VERSION ""

NS_ :

BS_:

BU_: SCCM RF_HUB PTS ORC OCM IC HCP HALF ETM ESM ESC EPS ECM EBCM DIAGNOST DASM CBC AirSusp TCM DTCM ELSDM

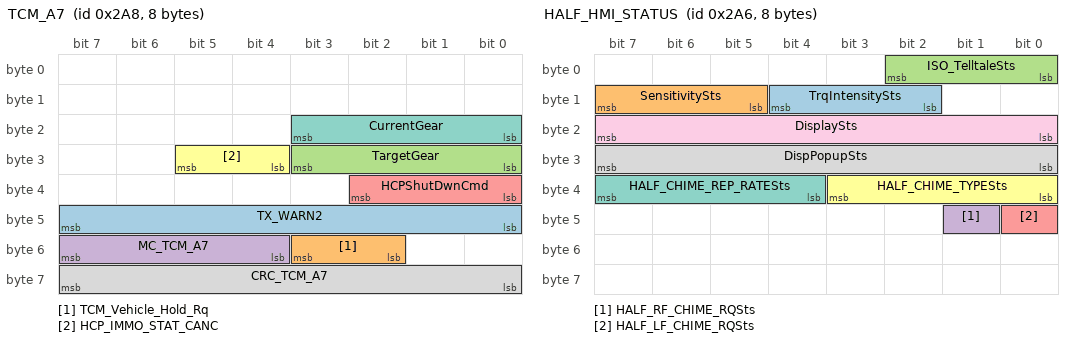
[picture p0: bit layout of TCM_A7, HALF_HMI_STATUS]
BO_ 680 TCM_A7: 8 TCM
 SG_ TX_WARN2 : 40|8@1+ (1,0) [0|0] ""  IC
 SG_ TCM_Vehicle_Hold_Rq : 50|2@1+ (1,0) [0|0] ""  ESC
 SG_ TargetGear : 24|4@1+ (1,0) [0|0] "" Vector__XXX
 SG_ MC_TCM_A7 : 52|4@1+ (1,0) [0|15] ""  ESC,ECM,DASM
 SG_ HCPShutDwnCmd : 32|3@1+ (1,0) [0|0] ""  CBC
 SG_ HCP_IMMO_STAT_CANC : 28|2@1+ (1,0) [0|0] ""  ECM,CBC
 SG_ CurrentGear : 16|4@1+ (1,0) [0|0] "" Vector__XXX
 SG_ CRC_TCM_A7 : 56|8@1+ (1,0) [0|0] ""  ESC,ECM,DASM

BO_ 678 HALF_HMI_STATUS: 8 HALF
 SG_ TrqIntensitySts : 10|3@1+ (1,0) [0|0] ""  IC
 SG_ SensitivitySts : 13|3@1+ (1,0) [0|0] ""  IC
 SG_ ISO_TelltaleSts : 0|3@1+ (1,0) [0|0] ""  ORC,IC
 SG_ HALF_RF_CHIME_RQSts : 41|1@1+ (1,0) [0|0] ""  CBC
 SG_ HALF_LF_CHIME_RQSts : 40|1@1+ (1,0) [0|0] ""  CBC
 SG_ HALF_CHIME_TYPESts : 32|4@1+ (1,0) [0|0] ""  CBC
 SG_ HALF_CHIME_REP_RATESts : 36|4@1+ (1,0) [0|15] ""  CBC
 SG_ DispPopupSts : 24|8@1+ (1,0) [0|0] ""  ORC,IC
 SG_ DisplaySts : 16|8@1+ (1,0) [0|0] ""  ORC,IC

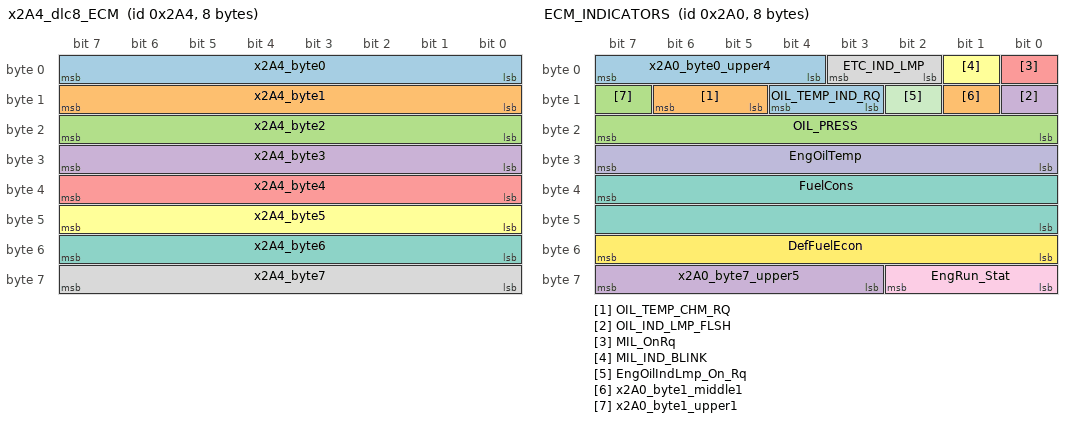
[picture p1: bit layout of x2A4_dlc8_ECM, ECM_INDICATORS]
BO_ 676 x2A4_dlc8_ECM: 8 ECM
 SG_ x2A4_byte0 : 0|8@1+ (1,0) [0|255] "" Vector__XXX
 SG_ x2A4_byte1 : 8|8@1+ (1,0) [0|255] "" Vector__XXX
 SG_ x2A4_byte2 : 16|8@1+ (1,0) [0|255] "" Vector__XXX
 SG_ x2A4_byte3 : 24|8@1+ (1,0) [0|255] "" Vector__XXX
 SG_ x2A4_byte4 : 32|8@1+ (1,0) [0|255] "" Vector__XXX
 SG_ x2A4_byte5 : 40|8@1+ (1,0) [0|255] "" Vector__XXX
 SG_ x2A4_byte6 : 48|8@1+ (1,0) [0|255] "" Vector__XXX
 SG_ x2A4_byte7 : 56|8@1+ (1,0) [0|255] "" Vector__XXX

BO_ 672 ECM_INDICATORS: 8 ECM
 SG_ OIL_TEMP_IND_RQ : 11|2@1+ (1,0) [0|0] ""  IC,ETM
 SG_ OIL_TEMP_CHM_RQ : 13|2@1+ (1,0) [0|0] ""  IC
 SG_ OIL_PRESS : 16|8@1+ (4,0) [0|1016] "kPaG"  IC,ETM
 SG_ OIL_IND_LMP_FLSH : 8|1@1+ (1,0) [0|0] ""  IC,ETM
 SG_ MIL_OnRq : 0|1@1+ (1,0) [0|0] ""  ORC,IC,ETM,CBC
 SG_ MIL_IND_BLINK : 1|1@1+ (1,0) [0|0] ""  ORC,IC,CBC
 SG_ FuelCons : 39|16@0+ (0.21668,0) [0|14200] "µl/100ms"  IC,ETM
 SG_ ETC_IND_LMP : 2|2@1+ (1,0) [0|0] ""  IC,ETM,CBC
 SG_ EngRun_Stat : 56|3@1+ (1,0) [0|0] ""  RF_HUB,PTS,IC,ESC,CBC
 SG_ EngOilTemp : 24|8@1+ (1,-40) [-40|160] "°C"  IC,ETM,EPS
 SG_ EngOilIndLmp_On_Rq : 10|1@1+ (1,0) [0|0] ""  IC,ETM,CBC
 SG_ DefFuelEcon : 48|8@1+ (0.2,0) [0|50] "kmpl"  IC
 SG_ x2A0_byte0_upper4 : 4|4@1+ (1,0) [0|0] "" Vector__XXX
 SG_ x2A0_byte1_middle1 : 9|1@1+ (1,0) [0|0] "" Vector__XXX
 SG_ x2A0_byte1_upper1 : 15|1@1+ (1,0) [0|0] "" Vector__XXX
 SG_ x2A0_byte7_upper5 : 59|5@1+ (1,0) [0|0] "" Vector__XXX

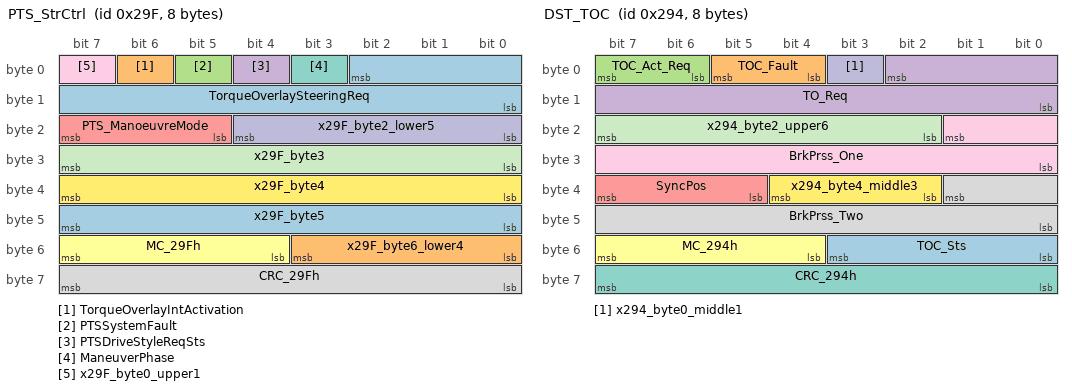
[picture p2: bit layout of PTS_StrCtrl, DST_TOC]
BO_ 671 PTS_StrCtrl: 8 PTS
 SG_ TorqueOverlaySteeringReq : 2|11@0+ (0.0078125,-8) [-8|7.9921875] "Nm"  EPS
 SG_ TorqueOverlayIntActivation : 6|1@1+ (1,0) [0|0] ""  EPS
 SG_ PTSSystemFault : 5|1@1+ (1,0) [0|0] ""  EPS
 SG_ PTSDriveStyleReqSts : 4|1@1+ (1,0) [0|0] ""  EPS
 SG_ PTS_ManoeuvreMode : 21|3@1+ (1,0) [0|0] ""  IC
 SG_ MC_29Fh : 52|4@1+ (1,0) [0|15] ""  EPS
 SG_ ManeuverPhase : 3|1@1+ (1,0) [0|0] ""  EPS
 SG_ CRC_29Fh : 56|8@1+ (1,0) [0|0] ""  EPS
 SG_ x29F_byte0_upper1 : 7|1@1+ (1,0) [0|1] "" Vector__XXX
 SG_ x29F_byte2_lower5 : 16|5@1+ (1,0) [0|31] "" Vector__XXX
 SG_ x29F_byte3 : 24|8@1+ (1,0) [0|255] "" Vector__XXX
 SG_ x29F_byte4 : 32|8@1+ (1,0) [0|255] "" Vector__XXX
 SG_ x29F_byte5 : 40|8@1+ (1,0) [0|255] "" Vector__XXX
 SG_ x29F_byte6_lower4 : 48|4@1+ (1,0) [0|15] "" Vector__XXX

BO_ 660 DST_TOC: 8 ESC
 SG_ TOC_Sts : 48|4@1+ (1,0) [0|0] ""  ORC,EPS
 SG_ TOC_Fault : 4|2@1+ (1,0) [0|0] ""  ORC,EPS
 SG_ TOC_Act_Req : 6|2@1+ (1,0) [0|0] ""  EPS
 SG_ TO_Req : 2|11@0+ (0.0078125,-8) [-8|7.984375] "Nm"  ORC,EPS
 SG_ SyncPos : 37|3@1+ (1,0) [0|0] "" Vector__XXX
 SG_ MC_294h : 52|4@1+ (1,0) [0|15] ""  EPS
 SG_ CRC_294h : 56|8@1+ (1,0) [0|0] ""  EPS
 SG_ BrkPrss_Two : 33|10@0+ (0.0048828125,0) [0|4.9951171875] "Volts" Vector__XXX
 SG_ BrkPrss_One : 17|10@0+ (0.0048828125,0) [0|4.9951171875] "Volts" Vector__XXX
 SG_ x294_byte0_middle1 : 3|1@1+ (1,0) [0|1] "" Vector__XXX
 SG_ x294_byte2_upper6 : 18|6@1+ (1,0) [0|63] "" Vector__XXX
 SG_ x294_byte4_middle3 : 34|3@1+ (1,0) [0|7] "" Vector__XXX

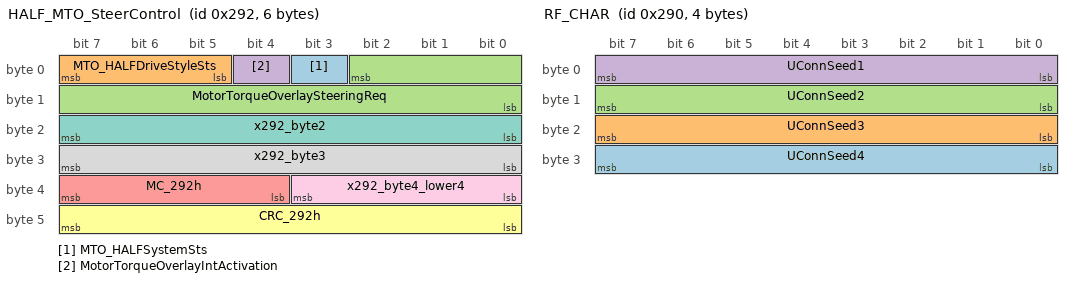
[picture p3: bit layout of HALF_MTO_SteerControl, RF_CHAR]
BO_ 658 HALF_MTO_SteerControl: 6 HALF
 SG_ MTO_HALFSystemSts : 3|1@1+ (1,0) [0|0] ""  EPS
 SG_ MTO_HALFDriveStyleSts : 5|3@1+ (1,0) [0|0] ""  EPS
 SG_ MotorTorqueOverlaySteeringReq : 2|11@0+ (0.001953125,-2) [-2|1.998047] "Nm"  EPS
 SG_ MotorTorqueOverlayIntActivation : 4|1@1+ (1,0) [0|0] ""  EPS
 SG_ MC_292h : 36|4@1+ (1,0) [0|15] ""  EPS
 SG_ CRC_292h : 40|8@1+ (1,0) [0|0] ""  EPS
 SG_ x292_byte2 : 16|8@1+ (1,0) [0|255] "" Vector__XXX
 SG_ x292_byte3 : 24|8@1+ (1,0) [0|255] "" Vector__XXX
 SG_ x292_byte4_lower4 : 32|4@1+ (1,0) [0|15] "" Vector__XXX

BO_ 656 RF_CHAR: 4 RF_HUB
 SG_ UConnSeed4 : 24|8@1+ (1,0) [0|0] ""  ETM
 SG_ UConnSeed3 : 16|8@1+ (1,0) [0|0] ""  ETM
 SG_ UConnSeed2 : 8|8@1+ (1,0) [0|0] ""  ETM
 SG_ UConnSeed1 : 0|8@1+ (1,0) [0|0] ""  ETM

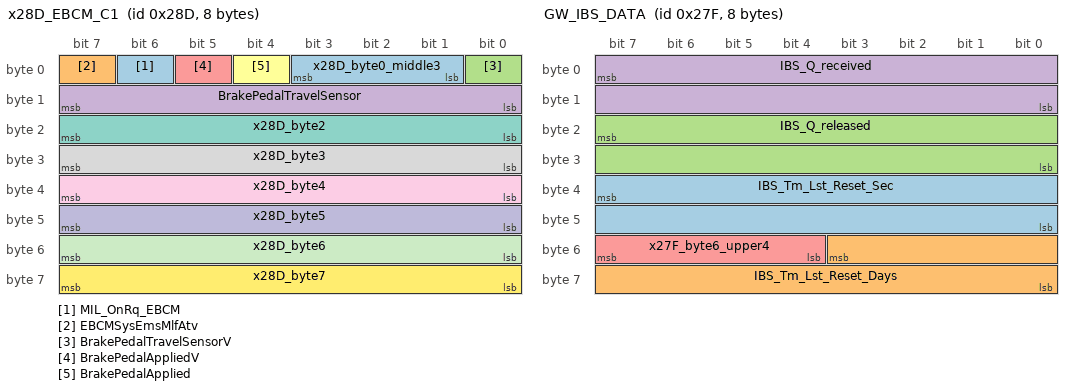
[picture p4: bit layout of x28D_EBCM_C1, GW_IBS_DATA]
BO_ 653 x28D_EBCM_C1: 8 EBCM
 SG_ MIL_OnRq_EBCM : 6|1@1+ (1,0) [0|0] ""  ECM
 SG_ EBCMSysEmsMlfAtv : 7|1@1+ (1,0) [0|0] "" Vector__XXX
 SG_ BrakePedalTravelSensorV : 0|1@1+ (1,0) [0|0] ""  ESC,ECM
 SG_ BrakePedalTravelSensor : 8|8@1+ (0.4,0) [0|100] "%"  ESC,ECM
 SG_ BrakePedalAppliedV : 5|1@1+ (1,0) [0|0] ""  ESC,ECM
 SG_ BrakePedalApplied : 4|1@1+ (1,0) [0|0] ""  ESC,ECM
 SG_ x28D_byte2 : 16|8@1+ (1,0) [0|0] "" Vector__XXX
 SG_ x28D_byte3 : 24|8@1+ (1,0) [0|0] "" Vector__XXX
 SG_ x28D_byte4 : 32|8@1+ (1,0) [0|0] "" Vector__XXX
 SG_ x28D_byte5 : 40|8@1+ (1,0) [0|0] "" Vector__XXX
 SG_ x28D_byte6 : 48|8@1+ (1,0) [0|0] "" Vector__XXX
 SG_ x28D_byte7 : 56|8@1+ (1,0) [0|0] "" Vector__XXX
 SG_ x28D_byte0_middle3 : 1|3@1+ (1,0) [0|0] "" Vector__XXX

BO_ 639 GW_IBS_DATA: 8 CBC
 SG_ IBS_Tm_Lst_Reset_Sec : 39|16@0+ (2,0) [0|86398] "sec" Vector__XXX
 SG_ IBS_Tm_Lst_Reset_Days : 51|12@0+ (1,0) [0|4094] "Days" Vector__XXX
 SG_ IBS_Q_released : 23|16@0+ (0.125,0) [0|8191.75] "Ah" Vector__XXX
 SG_ IBS_Q_received : 7|16@0+ (0.125,0) [0|8191.75] "Ah" Vector__XXX
 SG_ x27F_byte6_upper4 : 55|4@0+ (1,0) [0|15] "" Vector__XXX

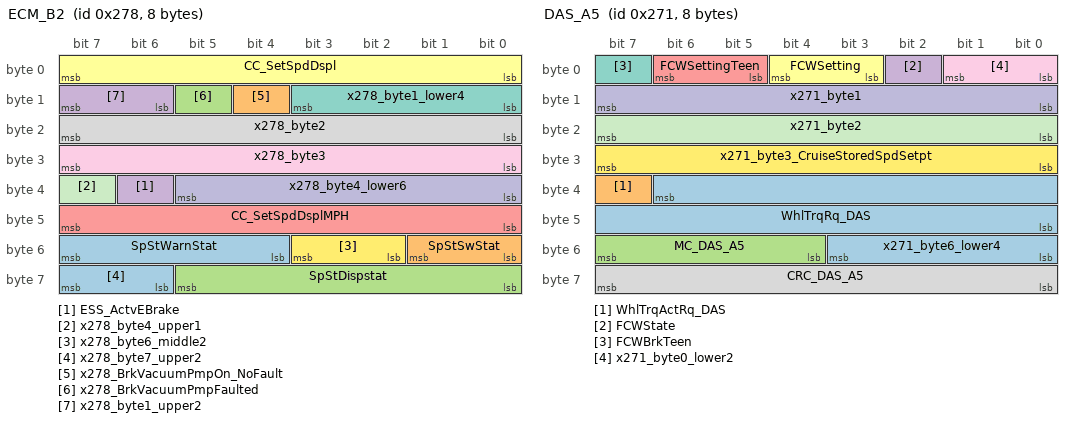
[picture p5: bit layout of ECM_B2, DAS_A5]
BO_ 632 ECM_B2: 8 ECM
 SG_ SpStWarnStat : 52|4@1+ (1,0) [0|0] ""  ORC
 SG_ SpStSwStat : 48|2@1+ (1,0) [0|0] ""  ORC,CBC
 SG_ SpStDispstat : 56|6@1+ (1,0) [0|0] ""  ORC
 SG_ ESS_ActvEBrake : 38|1@1+ (1,0) [0|0] ""  ORC,ESC
 SG_ CC_SetSpdDsplMPH : 40|8@1+ (1,0) [0|254] "mph"  IC
 SG_ CC_SetSpdDspl : 0|8@1+ (1,0) [0|250] "km/h"  IC
 SG_ x278_byte1_lower4 : 8|4@1+ (1,0) [0|15] "" Vector__XXX
 SG_ x278_byte2 : 16|8@1+ (1,0) [0|255] "" Vector__XXX
 SG_ x278_byte3 : 24|8@1+ (1,0) [0|255] "" Vector__XXX
 SG_ x278_byte4_lower6 : 32|6@1+ (1,0) [0|63] "" Vector__XXX
 SG_ x278_byte4_upper1 : 39|1@1+ (1,0) [0|1] "" Vector__XXX
 SG_ x278_byte6_middle2 : 50|2@1+ (1,0) [0|3] "" Vector__XXX
 SG_ x278_byte7_upper2 : 62|2@1+ (1,0) [0|3] "" Vector__XXX
 SG_ x278_BrkVacuumPmpOn_NoFault : 12|1@1+ (1,0) [0|1] "" Vector__XXX
 SG_ x278_BrkVacuumPmpFaulted : 13|1@1+ (1,0) [0|1] "" Vector__XXX
 SG_ x278_byte1_upper2 : 14|2@1+ (1,0) [0|3] "" Vector__XXX

BO_ 625 DAS_A5: 8 DASM
 SG_ WhlTrqRq_DAS : 38|15@0+ (1,-7767) [-7767|24999] "Nm"  ESC
 SG_ WhlTrqActRq_DAS : 39|1@1+ (1,0) [0|0] ""  ESC
 SG_ MC_DAS_A5 : 52|4@1+ (1,0) [0|15] ""  ESC
 SG_ FCWState : 2|1@1+ (1,0) [0|0] ""  ORC,IC,CBC
 SG_ FCWSettingTeen : 5|2@1+ (1,0) [0|0] ""  ORC,CBC
 SG_ FCWSetting : 3|2@1+ (1,0) [0|0] ""  ORC,CBC
 SG_ FCWBrkTeen : 7|1@1+ (1,0) [0|0] ""  ORC,CBC
 SG_ CRC_DAS_A5 : 56|8@1+ (1,0) [0|255] ""  ESC
 SG_ x271_byte0_lower2 : 0|2@1+ (1,0) [0|2] "" Vector__XXX
 SG_ x271_byte1 : 8|8@1+ (1,0) [0|255] "" Vector__XXX
 SG_ x271_byte2 : 16|8@1+ (1,0) [0|255] "" Vector__XXX
 SG_ x271_byte3_CruiseStoredSpdSetpt : 24|8@1+ (1,0) [0|255] "kph" Vector__XXX
 SG_ x271_byte6_lower4 : 48|4@1+ (1,0) [0|15] "" Vector__XXX

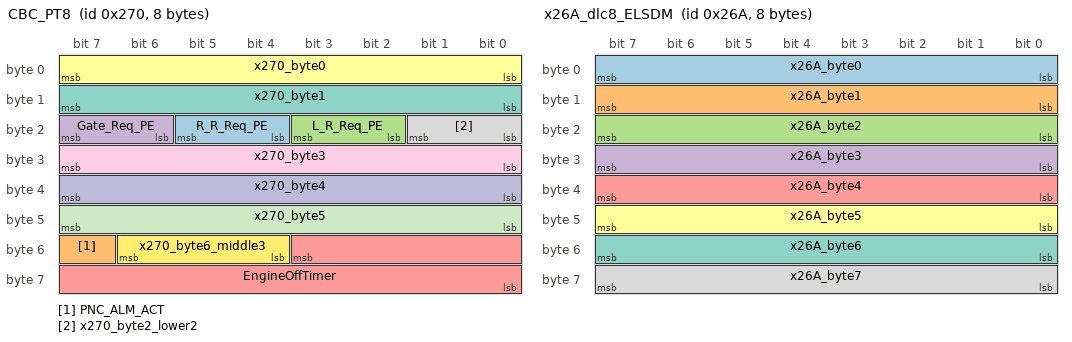
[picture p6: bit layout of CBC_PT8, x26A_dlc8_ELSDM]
BO_ 624 CBC_PT8: 8 CBC
 SG_ R_R_Req_PE : 20|2@1+ (1,0) [0|0] ""  RF_HUB
 SG_ PNC_ALM_ACT : 55|1@1+ (1,0) [0|0] "" Vector__XXX
 SG_ L_R_Req_PE : 18|2@1+ (1,0) [0|0] ""  RF_HUB
 SG_ Gate_Req_PE : 22|2@1+ (1,0) [0|0] ""  RF_HUB
 SG_ EngineOffTimer : 51|12@0+ (1,0) [0|4080] "min"  ETM,ECM
 SG_ x270_byte0 : 0|8@1+ (1,0) [0|255] "" Vector__XXX
 SG_ x270_byte1 : 8|8@1+ (1,0) [0|255] "" Vector__XXX
 SG_ x270_byte2_lower2 : 16|2@1+ (1,0) [0|3] "" Vector__XXX
 SG_ x270_byte3 : 24|8@1+ (1,0) [0|255] "" Vector__XXX
 SG_ x270_byte4 : 32|8@1+ (1,0) [0|255] "" Vector__XXX
 SG_ x270_byte5 : 40|8@1+ (1,0) [0|255] "" Vector__XXX
 SG_ x270_byte6_middle3 : 52|3@1+ (1,0) [0|7] "" Vector__XXX

BO_ 618 x26A_dlc8_ELSDM: 8 ELSDM
 SG_ x26A_byte0 : 0|8@1+ (1,0) [0|255] "" Vector__XXX
 SG_ x26A_byte1 : 8|8@1+ (1,0) [0|255] "" Vector__XXX
 SG_ x26A_byte2 : 16|8@1+ (1,0) [0|255] "" Vector__XXX
 SG_ x26A_byte3 : 24|8@1+ (1,0) [0|255] "" Vector__XXX
 SG_ x26A_byte4 : 32|8@1+ (1,0) [0|255] "" Vector__XXX
 SG_ x26A_byte5 : 40|8@1+ (1,0) [0|255] "" Vector__XXX
 SG_ x26A_byte6 : 48|8@1+ (1,0) [0|255] "" Vector__XXX
 SG_ x26A_byte7 : 56|8@1+ (1,0) [0|255] "" Vector__XXX

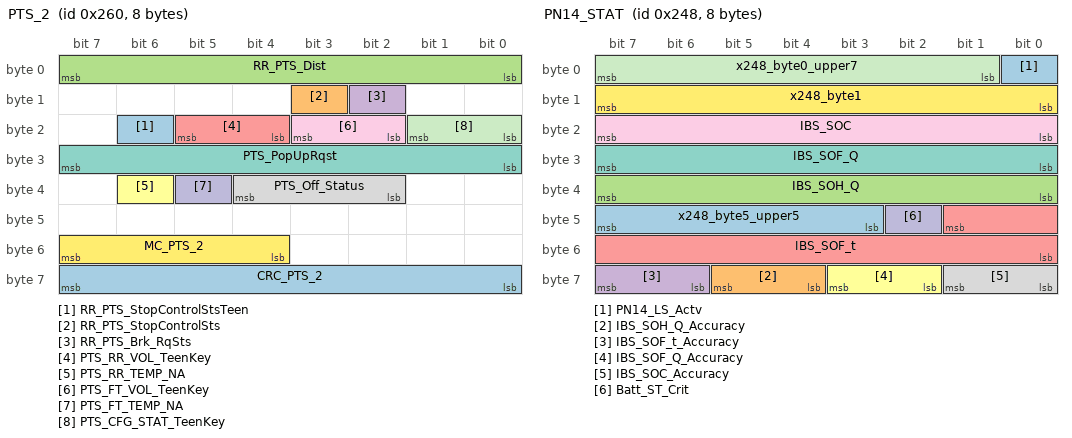
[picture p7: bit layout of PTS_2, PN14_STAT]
BO_ 608 PTS_2: 8 PTS
 SG_ RR_PTS_StopControlStsTeen : 22|1@1+ (1,0) [0|0] ""  IC,CBC
 SG_ RR_PTS_StopControlSts : 11|1@1+ (1,0) [0|0] ""  IC,CBC
 SG_ RR_PTS_Dist : 0|8@1+ (1,0) [0|254] "cm"  ESC
 SG_ RR_PTS_Brk_RqSts : 10|1@1+ (1,0) [0|0] ""  ESC
 SG_ PTS_RR_VOL_TeenKey : 20|2@1+ (1,0) [0|0] ""  CBC
 SG_ PTS_RR_TEMP_NA : 38|1@1+ (1,0) [0|0] ""  IC
 SG_ PTS_PopUpRqst : 24|8@1+ (1,0) [0|0] ""  IC
 SG_ PTS_Off_Status : 34|3@1+ (1,0) [0|0] ""  IC
 SG_ PTS_FT_VOL_TeenKey : 18|2@1+ (1,0) [0|0] ""  CBC
 SG_ PTS_FT_TEMP_NA : 37|1@1+ (1,0) [0|0] ""  IC
 SG_ PTS_CFG_STAT_TeenKey : 16|2@1+ (1,0) [0|0] ""  CBC
 SG_ MC_PTS_2 : 52|4@1+ (1,0) [0|15] ""  ESC
 SG_ CRC_PTS_2 : 56|8@1+ (1,0) [0|0] ""  ESC

BO_ 584 PN14_STAT: 8 CBC
 SG_ PN14_LS_Actv : 0|1@1+ (1,0) [0|0] ""  IC
 SG_ IBS_SOH_Q_Accuracy : 60|2@1+ (1,0) [0|0] "" Vector__XXX
 SG_ IBS_SOH_Q : 32|8@1+ (0.5,0) [0|127] "Ah" Vector__XXX
 SG_ IBS_SOF_t_Accuracy : 62|2@1+ (1,0) [0|0] "" Vector__XXX
 SG_ IBS_SOF_t : 41|10@0+ (1,0) [0|1022] "min" Vector__XXX
 SG_ IBS_SOF_Q_Accuracy : 58|2@1+ (1,0) [0|0] "" Vector__XXX
 SG_ IBS_SOF_Q : 24|8@1+ (0.5,0) [0|127] "Ah" Vector__XXX
 SG_ IBS_SOC_Accuracy : 56|2@1+ (1,0) [0|0] ""  HCP
 SG_ IBS_SOC : 16|8@1+ (1,0) [0|100] "%"  ORC,HCP,ETM
 SG_ Batt_ST_Crit : 42|1@1+ (1,0) [0|0] ""  IC
 SG_ x248_byte0_upper7 : 1|7@1+ (1,0) [0|127] "" Vector__XXX
 SG_ x248_byte1 : 8|8@1+ (1,0) [0|255] "" Vector__XXX
 SG_ x248_byte5_upper5 : 43|5@1+ (1,0) [0|31] "" Vector__XXX

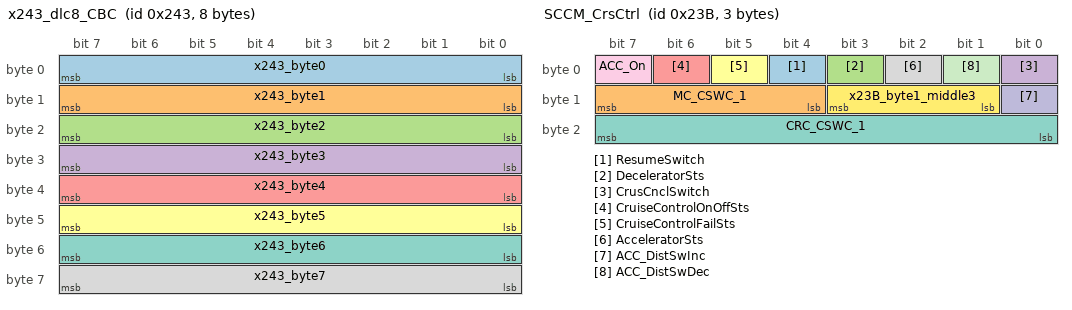
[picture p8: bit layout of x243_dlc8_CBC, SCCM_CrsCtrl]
BO_ 579 x243_dlc8_CBC: 8 CBC
 SG_ x243_byte0 : 0|8@1+ (1,0) [0|255] "" Vector__XXX
 SG_ x243_byte1 : 8|8@1+ (1,0) [0|255] "" Vector__XXX
 SG_ x243_byte2 : 16|8@1+ (1,0) [0|255] "" Vector__XXX
 SG_ x243_byte3 : 24|8@1+ (1,0) [0|255] "" Vector__XXX
 SG_ x243_byte4 : 32|8@1+ (1,0) [0|255] "" Vector__XXX
 SG_ x243_byte5 : 40|8@1+ (1,0) [0|255] "" Vector__XXX
 SG_ x243_byte6 : 48|8@1+ (1,0) [0|255] "" Vector__XXX
 SG_ x243_byte7 : 56|8@1+ (1,0) [0|255] "" Vector__XXX

BO_ 571 SCCM_CrsCtrl: 3 SCCM
 SG_ ResumeSwitch : 4|1@1+ (1,0) [0|0] ""  ESC,ECM,DASM
 SG_ MC_CSWC_1 : 12|4@1+ (1,0) [0|15] ""  ECM
 SG_ DeceleratorSts : 3|1@1+ (1,0) [0|0] ""  ESC,ECM,DASM
 SG_ CrusCnclSwitch : 0|1@1+ (1,0) [0|0] ""  ESC,ECM,DASM
 SG_ CruiseControlOnOffSts : 6|1@1+ (1,0) [0|0] ""  ESC,ECM,DASM
 SG_ CruiseControlFailSts : 5|1@1+ (1,0) [0|0] ""  ESC,ECM,DASM
 SG_ CRC_CSWC_1 : 16|8@1+ (1,0) [0|0] ""  ECM
 SG_ AcceleratorSts : 2|1@1+ (1,0) [0|0] ""  ESC,ECM,DASM
 SG_ ACC_On : 7|1@1+ (1,0) [0|0] ""  ESC,DASM
 SG_ ACC_DistSwInc : 8|1@1+ (1,0) [0|0] ""  DASM
 SG_ ACC_DistSwDec : 1|1@1+ (1,0) [0|0] ""  DASM
 SG_ x23B_byte1_middle3 : 9|3@1+ (1,0) [0|7] "" Vector__XXX

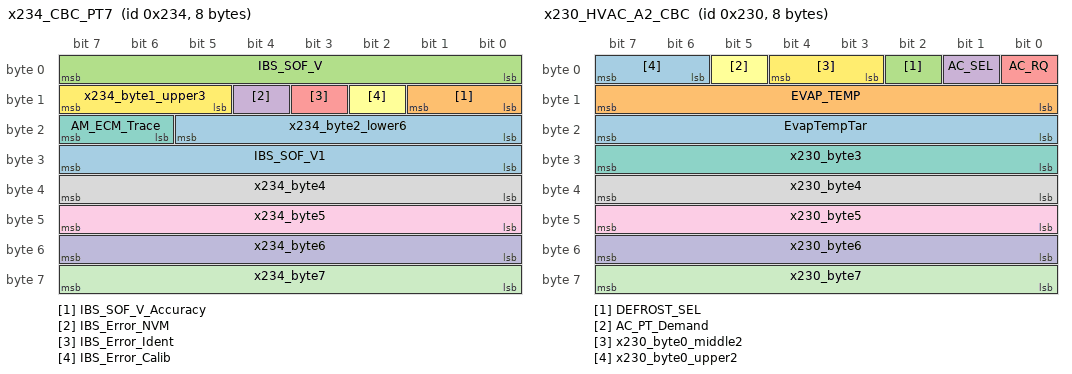
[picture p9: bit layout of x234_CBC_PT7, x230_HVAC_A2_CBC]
BO_ 564 x234_CBC_PT7: 8 CBC
 SG_ IBS_SOF_V1 : 24|8@1+ (0.0625,0) [0|15.875] "V" Vector__XXX
 SG_ IBS_SOF_V_Accuracy : 8|2@1+ (1,0) [0|0] "" Vector__XXX
 SG_ IBS_SOF_V : 0|8@1+ (0.0625,0) [0|15.875] "V" Vector__XXX
 SG_ IBS_Error_NVM : 12|1@1+ (1,0) [0|0] "" Vector__XXX
 SG_ IBS_Error_Ident : 11|1@1+ (1,0) [0|0] "" Vector__XXX
 SG_ IBS_Error_Calib : 10|1@1+ (1,0) [0|0] "" Vector__XXX
 SG_ AM_ECM_Trace : 22|2@1+ (1,0) [0|0] ""  ECM
 SG_ x234_byte4 : 32|8@1+ (1,0) [0|255] "" Vector__XXX
 SG_ x234_byte5 : 40|8@1+ (1,0) [0|255] "" Vector__XXX
 SG_ x234_byte6 : 48|8@1+ (1,0) [0|255] "" Vector__XXX
 SG_ x234_byte7 : 56|8@1+ (1,0) [0|255] "" Vector__XXX
 SG_ x234_byte1_upper3 : 13|3@1+ (1,0) [0|7] "" Vector__XXX
 SG_ x234_byte2_lower6 : 16|6@1+ (1,0) [0|63] "" Vector__XXX

BO_ 560 x230_HVAC_A2_CBC: 8 CBC
 SG_ EvapTempTar : 16|8@1+ (0.5,-20) [-20|107] "°C"  HCP
 SG_ EVAP_TEMP : 8|8@1+ (0.5,-20) [-20|107] "°C"  HCP
 SG_ DEFROST_SEL : 2|1@1+ (1,0) [0|0] "" Vector__XXX
 SG_ AC_SEL : 1|1@1+ (1,0) [0|0] "" Vector__XXX
 SG_ AC_RQ : 0|1@1+ (1,0) [0|0] ""  HCP
 SG_ AC_PT_Demand : 5|1@1+ (1,0) [0|0] ""  ECM
 SG_ x230_byte3 : 24|8@1+ (1,0) [0|255] "" Vector__XXX
 SG_ x230_byte4 : 32|8@1+ (1,0) [0|255] "" Vector__XXX
 SG_ x230_byte5 : 40|8@1+ (1,0) [0|255] "" Vector__XXX
 SG_ x230_byte6 : 48|8@1+ (1,0) [0|255] "" Vector__XXX
 SG_ x230_byte7 : 56|8@1+ (1,0) [0|255] "" Vector__XXX
 SG_ x230_byte0_middle2 : 3|2@1+ (1,0) [0|0] "" Vector__XXX
 SG_ x230_byte0_upper2 : 6|2@1+ (1,0) [0|0] "" Vector__XXX

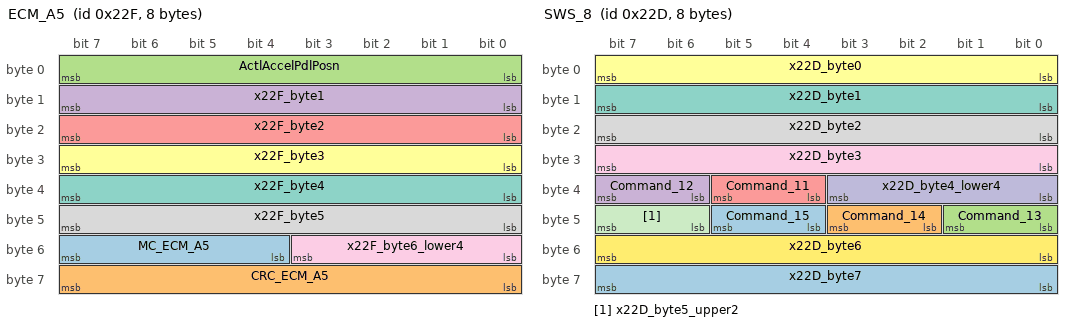
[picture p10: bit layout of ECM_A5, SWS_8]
BO_ 559 ECM_A5: 8 ECM
 SG_ MC_ECM_A5 : 52|4@1+ (1,0) [0|15] ""  ESC,DASM
 SG_ CRC_ECM_A5 : 56|8@1+ (1,0) [0|0] ""  ESC,DASM
 SG_ ActlAccelPdlPosn : 0|8@1+ (0.4,0) [0|100] "%"  ORC,HALF,ESC,DASM
 SG_ x22F_byte1 : 8|8@1+ (1,0) [0|0] "" Vector__XXX
 SG_ x22F_byte2 : 16|8@1+ (1,0) [0|0] "" Vector__XXX
 SG_ x22F_byte3 : 24|8@1+ (1,0) [0|0] "" Vector__XXX
 SG_ x22F_byte4 : 32|8@1+ (1,0) [0|0] "" Vector__XXX
 SG_ x22F_byte5 : 40|8@1+ (1,0) [0|0] "" Vector__XXX
 SG_ x22F_byte6_lower4 : 48|4@1+ (1,0) [0|0] "" Vector__XXX

BO_ 557 SWS_8: 8 CBC
 SG_ Command_15 : 44|2@1+ (1,0) [0|0] ""  IC
 SG_ Command_14 : 42|2@1+ (1,0) [0|0] ""  IC
 SG_ Command_13 : 40|2@1+ (1,0) [0|0] ""  IC
 SG_ Command_12 : 38|2@1+ (1,0) [0|0] ""  IC
 SG_ Command_11 : 36|2@1+ (1,0) [0|0] ""  IC
 SG_ x22D_byte0 : 0|8@1+ (1,0) [0|255] "" Vector__XXX
 SG_ x22D_byte1 : 8|8@1+ (1,0) [0|255] "" Vector__XXX
 SG_ x22D_byte2 : 16|8@1+ (1,0) [0|255] "" Vector__XXX
 SG_ x22D_byte3 : 24|8@1+ (1,0) [0|255] "" Vector__XXX
 SG_ x22D_byte4_lower4 : 32|4@1+ (1,0) [0|15] "" Vector__XXX
 SG_ x22D_byte5_upper2 : 46|2@1+ (1,0) [0|3] "" Vector__XXX
 SG_ x22D_byte6 : 48|8@1+ (1,0) [0|255] "" Vector__XXX
 SG_ x22D_byte7 : 56|8@1+ (1,0) [0|255] "" Vector__XXX

BO_ 544 EPS_1: 8 EPS
 SG_ TOI_Act_Sts : 3|4@1+ (1,0) [0|0] ""  ORC,ESC
 SG_ StrClmTrqVD : 7|1@1+ (1,0) [0|0] ""  HALF,ECM,ESC,PTS
 SG_ StrClmTrq : 2|11@0+ (0.0078125,-8) [-8|7.98] "Nm"  PTS,ORC,HALF,ESC,ECM
 SG_ PTSTorqueOverlayIntActivated : 51|1@1+ (1,0) [0|0] ""  PTS
 SG_ PTSTorqueOverlayFault : 50|1@1+ (1,0) [0|0] ""  PTS
 SG_ PTSDriveStyleSts : 20|1@1+ (1,0) [0|0] ""  PTS
 SG_ MC_EPS_1 : 52|4@1+ (1,0) [0|15] ""  HALF,ECM,ESC,PTS
 SG_ HALFTorqueOverlayIntActivated : 23|1@1+ (1,0) [0|0] ""  ORC,HALF
 SG_ HALFTorqueOverlayFault : 22|1@1+ (1,0) [0|0] ""  HALF
 SG_ EPSTemporaryDeactivationPPPA : 49|1@1+ (1,0) [0|0] ""  PTS
 SG_ EPSTemporaryDeactivationLDW : 38|1@1+ (1,0) [0|0] ""  HALF
 SG_ EPSMotorTorqueValidData : 39|1@1+ (1,0) [0|0] ""  HALF
 SG_ EPSMotorTorque : 34|11@0+ (0.001953125,-2) [-2|1.998047] "Nm"  ORC,HALF
 SG_ EPSHandsOnRecognition : 48|1@1+ (1,0) [0|0] ""  PTS
 SG_ DSTTorqueOverlayIntActivated : 37|1@1+ (1,0) [0|0] ""  HALF,ESC
 SG_ DSTTorqueOverlayFault : 21|1@1+ (1,0) [0|0] ""  HALF,ESC
 SG_ CRC_EPS_1 : 56|8@1+ (1,0) [0|0] ""  HALF,ECM,ESC,PTS
 SG_ AssistanceTorque : 19|12@0+ (0.05,-100) [-100|104.65] "Nm"  ESC
 SG_ x220_byte4_middle2 : 35|2@1+ (1,0) [0|3] "" Vector__XXX

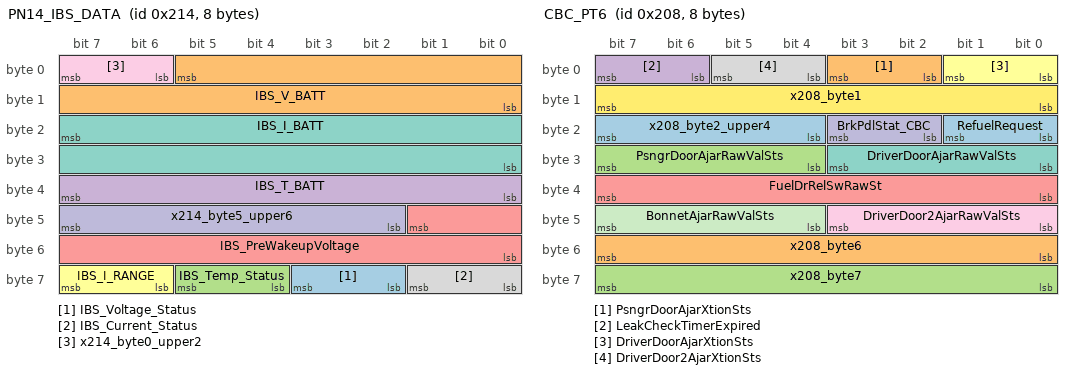
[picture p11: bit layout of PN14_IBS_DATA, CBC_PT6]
BO_ 532 PN14_IBS_DATA: 8 CBC
 SG_ IBS_Voltage_Status : 58|2@1+ (1,0) [0|0] ""  HCP
 SG_ IBS_V_BATT : 5|14@0+ (0.0009765625,3) [3|18] "Volts"  ORC,HCP,ETM
 SG_ IBS_Temp_Status : 60|2@1+ (1,0) [0|0] ""  HCP
 SG_ IBS_T_BATT : 32|8@1+ (1,-40) [-40|105] "°C"  HCP,ETM
 SG_ IBS_PreWakeupVoltage : 41|10@0+ (0.01,5) [5|15] "V" Vector__XXX
 SG_ IBS_I_RANGE : 62|2@1+ (1,0) [0|0] "Amp" Vector__XXX
 SG_ IBS_I_BATT : 23|16@0+ (1,-32768) [-32768|32766] "I_RANGE res." Vector__XXX
 SG_ IBS_Current_Status : 56|2@1+ (1,0) [0|0] "" Vector__XXX
 SG_ x214_byte0_upper2 : 6|2@1+ (1,0) [0|3] "" Vector__XXX
 SG_ x214_byte5_upper6 : 42|6@1+ (1,0) [0|63] "" Vector__XXX

BO_ 520 CBC_PT6: 8 CBC
 SG_ RefuelRequest : 16|2@1+ (1,0) [0|0] ""  ECM
 SG_ PsngrDoorAjarXtionSts : 2|2@1+ (1,0) [0|0] "" Vector__XXX
 SG_ PsngrDoorAjarRawValSts : 28|4@1+ (1,0) [0|0] ""  ORC,ECM
 SG_ LeakCheckTimerExpired : 6|2@1+ (1,0) [0|0] ""  ECM
 SG_ FuelDrRelSwRawSt : 32|8@1+ (0.019607843,0) [0|4.98] "Volts"  ECM
 SG_ DriverDoorAjarXtionSts : 0|2@1+ (1,0) [0|0] ""  ESC,ECM
 SG_ DriverDoorAjarRawValSts : 24|4@1+ (1,0) [0|0] ""  ORC,ESC,ECM
 SG_ DriverDoor2AjarXtionSts : 4|2@1+ (1,0) [0|0] ""  ECM
 SG_ DriverDoor2AjarRawValSts : 40|4@1+ (1,0) [0|0] ""  ORC,ECM
 SG_ BrkPdlStat_CBC : 18|2@1+ (1,0) [0|0] ""  RF_HUB
 SG_ BonnetAjarRawValSts : 44|4@1+ (1,0) [0|0] ""  ORC,ECM
 SG_ x208_byte1 : 8|8@1+ (1,0) [0|255] "" Vector__XXX
 SG_ x208_byte2_upper4 : 20|4@1+ (1,0) [0|15] "" Vector__XXX
 SG_ x208_byte6 : 48|8@1+ (1,0) [0|255] "" Vector__XXX
 SG_ x208_byte7 : 56|8@1+ (1,0) [0|255] "" Vector__XXX

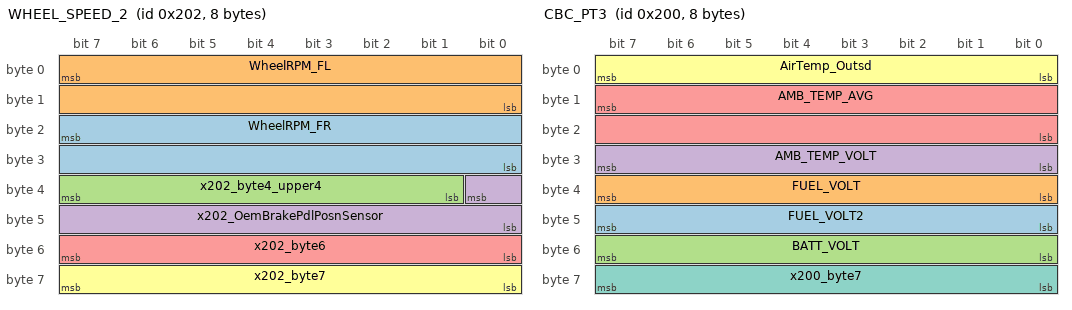
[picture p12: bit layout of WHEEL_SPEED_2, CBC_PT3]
BO_ 514 WHEEL_SPEED_2: 8 ESC
 SG_ WheelRPM_FR : 23|16@0+ (0.001953125,0) [0|127.9961] "Rev/s"  EPS
 SG_ WheelRPM_FL : 7|16@0+ (0.001953125,0) [0|127.9961] "Rev/s"  EPS
 SG_ x202_byte4_upper4 : 39|7@0+ (1,0) [0|15] "" Vector__XXX
 SG_ x202_OemBrakePdlPosnSensor : 32|9@0+ (0.0048261802575,0) [0|5] "V" Vector__XXX
 SG_ x202_byte6 : 55|8@0+ (1,0) [0|255] "" Vector__XXX
 SG_ x202_byte7 : 63|8@0+ (1,0) [0|255] "" Vector__XXX

BO_ 512 CBC_PT3: 8 CBC
 SG_ FUEL_VOLT2 : 40|8@1+ (0.019607843,0) [0|4.98] "Volts"  IC
 SG_ FUEL_VOLT : 32|8@1+ (0.019607843,0) [0|4.98] "Volts"  IC,ECM
 SG_ BATT_VOLT : 48|8@1+ (0.1,0) [5|18] "Volts"  SCCM,RF_HUB,PTS,ORC,OCM,IC,HCP,HALF,ESM,ESC,EPS,ECM,EBCM,DASM
 SG_ AMB_TEMP_VOLT : 24|8@1+ (0.019607843,0) [0|4.98] "Volts"  HCP,ECM
 SG_ AMB_TEMP_AVG : 15|16@0+ (0.01,-40) [-40|85] "°C"  RF_HUB,PTS,OCM,ESC,EPS,ECM,DASM
 SG_ AirTemp_Outsd : 0|8@1+ (0.5,-40) [-40|85] "°C"  RF_HUB,EPS,ECM,DASM
 SG_ x200_byte7 : 56|8@1+ (1,0) [0|255] "" Vector__XXX

BO_ 501 DAS_A4: 8 DASM
 SG_ Sm_ICON_Dspl : 40|6@1+ (1,0) [0|0] ""  IC
 SG_ SetSpeed_MPH : 16|8@1+ (1,0) [0|250] "mph"  ORC,IC
 SG_ SetSpeed_KPH : 8|8@1+ (1,0) [0|250] "km/h"  IC,ECM
 SG_ RadarBlocked : 46|1@1+ (1,0) [0|0] ""  ORC,IC
 SG_ ObjIntrstDist : 56|8@1+ (1,0) [0|253] "m"  ORC
 SG_ NCConlyNA_DASMSts : 49|1@1+ (1,0) [0|0] ""  IC
 SG_ NCCNA_DASMSts : 53|1@1+ (1,0) [0|0] ""  IC
 SG_ HMI_Screens : 0|8@1+ (1,0) [0|254] "Text"  ORC,IC
 SG_ FCWonlyNA_DASMSts : 51|1@1+ (1,0) [0|0] ""  IC
 SG_ FCWBrakingOff : 47|1@1+ (1,0) [0|0] ""  IC
 SG_ FCW_Error : 26|2@1+ (1,0) [0|0] ""  ORC,IC
 SG_ FCW_BrkOn : 29|1@1+ (1,0) [0|0] ""  ORC,CBC
 SG_ CIPV_Fused : 30|1@1+ (1,0) [0|0] ""  ORC
 SG_ CameraFailure : 55|1@1+ (1,0) [0|0] ""  IC
 SG_ CameraBlocked : 54|1@1+ (1,0) [0|0] ""  IC
 SG_ ACCOnOff : 36|3@1+ (1,0) [0|0] ""  ORC,IC
 SG_ ACConlyNA_DASMSts : 48|1@1+ (1,0) [0|0] ""  IC,ETM
 SG_ ACCNA_DASMSts : 52|1@1+ (1,0) [0|0] ""  IC
 SG_ ACCFaulted : 50|1@1+ (1,0) [0|0] ""  ORC,IC,ETM
 SG_ ACC_HMI_SCRN_REQ : 31|1@1+ (1,0) [0|0] ""  IC
 SG_ x1F5_byte3_lower2 : 24|2@1+ (1,0) [0|3] "" Vector__XXX
 SG_ x1F5_byte3_middle1 : 28|1@1+ (1,0) [0|1] "" Vector__XXX
 SG_ x1F5_byte4_lower4 : 32|4@1+ (1,0) [0|15] "" Vector__XXX
 SG_ x1F5_byte4_upper1 : 39|1@1+ (1,0) [0|1] "" Vector__XXX

BO_ 500 DAS_A3: 8 DASM
 SG_ MC_DAS_A3 : 52|4@1+ (1,0) [0|15] ""  ESC,ECM
 SG_ DsblFuelShutOff_ACC : 23|1@1+ (1,0) [0|0] ""  ESC
 SG_ DAS_Sts : 46|2@1+ (1,0) [0|0] ""  ESC
 SG_ DAS_Rq_ID : 36|3@1+ (1,0) [0|0] ""  ESC
 SG_ DAS_ACCEL_Rq : 19|12@0+ (0.004885,-16) [-16|4] "m/s²"  ORC,ESC
 SG_ CRC_DAS_A3 : 56|8@1+ (1,0) [0|0] ""  ESC
 SG_ Brk_PreFill_Rq : 49|1@1+ (1,0) [0|0] ""  ESC
 SG_ Brk_Jrk_Rq : 48|1@1+ (1,0) [0|0] ""  ESC
 SG_ As_DispRq : 50|2@1+ (1,0) [0|0] ""  ORC,IC,HALF,ESC
 SG_ ACCFCW_ChimeRq : 39|1@1+ (1,0) [0|0] ""  IC
 SG_ ACC_Still_Cmd : 5|1@1+ (1,0) [0|0] ""  ORC,ESC
 SG_ ACC_Engd : 21|1@1+ (1,0) [0|0] ""  IC,ESC
 SG_ ACC_Enbl : 20|1@1+ (1,0) [0|0] ""  IC,ESC
 SG_ ACC_Drive_Cmd : 6|1@1+ (1,0) [0|0] ""  ESC
 SG_ DAS_A3_unknownBigEndian : 4|13@0+ (1,0) [0|8192] "" Vector__XXX
 SG_ x1F4_byte0_upper1 : 7|1@1+ (1,0) [0|1] "" Vector__XXX
 SG_ x1F4_byte2_middle1 : 22|1@1+ (1,0) [0|1] "" Vector__XXX
 SG_ x1F4_byte4_lower4 : 32|4@1+ (1,0) [0|15] "" Vector__XXX
 SG_ x1F4_byte5_lower6 : 40|6@1+ (1,0) [0|63] "" Vector__XXX

CM_ SG_ 680 TX_WARN2 "Transmission warning #2";
CM_ SG_ 680 TCM_Vehicle_Hold_Rq "Transmission request to hold the vehicle/apply the park brake";
CM_ SG_ 680 TargetGear "Target Gear - protected";
CM_ SG_ 680 MC_TCM_A7 "Message counter";
CM_ SG_ 680 HCPShutDwnCmd "HCP System Shutdown Command";
CM_ SG_ 680 HCP_IMMO_STAT_CANC "Communicates immobilizer handshake status to BCM";
CM_ SG_ 680 CurrentGear "Current Gear";
CM_ SG_ 680 CRC_TCM_A7 "CRC-checksum byte 1 to 7 according to SAE J1850";
CM_ SG_ 678 TrqIntensitySts "LDW torque intesity level for display in cluster";
CM_ SG_ 678 SensitivitySts "LDW sensitivity level for display in cluster";
CM_ SG_ 678 ISO_TelltaleSts "LDW telltale status in cluster";
CM_ SG_ 678 HALF_RF_CHIME_RQSts "LDW chime request for right side; true = [1]";
CM_ SG_ 678 HALF_LF_CHIME_RQSts "LDW chime request for left side; true = [1]";
CM_ SG_ 678 HALF_CHIME_TYPESts "LDW chime type";
CM_ SG_ 678 HALF_CHIME_REP_RATESts "LDW chime repetition rate; Continuous = [0]";
CM_ SG_ 678 DispPopupSts "LDW message status in cluster";
CM_ SG_ 678 DisplaySts "LDW display status in cluster";
CM_ BO_ 676 "Tx Rate: 100ms, Std Dev: 5.4ms";
CM_ SG_ 676 x2A4_byte1 "kinda looks like manifold pressure. Maybe pressure from some other sensor?";
CM_ SG_ 672 OIL_TEMP_IND_RQ "Engine oil overtemp. indicator request";
CM_ SG_ 672 OIL_TEMP_CHM_RQ "Engine oil overtemp. chime request";
CM_ SG_ 672 OIL_PRESS "Oil pressure";
CM_ SG_ 672 OIL_IND_LMP_FLSH "Oil indicator lamp flash (for in plant use)";
CM_ SG_ 672 MIL_OnRq "MIL on request from the engine";
CM_ SG_ 672 MIL_IND_BLINK "Request MIL blink (OBD II)";
CM_ SG_ 672 FuelCons "Fuel consumption";
CM_ SG_ 672 ETC_IND_LMP "ETC faulty, indicator lamp request";
CM_ SG_ 672 EngRun_Stat "Engine running state";
CM_ SG_ 672 EngOilTemp "Oil temperature";
CM_ SG_ 672 EngOilIndLmp_On_Rq "Request oil level/oil pressure indicator lamp";
CM_ SG_ 672 DefFuelEcon "Default fuel economy";
CM_ SG_ 671 TorqueOverlaySteeringReq "Torque requested by the PTS torque overlay";
CM_ SG_ 671 TorqueOverlayIntActivation "Torques overlay interface activiation request; Active = [1]";
CM_ SG_ 671 PTSSystemFault "PTS system fault; True = [1]";
CM_ SG_ 671 PTSDriveStyleReqSts "PTS drive style request status; Active = [1]";
CM_ SG_ 671 PTS_ManoeuvreMode "Parking maneuver mode status of the PTS";
CM_ SG_ 671 MC_29Fh "Message counter";
CM_ SG_ 671 ManeuverPhase "Movement direction estimated by PTS; Forward = [1]";
CM_ SG_ 671 CRC_29Fh "CRC-checksum byte 1 to 7 according to SAE J1850";
CM_ SG_ 671 x29F_byte0_upper1 "added by New Eagle to ensure checksums arent messed up if FCA adds a new signal";
CM_ SG_ 671 x29F_byte2_lower5 "added by New Eagle to ensure checksums arent messed up if FCA adds a new signal";
CM_ SG_ 671 x29F_byte3 "added by New Eagle to ensure checksums arent messed up if FCA adds a new signal";
CM_ SG_ 671 x29F_byte4 "added by New Eagle to ensure checksums arent messed up if FCA adds a new signal";
CM_ SG_ 671 x29F_byte5 "added by New Eagle to ensure checksums arent messed up if FCA adds a new signal";
CM_ SG_ 671 x29F_byte6_lower4 "added by New Eagle to ensure checksums arent messed up if FCA adds a new signal";
CM_ SG_ 660 TOC_Sts "Torque overlay controller status";
CM_ SG_ 660 TOC_Fault "Torque overlay controller fault";
CM_ SG_ 660 TOC_Act_Req "Torque overlay controller active request";
CM_ SG_ 660 TO_Req "Torque requested by the DST torque overlay controller";
CM_ SG_ 660 SyncPos "Signal P2 sync position";
CM_ SG_ 660 MC_294h "Message counter";
CM_ SG_ 660 CRC_294h "CRC-checksum byte 1 to 7 according to SAE J1850";
CM_ SG_ 660 BrkPrss_Two "Brake Pressure Two (P2 if supported)";
CM_ SG_ 660 BrkPrss_One "Brake Pressure One (P1)";
CM_ SG_ 658 MTO_HALFSystemSts "HaLF system status; Faulted = [1]";
CM_ SG_ 658 MTO_HALFDriveStyleSts "HaLF drive style status acknowledgement";
CM_ SG_ 658 MotorTorqueOverlaySteeringReq "HaLF torque overlay steering request";
CM_ SG_ 658 MotorTorqueOverlayIntActivation "Torques overlay interface activation; Active = [1]";
CM_ SG_ 658 MC_292h "Message counter";
CM_ SG_ 658 CRC_292h "CRC-checksum byte 1 to 5 according to SAE J1850";
CM_ SG_ 658 x292_byte2 "added by New Eagle to ensure checksums arent messed up if FCA adds a new signal";
CM_ SG_ 658 x292_byte3 "added by New Eagle to ensure checksums arent messed up if FCA adds a new signal";
CM_ SG_ 658 x292_byte4_lower4 "added by New Eagle to ensure checksums arent messed up if FCA adds a new signal";
CM_ SG_ 656 UConnSeed4 "Character 4";
CM_ SG_ 656 UConnSeed3 "Character 3";
CM_ SG_ 656 UConnSeed2 "Character 2";
CM_ SG_ 656 UConnSeed1 "Character 1";
CM_ BO_ 653 "not on WK but we're adding it!";
CM_ SG_ 653 MIL_OnRq_EBCM "MIL on request from the EBCM";
CM_ SG_ 653 EBCMSysEmsMlfAtv "EBCM emissions related malfunction active";
CM_ SG_ 653 BrakePedalTravelSensorV "Brake pedal travel sensor valid (1 = valid data)";
CM_ SG_ 653 BrakePedalTravelSensor "Brake pedal travel sensor 0-100% (0 = upstop)";
CM_ SG_ 653 BrakePedalAppliedV "Validity bit";
CM_ SG_ 653 BrakePedalApplied "driver operates the brake pedal";
CM_ SG_ 639 IBS_Tm_Lst_Reset_Sec "Accumulated time since last reset in seconds";
CM_ SG_ 639 IBS_Tm_Lst_Reset_Days "Accumulated time since last reset in days";
CM_ SG_ 639 IBS_Q_released "Lifetime charge released";
CM_ SG_ 639 IBS_Q_received "LifeTime charge received";
CM_ SG_ 632 SpStWarnStat "Stop start warning status";
CM_ SG_ 632 SpStSwStat "Stop start switch status";
CM_ SG_ 632 SpStDispstat "Stop start display status";
CM_ SG_ 632 ESS_ActvEBrake "ESS active E-brake. 1 = Active, 0 = Inactive";
CM_ SG_ 632 CC_SetSpdDsplMPH "Cruise control set speed for display in miles per hour";
CM_ SG_ 632 CC_SetSpdDspl "Cruise control set speed for display (kmph only)";
CM_ SG_ 632 x278_BrkVacuumPmpOn_NoFault "True when the engine is commanding the brake vacuum pump on during normal operations. If it's running in a fault-action state, a different bit will set.

It appears the pump kicks on at -58kPa of vacuum and turns off when it gets down to -67kPa of vacuum.";
CM_ SG_ 632 x278_BrkVacuumPmpFaulted "True when there is a brake-vacuum-related fault in the ECM. It cycles the pump on and off but this flag stays true until the next key cycle";
CM_ SG_ 625 WhlTrqRq_DAS "Requested wheel torque";
CM_ SG_ 625 WhlTrqActRq_DAS "Wheel torque request active; True = [1]";
CM_ SG_ 625 MC_DAS_A5 "Message counter";
CM_ SG_ 625 FCWState "FCW system operating state; On = [1]";
CM_ SG_ 625 FCWSettingTeen "Forward collision warning sensitivity setting teen key";
CM_ SG_ 625 FCWSetting "Forward collision warning sensitivity setting";
CM_ SG_ 625 FCWBrkTeen "FCW braking is on for teen key; true = [1]";
CM_ SG_ 625 CRC_DAS_A5 "CRC-checksum byte 1 to 7 according to SAE J1850";
CM_ SG_ 625 x271_byte0_lower2 "added by New Eagle to ensure checksums arent messed up if FCA adds a new signal";
CM_ SG_ 625 x271_byte1 "added by New Eagle to ensure checksums arent messed up if FCA adds a new signal";
CM_ SG_ 625 x271_byte2 "added by New Eagle to ensure checksums arent messed up if FCA adds a new signal";
CM_ SG_ 625 x271_byte3_CruiseStoredSpdSetpt "added by New Eagle to ensure checksums arent messed up if FCA adds a new signal. appears to follow cruise (or ACC) speed setpoint. Stays set when cruise is in cancel mode, then clears to zero when cruise is turned off";
CM_ SG_ 625 x271_byte6_lower4 "added by New Eagle to ensure checksums arent messed up if FCA adds a new signal";
CM_ SG_ 624 R_R_Req_PE "Right rear passive entry requested; True = [1]";
CM_ SG_ 624 PNC_ALM_ACT "Panic alarm active; [1] = True";
CM_ SG_ 624 L_R_Req_PE "Left rear passive entry requested; True = [1]";
CM_ SG_ 624 Gate_Req_PE "Gate passive entry requested; True = [1]";
CM_ SG_ 624 EngineOffTimer "Engine off timer - engine off ignition NOT lock.";
CM_ BO_ 618 "Tx Rate: 100ms, Std Dev: 5.4ms";
CM_ SG_ 608 RR_PTS_StopControlStsTeen "PTS rear park stop control status for teen key; Enabled = [1]";
CM_ SG_ 608 RR_PTS_StopControlSts "PTS rear park stop control status; Enabled = [1]";
CM_ SG_ 608 RR_PTS_Dist "Rear distance to nearest obstacle";
CM_ SG_ 608 RR_PTS_Brk_RqSts "PTS rear brake request flag; True = [1]";
CM_ SG_ 608 PTS_RR_VOL_TeenKey "PTS Rear Volume Setting for teen key";
CM_ SG_ 608 PTS_RR_TEMP_NA "ParkSense rear system temporarily not available; True = [1]";
CM_ SG_ 608 PTS_PopUpRqst "ParkSense HMI pop-up message request";
CM_ SG_ 608 PTS_Off_Status "ParkSense system on/off status indication";
CM_ SG_ 608 PTS_FT_VOL_TeenKey "PTS Front Volume Setting for teen key";
CM_ SG_ 608 PTS_FT_TEMP_NA "ParkSense front system temporarily not available; True = [1]";
CM_ SG_ 608 PTS_CFG_STAT_TeenKey "Park assist configuration status for teen key";
CM_ SG_ 608 MC_PTS_2 "Message counter";
CM_ SG_ 608 CRC_PTS_2 "CRC-checksum byte 1 to 7 according to SAE J1850";
CM_ SG_ 584 PN14_LS_Actv "14 V powernet Load Shed active";
CM_ SG_ 584 IBS_SOH_Q_Accuracy "SOH_Q accuracy status";
CM_ SG_ 584 IBS_SOH_Q "State of health";
CM_ SG_ 584 IBS_SOF_t_Accuracy "SOF_t accuracy status";
CM_ SG_ 584 IBS_SOF_t "Predicted time limit for start capability";
CM_ SG_ 584 IBS_SOF_Q_Accuracy "SOF_Q accuracy status";
CM_ SG_ 584 IBS_SOF_Q "Residual battery charge in Ah";
CM_ SG_ 584 IBS_SOC_Accuracy "SOC accuracy status";
CM_ SG_ 584 IBS_SOC "State of charge";
CM_ SG_ 584 Batt_ST_Crit "Battery reached critical state";
CM_ BO_ 579 "Tx Rate: 971ms, Std Dev: 171.5ms";
CM_ SG_ 571 ResumeSwitch "Cruise Switch: Resume Pressed";
CM_ SG_ 571 MC_CSWC_1 "Message counter";
CM_ SG_ 571 DeceleratorSts "Cruise Switch: Coast or Set/Decel Pressed";
CM_ SG_ 571 CrusCnclSwitch "Cruise Switch: Cancel Pressed";
CM_ SG_ 571 CruiseControlOnOffSts "Cruise Switch: On/Off  Pressed";
CM_ SG_ 571 CruiseControlFailSts "Cruise Switch: Implausible State=1";
CM_ SG_ 571 CRC_CSWC_1 "CRC-checksum byte 1 to 2 according to SAE J1850";
CM_ SG_ 571 AcceleratorSts "Cruise Switch: Set/Accel Pressed";
CM_ SG_ 571 ACC_On "Cruise Switch: ACC or ESC mode pressed";
CM_ SG_ 571 ACC_DistSwInc "Cruise Switch: Distance Increase pressed";
CM_ SG_ 571 ACC_DistSwDec "Cruise Switch: Distance Decrease pressed";
CM_ SG_ 571 x23B_byte1_middle3 "added by New Eagle to ensure checksums arent messed up if FCA adds a new signal";
CM_ BO_ 564 "not sure if this is HVAC_A2. Had to manually change DLC to 8 but Pacifica was 8 too.";
CM_ SG_ 564 IBS_SOF_V1 "Predicted initial battery voltage dip during cranking";
CM_ SG_ 564 IBS_SOF_V_Accuracy "SOF_V accuracy status";
CM_ SG_ 564 IBS_SOF_V "Predicted battery voltage during cranking V2";
CM_ SG_ 564 IBS_Error_NVM "Error in IBS NVM data; Error = [1]";
CM_ SG_ 564 IBS_Error_Ident "Error in ECU identification; Error = [1]";
CM_ SG_ 564 IBS_Error_Calib "Error in IBS calibration data; Error = [1]";
CM_ SG_ 564 AM_ECM_Trace "Aftermarket ECM trace";
CM_ BO_ 560 "not sure if this is HVAC_A2. Had to manually change DLC to 8 becuase WK doesn't match the pacifica";
CM_ SG_ 560 EvapTempTar "Evaporator temperature target";
CM_ SG_ 560 EVAP_TEMP "AC evaporator temperature";
CM_ SG_ 560 DEFROST_SEL "Defrost select switch";
CM_ SG_ 560 AC_SEL "Customer has selected A/C; [1] = A/C selected; 0 = A/C not selected";
CM_ SG_ 560 AC_RQ "A/C clutch request; [1] = A/C Clutch requested; 0 = A/C Clutch not requested";
CM_ SG_ 560 AC_PT_Demand "Maximum A/C demand to powertrain";
CM_ SG_ 559 MC_ECM_A5 "Message counter";
CM_ SG_ 559 CRC_ECM_A5 "CRC-checksum byte 1 to 7 according to SAE J1850";
CM_ SG_ 559 ActlAccelPdlPosn "Throttle Pedal Position (actual)";
CM_ SG_ 557 Command_15 "Steering wheel switch 15";
CM_ SG_ 557 Command_14 "Steering wheel switch 14";
CM_ SG_ 557 Command_13 "Steering wheel switch 13";
CM_ SG_ 557 Command_12 "Steering wheel switch 12";
CM_ SG_ 557 Command_11 "Steering wheel switch 11";
CM_ SG_ 544 TOI_Act_Sts "Torque overlay interface status";
CM_ SG_ 544 StrClmTrqVD "Steering column torque: valid data [1]";
CM_ SG_ 544 StrClmTrq "Steering column torque; counterclockwise positive [Nm]";
CM_ SG_ 544 PTSTorqueOverlayIntActivated "Torque overlay interface has been successfully activated; True = [1]";
CM_ SG_ 544 PTSTorqueOverlayFault "Fault of the PTS torque overlay interface; True = [1]";
CM_ SG_ 544 PTSDriveStyleSts "PTS_TOC Actived = [1]";
CM_ SG_ 544 MC_EPS_1 "Message counter";
CM_ SG_ 544 HALFTorqueOverlayIntActivated "Torque overlay interface has been successfully activated; True = [1]";
CM_ SG_ 544 HALFTorqueOverlayFault "Fault of the HALF torque overlay interface";
CM_ SG_ 544 EPSTemporaryDeactivationPPPA "Temporary deactivation of the EPS PPPA torque overlay function; True = [1]";
CM_ SG_ 544 EPSTemporaryDeactivationLDW "Temporary deactivation of the EPS LDW torque overlay function";
CM_ SG_ 544 EPSMotorTorqueValidData "Motor torque: valid data [1]";
CM_ SG_ 544 EPSMotorTorque "EPS motor torque";
CM_ SG_ 544 EPSHandsOnRecognition "Driver interference during the semiautomatic parking maneuver; True = [1]";
CM_ SG_ 544 DSTTorqueOverlayIntActivated "DST torque overlay interface activated; True = [1]";
CM_ SG_ 544 DSTTorqueOverlayFault "Torque overlay fault; True = 1";
CM_ SG_ 544 CRC_EPS_1 "CRC-checksum byte 1 to 7 according to SAE J1850";
CM_ SG_ 544 AssistanceTorque "Torque provided by EPS system to the shaft for the driver";
CM_ SG_ 544 x220_byte4_middle2 "added by New Eagle to ensure checksums arent messed up if FCA adds a new signal";
CM_ SG_ 532 IBS_Voltage_Status "IBS Voltage Status";
CM_ SG_ 532 IBS_V_BATT "Batt. voltage measured at the terminals";
CM_ SG_ 532 IBS_Temp_Status "IBS Temperature Status";
CM_ SG_ 532 IBS_T_BATT "Battery temperature";
CM_ SG_ 532 IBS_PreWakeupVoltage "IBS voltage before LIN wakeup";
CM_ SG_ 532 IBS_I_RANGE "Current range sensor setting";
CM_ SG_ 532 IBS_I_BATT "Battery current (Using I_Range resolution)";
CM_ SG_ 532 IBS_Current_Status "IBS Current Status";
CM_ SG_ 520 RefuelRequest "Driver has initiated a refueling event";
CM_ SG_ 520 PsngrDoorAjarXtionSts "Front passenger door ajar transition status";
CM_ SG_ 520 PsngrDoorAjarRawValSts "Passengers door ajar status";
CM_ SG_ 520 LeakCheckTimerExpired "Status of leak test timer";
CM_ SG_ 520 FuelDrRelSwRawSt "Raw voltage of fuel door release switch in the cabin";
CM_ SG_ 520 DriverDoorAjarXtionSts "Drivers door ajar transition status";
CM_ SG_ 520 DriverDoorAjarRawValSts "Drivers door ajar status";
CM_ SG_ 520 DriverDoor2AjarXtionSts "Drivers door switch - 2 ajar transition status";
CM_ SG_ 520 DriverDoor2AjarRawValSts "Drivers door switch - 2 ajar status";
CM_ SG_ 520 BrkPdlStat_CBC "Brake pedal state reported by CBC";
CM_ SG_ 520 BonnetAjarRawValSts "Hood ajar status";
CM_ SG_ 514 WheelRPM_FR "Wheel RPM front right";
CM_ SG_ 514 WheelRPM_FL "Wheel RPM front left";
CM_ SG_ 514 x202_byte4_upper4 "need to confirm max value of pedal sensor in bits below this - is this signal more or less than 4 bits";
CM_ SG_ 514 x202_OemBrakePdlPosnSensor "need to unplug sensor to confirm max (SNA) value and number of bits";
CM_ SG_ 512 FUEL_VOLT2 "Sub Side Fuel level sensor A/D Voltage (saddle/Dual tank)";
CM_ SG_ 512 FUEL_VOLT "Fuel level A/D Voltage (Single tank OR Primary on Saddle/Dual Tank)";
CM_ SG_ 512 BATT_VOLT "System voltage";
CM_ SG_ 512 AMB_TEMP_VOLT "Ambient Temp Sensor A/D Voltage";
CM_ SG_ 512 AMB_TEMP_AVG "Averaged ambient temperature";
CM_ SG_ 512 AirTemp_Outsd "Outside air temperature";
CM_ SG_ 501 Sm_ICON_Dspl "Small graphic display";
CM_ SG_ 501 SetSpeed_MPH "Desired set speed in miles per hour";
CM_ SG_ 501 SetSpeed_KPH "Desired set speed in kilometers per hour";
CM_ SG_ 501 RadarBlocked "ACC FCW not available: clean radar snsr; True = [1]";
CM_ SG_ 501 ObjIntrstDist "Object of interest distance";
CM_ SG_ 501 NCConlyNA_DASMSts "NCC only not available: vehicle system error; True = [1]";
CM_ SG_ 501 NCCNA_DASMSts "NCC/FCW not avail: vehicle system error; True = [1]";
CM_ SG_ 501 HMI_Screens "HMI screens";
CM_ SG_ 501 FCWonlyNA_DASMSts "FCW only not available: vehicle system error; True = [1]";
CM_ SG_ 501 FCWBrakingOff "FCW autobraking disabled; True = [1]";
CM_ SG_ 501 FCW_Error "Forward collision warning error";
CM_ SG_ 501 FCW_BrkOn "FCW braking is on; true = [1]";
CM_ SG_ 501 CIPV_Fused "Closest in-path vehicle is fused; True = [1]";
CM_ SG_ 501 CameraFailure "ACC/FCW limited functionality: camera failure; True = [1]";
CM_ SG_ 501 CameraBlocked "ACC FCW limited functionality: camera blocked; True = [1]";
CM_ SG_ 501 ACCOnOff "ACC on off status";
CM_ SG_ 501 ACConlyNA_DASMSts "ACC only not available: vehicle system error; True = [1]";
CM_ SG_ 501 ACCNA_DASMSts "ACC/FCW not avail: vehicle system error; True = [1]";
CM_ SG_ 501 ACCFaulted "ACC faulted; True = [1]";
CM_ SG_ 501 ACC_HMI_SCRN_REQ "ACC HMI Screen request. Display HMI screen when [1]";
CM_ SG_ 500 MC_DAS_A3 "Message counter";
CM_ SG_ 500 DsblFuelShutOff_ACC "Disable fuel shutoff; True = [1]";
CM_ SG_ 500 DAS_Sts "DASM fault status";
CM_ SG_ 500 DAS_Rq_ID "DAS request ID";
CM_ SG_ 500 DAS_ACCEL_Rq "DASM acceleration request";
CM_ SG_ 500 CRC_DAS_A3 "CRC-checksum byte 1 to 7 according to SAE J1850";
CM_ SG_ 500 Brk_PreFill_Rq "Brakes pre-fill request; True = [1]";
CM_ SG_ 500 Brk_Jrk_Rq "Brake jerk request; True = [1]";
CM_ SG_ 500 As_DispRq "Assistance system display request (priority)";
CM_ SG_ 500 ACCFCW_ChimeRq "ACC FCW chime request active; Active = [1]";
CM_ SG_ 500 ACC_Still_Cmd "ACC stop commanded; True = [1]";
CM_ SG_ 500 ACC_Engd "ACC engaged; True = [1]";
CM_ SG_ 500 ACC_Enbl "ACC cruise control enabled; True = [1]";
CM_ SG_ 500 ACC_Drive_Cmd "ACC drive off commanded; True = [1]";
CM_ SG_ 500 DAS_A3_unknownBigEndian "These bits are all 1's in the CAN messge that the vehicle sends. We don't know what they do, but we need to read and account for them in the checksum calculation of this message.";
CM_ SG_ 500 x1F4_byte0_upper1 "added by New Eagle to ensure checksums arent messed up if FCA adds a new signal";
CM_ SG_ 500 x1F4_byte2_middle1 "added by New Eagle to ensure checksums arent messed up if FCA adds a new signal";
CM_ SG_ 500 x1F4_byte4_lower4 "added by New Eagle to ensure checksums arent messed up if FCA adds a new signal";
CM_ SG_ 500 x1F4_byte5_lower6 "added by New Eagle to ensure checksums arent messed up if FCA adds a new signal";
BA_DEF_ SG_  "GenSigTimeout_CBC" INT 0 65535;
BA_DEF_ SG_  "GenSigTimeout_EPS" INT 0 65535;
BA_DEF_ SG_  "GenSigTimeout_ESM" INT 0 65535;
BA_DEF_ SG_  "GenSigTimeout_ETM" INT 0 65535;
BA_DEF_ SG_  "GenSigTimeout_HaLF" INT 0 65535;
BA_DEF_ SG_  "GenSigTimeout_IC" INT 0 65535;
BA_DEF_ SG_  "GenSigTimeout_OCM" INT 0 65535;
BA_DEF_ SG_  "GenSigTimeout_ORC" INT 0 65535;
BA_DEF_ SG_  "GenSigTimeout_PTS" INT 0 65535;
BA_DEF_ SG_  "GenSigTimeout_RF_HUB" INT 0 65535;
BA_DEF_ SG_  "GenSigTimeout_SCCM" INT 0 65535;
BA_DEF_ BO_  "GenMsgStartValue" STRING ;
BA_DEF_ SG_  "GenSigSNA" STRING ;
BA_DEF_ SG_  "RID" STRING ;
BA_DEF_ SG_  "FlexKomIsMotorola" ENUM  "nein","ja";
BA_DEF_ SG_  "FlexKomSigLaenge" INT 0 64;
BA_DEF_ SG_  "FlexKomSigStartPos" INT 0 63;
BA_DEF_ SG_  "FlexKomComment" STRING ;
BA_DEF_ SG_  "FlexKomSigName" STRING ;
BA_DEF_ SG_  "FlexKomSID" INT 0 2147483647;
BA_DEF_ SG_  "GenSigStartValue" HEX 0 -1;
BA_DEF_ SG_  "FlexKomSigStartValue" STRING ;
BA_DEF_ SG_  "GenSigCycleTime" INT 0 65535;
BA_DEF_ SG_  "GenSigSendType" ENUM  "cyclicX","spontanX","cyclicIfActiveX","spontanWithDelay","cyclicAndSpontanX","cyclicAndSpontanWithDelay","spontanWithRepitition","cyclicIfActiveAndSpontanWD","cyclicIfActiveFast","cyclicWithRepeatOnDemand","none";
BA_DEF_ BO_  "GenMsgNrOfRepetitions" INT 0 65535;
BA_DEF_ BO_  "GenMsgDelayTime" INT 0 65535;
BA_DEF_ BO_  "GenMsgStartDelayTime" INT 0 65535;
BA_DEF_ BO_  "GenMsgCycleTime" INT 0 65535;
BA_DEF_ BO_  "GenMsgSendType" ENUM  "cyclicX","spontanX","cyclicIfActiveX","spontanWithDelay","cyclicAndSpontanX","cyclicAndSpontanWithDelay","spontanWithRepitition","cyclicIfActiveAndSpontanWD","cyclicIfActiveFast","cyclicWithRepeatOnDemand","none";
BA_DEF_ BO_  "DiagResponse" ENUM  "nein","ja";
BA_DEF_ BO_  "DiagRequest" ENUM  "nein","ja";
BA_DEF_ BO_  "DiagState" ENUM  "nein","ja";
BA_DEF_ BO_  "App-Botschaft" ENUM  "nein","ja";
BA_DEF_ BO_  "NWM-Botschaft" ENUM  "nein","ja";
BA_DEF_DEF_  "GenSigTimeout_CBC" 0;
BA_DEF_DEF_  "GenSigTimeout_EPS" 0;
BA_DEF_DEF_  "GenSigTimeout_ESM" 0;
BA_DEF_DEF_  "GenSigTimeout_ETM" 0;
BA_DEF_DEF_  "GenSigTimeout_HaLF" 0;
BA_DEF_DEF_  "GenSigTimeout_IC" 0;
BA_DEF_DEF_  "GenSigTimeout_OCM" 0;
BA_DEF_DEF_  "GenSigTimeout_ORC" 0;
BA_DEF_DEF_  "GenSigTimeout_PTS" 0;
BA_DEF_DEF_  "GenSigTimeout_RF_HUB" 0;
BA_DEF_DEF_  "GenSigTimeout_SCCM" 0;
BA_DEF_DEF_  "GenMsgStartValue" "";
BA_DEF_DEF_  "GenSigSNA" "";
BA_DEF_DEF_  "RID" "";
BA_DEF_DEF_  "FlexKomIsMotorola" "nein";
BA_DEF_DEF_  "FlexKomSigLaenge" 0;
BA_DEF_DEF_  "FlexKomSigStartPos" 0;
BA_DEF_DEF_  "FlexKomComment" "";
BA_DEF_DEF_  "FlexKomSigName" "";
BA_DEF_DEF_  "FlexKomSID" 0;
BA_DEF_DEF_  "GenSigStartValue" 0;
BA_DEF_DEF_  "FlexKomSigStartValue" "";
BA_DEF_DEF_  "GenSigCycleTime" 0;
BA_DEF_DEF_  "GenSigSendType" "cyclicX";
BA_DEF_DEF_  "GenMsgNrOfRepetitions" 0;
BA_DEF_DEF_  "GenMsgDelayTime" 0;
BA_DEF_DEF_  "GenMsgStartDelayTime" 0;
BA_DEF_DEF_  "GenMsgCycleTime" 0;
BA_DEF_DEF_  "GenMsgSendType" "cyclicX";
BA_DEF_DEF_  "DiagResponse" "nein";
BA_DEF_DEF_  "DiagRequest" "nein";
BA_DEF_DEF_  "DiagState" "nein";
BA_DEF_DEF_  "App-Botschaft" "nein";
BA_DEF_DEF_  "NWM-Botschaft" "nein";
BA_ "GenMsgStartValue" BO_ 680 "0FFF0F0F000000FFh";
BA_ "GenMsgNrOfRepetitions" BO_ 680 2;
BA_ "GenMsgDelayTime" BO_ 680 20;
BA_ "GenMsgCycleTime" BO_ 680 20;
BA_ "GenSigSNA" SG_ 680 TX_WARN2 "FFh";
BA_ "FlexKomIsMotorola" SG_ 680 TX_WARN2 1;
BA_ "FlexKomComment" SG_ 680 TX_WARN2 "Transmission message A7 packet";
BA_ "FlexKomSigName" SG_ 680 TX_WARN2 "TCM_A7_PKT";
BA_ "FlexKomSigLaenge" SG_ 680 TX_WARN2 64;
BA_ "FlexKomSigStartPos" SG_ 680 TX_WARN2 7;
BA_ "FlexKomSID" SG_ 680 TX_WARN2 1613;
BA_ "GenSigTimeout_IC" SG_ 680 TX_WARN2 210;
BA_ "GenSigTimeout_CBC" SG_ 680 TX_WARN2 210;
BA_ "FlexKomSigStartValue" SG_ 680 TX_WARN2 "0FFF0F0F000000FFh";
BA_ "GenSigCycleTime" SG_ 680 TX_WARN2 20;
BA_ "GenSigSNA" SG_ 680 TCM_Vehicle_Hold_Rq "3h";
BA_ "FlexKomIsMotorola" SG_ 680 TCM_Vehicle_Hold_Rq 1;
BA_ "FlexKomComment" SG_ 680 TCM_Vehicle_Hold_Rq "Transmission message A7 packet";
BA_ "FlexKomSigName" SG_ 680 TCM_Vehicle_Hold_Rq "TCM_A7_PKT";
BA_ "FlexKomSigLaenge" SG_ 680 TCM_Vehicle_Hold_Rq 64;
BA_ "FlexKomSigStartPos" SG_ 680 TCM_Vehicle_Hold_Rq 7;
BA_ "FlexKomSID" SG_ 680 TCM_Vehicle_Hold_Rq 1613;
BA_ "FlexKomSigStartValue" SG_ 680 TCM_Vehicle_Hold_Rq "0FFF0F0F000000FFh";
BA_ "GenSigCycleTime" SG_ 680 TCM_Vehicle_Hold_Rq 20;
BA_ "GenSigSNA" SG_ 680 TargetGear "Fh";
BA_ "FlexKomIsMotorola" SG_ 680 TargetGear 1;
BA_ "FlexKomComment" SG_ 680 TargetGear "Transmission message A7 packet";
BA_ "FlexKomSigName" SG_ 680 TargetGear "TCM_A7_PKT";
BA_ "FlexKomSigLaenge" SG_ 680 TargetGear 64;
BA_ "FlexKomSigStartPos" SG_ 680 TargetGear 7;
BA_ "FlexKomSID" SG_ 680 TargetGear 1613;
BA_ "GenSigStartValue" SG_ 680 TargetGear 15;
BA_ "FlexKomSigStartValue" SG_ 680 TargetGear "0FFF0F0F000000FFh";
BA_ "GenSigCycleTime" SG_ 680 TargetGear 20;
BA_ "GenSigSNA" SG_ 680 MC_TCM_A7 "0h";
BA_ "FlexKomIsMotorola" SG_ 680 MC_TCM_A7 1;
BA_ "FlexKomComment" SG_ 680 MC_TCM_A7 "Transmission message A7 packet";
BA_ "FlexKomSigName" SG_ 680 MC_TCM_A7 "TCM_A7_PKT";
BA_ "FlexKomSigLaenge" SG_ 680 MC_TCM_A7 64;
BA_ "FlexKomSigStartPos" SG_ 680 MC_TCM_A7 7;
BA_ "FlexKomSID" SG_ 680 MC_TCM_A7 1613;
BA_ "FlexKomSigStartValue" SG_ 680 MC_TCM_A7 "0FFF0F0F000000FFh";
BA_ "GenSigCycleTime" SG_ 680 MC_TCM_A7 20;
BA_ "GenSigCycleTime" SG_ 680 HCPShutDwnCmd 20;
BA_ "FlexKomSigStartValue" SG_ 680 HCPShutDwnCmd "0FFF0F0F000000FFh";
BA_ "GenSigTimeout_CBC" SG_ 680 HCPShutDwnCmd 210;
BA_ "FlexKomSID" SG_ 680 HCPShutDwnCmd 1613;
BA_ "FlexKomSigStartPos" SG_ 680 HCPShutDwnCmd 7;
BA_ "FlexKomSigLaenge" SG_ 680 HCPShutDwnCmd 64;
BA_ "FlexKomSigName" SG_ 680 HCPShutDwnCmd "TCM_A7_PKT";
BA_ "FlexKomComment" SG_ 680 HCPShutDwnCmd "Transmission message A7 packet";
BA_ "FlexKomIsMotorola" SG_ 680 HCPShutDwnCmd 1;
BA_ "GenSigSNA" SG_ 680 HCPShutDwnCmd "7h";
BA_ "GenSigSNA" SG_ 680 HCP_IMMO_STAT_CANC "3h";
BA_ "FlexKomIsMotorola" SG_ 680 HCP_IMMO_STAT_CANC 1;
BA_ "FlexKomComment" SG_ 680 HCP_IMMO_STAT_CANC "Transmission message A7 packet";
BA_ "FlexKomSigName" SG_ 680 HCP_IMMO_STAT_CANC "TCM_A7_PKT";
BA_ "FlexKomSigLaenge" SG_ 680 HCP_IMMO_STAT_CANC 64;
BA_ "FlexKomSigStartPos" SG_ 680 HCP_IMMO_STAT_CANC 7;
BA_ "FlexKomSID" SG_ 680 HCP_IMMO_STAT_CANC 1613;
BA_ "GenSigTimeout_CBC" SG_ 680 HCP_IMMO_STAT_CANC 210;
BA_ "FlexKomSigStartValue" SG_ 680 HCP_IMMO_STAT_CANC "0FFF0F0F000000FFh";
BA_ "GenSigCycleTime" SG_ 680 HCP_IMMO_STAT_CANC 20;
BA_ "GenSigSNA" SG_ 680 CurrentGear "Fh";
BA_ "FlexKomIsMotorola" SG_ 680 CurrentGear 1;
BA_ "FlexKomComment" SG_ 680 CurrentGear "Transmission message A7 packet";
BA_ "FlexKomSigName" SG_ 680 CurrentGear "TCM_A7_PKT";
BA_ "FlexKomSigLaenge" SG_ 680 CurrentGear 64;
BA_ "FlexKomSigStartPos" SG_ 680 CurrentGear 7;
BA_ "FlexKomSID" SG_ 680 CurrentGear 1613;
BA_ "GenSigStartValue" SG_ 680 CurrentGear 15;
BA_ "FlexKomSigStartValue" SG_ 680 CurrentGear "0FFF0F0F000000FFh";
BA_ "GenSigCycleTime" SG_ 680 CurrentGear 20;
BA_ "GenSigSNA" SG_ 680 CRC_TCM_A7 "FFh";
BA_ "FlexKomIsMotorola" SG_ 680 CRC_TCM_A7 1;
BA_ "FlexKomComment" SG_ 680 CRC_TCM_A7 "Transmission message A7 packet";
BA_ "FlexKomSigName" SG_ 680 CRC_TCM_A7 "TCM_A7_PKT";
BA_ "FlexKomSigLaenge" SG_ 680 CRC_TCM_A7 64;
BA_ "FlexKomSigStartPos" SG_ 680 CRC_TCM_A7 7;
BA_ "FlexKomSID" SG_ 680 CRC_TCM_A7 1613;
BA_ "GenSigStartValue" SG_ 680 CRC_TCM_A7 255;
BA_ "FlexKomSigStartValue" SG_ 680 CRC_TCM_A7 "0FFF0F0F000000FFh";
BA_ "GenSigCycleTime" SG_ 680 CRC_TCM_A7 20;
BA_ "GenMsgStartValue" BO_ 678 "0000000000000000h";
BA_ "GenMsgNrOfRepetitions" BO_ 678 2;
BA_ "GenMsgDelayTime" BO_ 678 20;
BA_ "GenMsgCycleTime" BO_ 678 250;
BA_ "GenMsgSendType" BO_ 678 5;
BA_ "GenSigSNA" SG_ 678 TrqIntensitySts "7h";
BA_ "FlexKomIsMotorola" SG_ 678 TrqIntensitySts 1;
BA_ "FlexKomComment" SG_ 678 TrqIntensitySts "LDW torque intesity level for display in cluster";
BA_ "FlexKomSigName" SG_ 678 TrqIntensitySts "TrqIntensitySts";
BA_ "FlexKomSigLaenge" SG_ 678 TrqIntensitySts 3;
BA_ "FlexKomSigStartPos" SG_ 678 TrqIntensitySts 12;
BA_ "FlexKomSID" SG_ 678 TrqIntensitySts 2016;
BA_ "GenSigTimeout_IC" SG_ 678 TrqIntensitySts 2625;
BA_ "FlexKomSigStartValue" SG_ 678 TrqIntensitySts "00h";
BA_ "GenSigCycleTime" SG_ 678 TrqIntensitySts 250;
BA_ "GenSigSendType" SG_ 678 TrqIntensitySts 5;
BA_ "GenSigSNA" SG_ 678 SensitivitySts "7h";
BA_ "FlexKomIsMotorola" SG_ 678 SensitivitySts 1;
BA_ "FlexKomComment" SG_ 678 SensitivitySts "LDW sensitivity level for display in cluster";
BA_ "FlexKomSigName" SG_ 678 SensitivitySts "SensitivitySts";
BA_ "FlexKomSigLaenge" SG_ 678 SensitivitySts 3;
BA_ "FlexKomSigStartPos" SG_ 678 SensitivitySts 15;
BA_ "FlexKomSID" SG_ 678 SensitivitySts 2017;
BA_ "GenSigTimeout_IC" SG_ 678 SensitivitySts 2625;
BA_ "FlexKomSigStartValue" SG_ 678 SensitivitySts "00h";
BA_ "GenSigCycleTime" SG_ 678 SensitivitySts 250;
BA_ "GenSigSendType" SG_ 678 SensitivitySts 5;
BA_ "GenSigSNA" SG_ 678 ISO_TelltaleSts "7h";
BA_ "FlexKomIsMotorola" SG_ 678 ISO_TelltaleSts 1;
BA_ "FlexKomComment" SG_ 678 ISO_TelltaleSts "LDW telltale status in cluster";
BA_ "FlexKomSigName" SG_ 678 ISO_TelltaleSts "ISO_TelltaleSts";
BA_ "FlexKomSigLaenge" SG_ 678 ISO_TelltaleSts 3;
BA_ "FlexKomSigStartPos" SG_ 678 ISO_TelltaleSts 2;
BA_ "FlexKomSID" SG_ 678 ISO_TelltaleSts 2015;
BA_ "GenSigTimeout_IC" SG_ 678 ISO_TelltaleSts 2625;
BA_ "FlexKomSigStartValue" SG_ 678 ISO_TelltaleSts "00h";
BA_ "GenSigCycleTime" SG_ 678 ISO_TelltaleSts 250;
BA_ "GenSigSendType" SG_ 678 ISO_TelltaleSts 5;
BA_ "GenSigSNA" SG_ 678 HALF_RF_CHIME_RQSts "0h";
BA_ "FlexKomIsMotorola" SG_ 678 HALF_RF_CHIME_RQSts 1;
BA_ "FlexKomComment" SG_ 678 HALF_RF_CHIME_RQSts "LDW chime request for right side; true = [1]";
BA_ "FlexKomSigName" SG_ 678 HALF_RF_CHIME_RQSts "HALF_RF_CHIME_RQSts";
BA_ "FlexKomSigLaenge" SG_ 678 HALF_RF_CHIME_RQSts 1;
BA_ "FlexKomSigStartPos" SG_ 678 HALF_RF_CHIME_RQSts 41;
BA_ "FlexKomSID" SG_ 678 HALF_RF_CHIME_RQSts 2022;
BA_ "FlexKomSigStartValue" SG_ 678 HALF_RF_CHIME_RQSts "00h";
BA_ "GenSigCycleTime" SG_ 678 HALF_RF_CHIME_RQSts 250;
BA_ "GenSigSendType" SG_ 678 HALF_RF_CHIME_RQSts 5;
BA_ "GenSigSNA" SG_ 678 HALF_LF_CHIME_RQSts "0h";
BA_ "FlexKomIsMotorola" SG_ 678 HALF_LF_CHIME_RQSts 1;
BA_ "FlexKomComment" SG_ 678 HALF_LF_CHIME_RQSts "LDW chime request for left side; true = [1]";
BA_ "FlexKomSigName" SG_ 678 HALF_LF_CHIME_RQSts "HALF_LF_CHIME_RQSts";
BA_ "FlexKomSigLaenge" SG_ 678 HALF_LF_CHIME_RQSts 1;
BA_ "FlexKomSigStartPos" SG_ 678 HALF_LF_CHIME_RQSts 40;
BA_ "FlexKomSID" SG_ 678 HALF_LF_CHIME_RQSts 2023;
BA_ "FlexKomSigStartValue" SG_ 678 HALF_LF_CHIME_RQSts "00h";
BA_ "GenSigCycleTime" SG_ 678 HALF_LF_CHIME_RQSts 250;
BA_ "GenSigSendType" SG_ 678 HALF_LF_CHIME_RQSts 5;
BA_ "GenSigSNA" SG_ 678 HALF_CHIME_TYPESts "Fh";
BA_ "FlexKomIsMotorola" SG_ 678 HALF_CHIME_TYPESts 1;
BA_ "FlexKomComment" SG_ 678 HALF_CHIME_TYPESts "LDW chime type";
BA_ "FlexKomSigName" SG_ 678 HALF_CHIME_TYPESts "HALF_CHIME_TYPESts";
BA_ "FlexKomSigLaenge" SG_ 678 HALF_CHIME_TYPESts 4;
BA_ "FlexKomSigStartPos" SG_ 678 HALF_CHIME_TYPESts 35;
BA_ "FlexKomSID" SG_ 678 HALF_CHIME_TYPESts 2020;
BA_ "GenSigTimeout_CBC" SG_ 678 HALF_CHIME_TYPESts 2625;
BA_ "FlexKomSigStartValue" SG_ 678 HALF_CHIME_TYPESts "00h";
BA_ "GenSigCycleTime" SG_ 678 HALF_CHIME_TYPESts 250;
BA_ "GenSigSendType" SG_ 678 HALF_CHIME_TYPESts 5;
BA_ "GenSigSNA" SG_ 678 HALF_CHIME_REP_RATESts "0h";
BA_ "FlexKomIsMotorola" SG_ 678 HALF_CHIME_REP_RATESts 1;
BA_ "FlexKomComment" SG_ 678 HALF_CHIME_REP_RATESts "LDW chime repetition rate; Continuous = [0]";
BA_ "FlexKomSigName" SG_ 678 HALF_CHIME_REP_RATESts "HALF_CHIME_REP_RATESts";
BA_ "FlexKomSigLaenge" SG_ 678 HALF_CHIME_REP_RATESts 4;
BA_ "FlexKomSigStartPos" SG_ 678 HALF_CHIME_REP_RATESts 39;
BA_ "FlexKomSID" SG_ 678 HALF_CHIME_REP_RATESts 2021;
BA_ "GenSigTimeout_CBC" SG_ 678 HALF_CHIME_REP_RATESts 2625;
BA_ "FlexKomSigStartValue" SG_ 678 HALF_CHIME_REP_RATESts "00h";
BA_ "GenSigCycleTime" SG_ 678 HALF_CHIME_REP_RATESts 250;
BA_ "GenSigSendType" SG_ 678 HALF_CHIME_REP_RATESts 5;
BA_ "GenSigSNA" SG_ 678 DispPopupSts "FFh";
BA_ "FlexKomIsMotorola" SG_ 678 DispPopupSts 1;
BA_ "FlexKomComment" SG_ 678 DispPopupSts "LDW message status in cluster";
BA_ "FlexKomSigName" SG_ 678 DispPopupSts "DispPopupSts";
BA_ "FlexKomSigLaenge" SG_ 678 DispPopupSts 8;
BA_ "FlexKomSigStartPos" SG_ 678 DispPopupSts 31;
BA_ "FlexKomSID" SG_ 678 DispPopupSts 2019;
BA_ "GenSigTimeout_IC" SG_ 678 DispPopupSts 2625;
BA_ "FlexKomSigStartValue" SG_ 678 DispPopupSts "00h";
BA_ "GenSigCycleTime" SG_ 678 DispPopupSts 250;
BA_ "GenSigSendType" SG_ 678 DispPopupSts 5;
BA_ "GenSigSNA" SG_ 678 DisplaySts "FFh";
BA_ "FlexKomIsMotorola" SG_ 678 DisplaySts 1;
BA_ "FlexKomComment" SG_ 678 DisplaySts "LDW display status in cluster";
BA_ "FlexKomSigName" SG_ 678 DisplaySts "DisplaySts";
BA_ "FlexKomSigLaenge" SG_ 678 DisplaySts 8;
BA_ "FlexKomSigStartPos" SG_ 678 DisplaySts 23;
BA_ "FlexKomSID" SG_ 678 DisplaySts 2018;
BA_ "GenSigTimeout_IC" SG_ 678 DisplaySts 2625;
BA_ "FlexKomSigStartValue" SG_ 678 DisplaySts "00h";
BA_ "GenSigCycleTime" SG_ 678 DisplaySts 250;
BA_ "GenSigSendType" SG_ 678 DisplaySts 5;
BA_ "GenMsgStartValue" BO_ 672 "6000FFFFFFFFFF07h";
BA_ "GenMsgNrOfRepetitions" BO_ 672 2;
BA_ "GenMsgDelayTime" BO_ 672 20;
BA_ "GenMsgCycleTime" BO_ 672 100;
BA_ "GenSigSNA" SG_ 672 OIL_TEMP_IND_RQ "3h";
BA_ "FlexKomIsMotorola" SG_ 672 OIL_TEMP_IND_RQ 1;
BA_ "FlexKomComment" SG_ 672 OIL_TEMP_IND_RQ "Engine oil overtemp. indicator/chime request";
BA_ "FlexKomSigName" SG_ 672 OIL_TEMP_IND_RQ "OIL_TEMP_RQ";
BA_ "FlexKomSigLaenge" SG_ 672 OIL_TEMP_IND_RQ 4;
BA_ "FlexKomSigStartPos" SG_ 672 OIL_TEMP_IND_RQ 14;
BA_ "FlexKomSID" SG_ 672 OIL_TEMP_IND_RQ 718;
BA_ "GenSigTimeout_ETM" SG_ 672 OIL_TEMP_IND_RQ 1050;
BA_ "GenSigTimeout_IC" SG_ 672 OIL_TEMP_IND_RQ 1050;
BA_ "FlexKomSigStartValue" SG_ 672 OIL_TEMP_IND_RQ "00h";
BA_ "GenSigCycleTime" SG_ 672 OIL_TEMP_IND_RQ 100;
BA_ "GenSigSNA" SG_ 672 OIL_TEMP_CHM_RQ "0h";
BA_ "FlexKomIsMotorola" SG_ 672 OIL_TEMP_CHM_RQ 1;
BA_ "FlexKomComment" SG_ 672 OIL_TEMP_CHM_RQ "Engine oil overtemp. indicator/chime request";
BA_ "FlexKomSigName" SG_ 672 OIL_TEMP_CHM_RQ "OIL_TEMP_RQ";
BA_ "FlexKomSigLaenge" SG_ 672 OIL_TEMP_CHM_RQ 4;
BA_ "FlexKomSigStartPos" SG_ 672 OIL_TEMP_CHM_RQ 14;
BA_ "FlexKomSID" SG_ 672 OIL_TEMP_CHM_RQ 718;
BA_ "GenSigTimeout_IC" SG_ 672 OIL_TEMP_CHM_RQ 1050;
BA_ "FlexKomSigStartValue" SG_ 672 OIL_TEMP_CHM_RQ "00h";
BA_ "GenSigCycleTime" SG_ 672 OIL_TEMP_CHM_RQ 100;
BA_ "GenSigSNA" SG_ 672 OIL_PRESS "FFh";
BA_ "FlexKomIsMotorola" SG_ 672 OIL_PRESS 1;
BA_ "FlexKomComment" SG_ 672 OIL_PRESS "Oil pressure";
BA_ "FlexKomSigName" SG_ 672 OIL_PRESS "OIL_PRESS";
BA_ "FlexKomSigLaenge" SG_ 672 OIL_PRESS 8;
BA_ "FlexKomSigStartPos" SG_ 672 OIL_PRESS 23;
BA_ "FlexKomSID" SG_ 672 OIL_PRESS 717;
BA_ "GenSigTimeout_IC" SG_ 672 OIL_PRESS 1050;
BA_ "GenSigTimeout_CBC" SG_ 672 OIL_PRESS 1050;
BA_ "GenSigStartValue" SG_ 672 OIL_PRESS 255;
BA_ "FlexKomSigStartValue" SG_ 672 OIL_PRESS "FFh";
BA_ "GenSigCycleTime" SG_ 672 OIL_PRESS 100;
BA_ "GenSigSNA" SG_ 672 OIL_IND_LMP_FLSH "0h";
BA_ "FlexKomIsMotorola" SG_ 672 OIL_IND_LMP_FLSH 1;
BA_ "FlexKomComment" SG_ 672 OIL_IND_LMP_FLSH "Oil indicator lamp flash (for in plant use)";
BA_ "FlexKomSigName" SG_ 672 OIL_IND_LMP_FLSH "OIL_IND_LMP_FLSH";
BA_ "FlexKomSigLaenge" SG_ 672 OIL_IND_LMP_FLSH 1;
BA_ "FlexKomSigStartPos" SG_ 672 OIL_IND_LMP_FLSH 8;
BA_ "FlexKomSID" SG_ 672 OIL_IND_LMP_FLSH 716;
BA_ "GenSigTimeout_IC" SG_ 672 OIL_IND_LMP_FLSH 1050;
BA_ "FlexKomSigStartValue" SG_ 672 OIL_IND_LMP_FLSH "00h";
BA_ "GenSigCycleTime" SG_ 672 OIL_IND_LMP_FLSH 100;
BA_ "GenSigSNA" SG_ 672 MIL_OnRq "0h";
BA_ "FlexKomIsMotorola" SG_ 672 MIL_OnRq 1;
BA_ "FlexKomComment" SG_ 672 MIL_OnRq "MIL on request from the engine";
BA_ "FlexKomSigName" SG_ 672 MIL_OnRq "MIL_OnRq";
BA_ "FlexKomSigLaenge" SG_ 672 MIL_OnRq 1;
BA_ "FlexKomSID" SG_ 672 MIL_OnRq 714;
BA_ "GenSigTimeout_ORC" SG_ 672 MIL_OnRq 350;
BA_ "GenSigTimeout_IC" SG_ 672 MIL_OnRq 1050;
BA_ "FlexKomSigStartValue" SG_ 672 MIL_OnRq "00h";
BA_ "GenSigCycleTime" SG_ 672 MIL_OnRq 100;
BA_ "GenSigSNA" SG_ 672 MIL_IND_BLINK "0h";
BA_ "FlexKomIsMotorola" SG_ 672 MIL_IND_BLINK 1;
BA_ "FlexKomComment" SG_ 672 MIL_IND_BLINK "Request MIL blink (OBD II)";
BA_ "FlexKomSigName" SG_ 672 MIL_IND_BLINK "MIL_IND_BLINK";
BA_ "FlexKomSigLaenge" SG_ 672 MIL_IND_BLINK 1;
BA_ "FlexKomSigStartPos" SG_ 672 MIL_IND_BLINK 1;
BA_ "FlexKomSID" SG_ 672 MIL_IND_BLINK 713;
BA_ "GenSigTimeout_ORC" SG_ 672 MIL_IND_BLINK 350;
BA_ "GenSigTimeout_IC" SG_ 672 MIL_IND_BLINK 1050;
BA_ "FlexKomSigStartValue" SG_ 672 MIL_IND_BLINK "00h";
BA_ "GenSigCycleTime" SG_ 672 MIL_IND_BLINK 100;
BA_ "GenSigSNA" SG_ 672 FuelCons "FFFFh";
BA_ "FlexKomIsMotorola" SG_ 672 FuelCons 1;
BA_ "FlexKomComment" SG_ 672 FuelCons "Fuel consumption";
BA_ "FlexKomSigName" SG_ 672 FuelCons "FuelCons";
BA_ "FlexKomSigLaenge" SG_ 672 FuelCons 16;
BA_ "FlexKomSigStartPos" SG_ 672 FuelCons 39;
BA_ "FlexKomSID" SG_ 672 FuelCons 443;
BA_ "GenSigTimeout_IC" SG_ 672 FuelCons 1050;
BA_ "GenSigTimeout_CBC" SG_ 672 FuelCons 1050;
BA_ "GenSigStartValue" SG_ 672 FuelCons 65535;
BA_ "FlexKomSigStartValue" SG_ 672 FuelCons "FFFFh";
BA_ "GenSigCycleTime" SG_ 672 FuelCons 100;
BA_ "GenSigSNA" SG_ 672 ETC_IND_LMP "3h";
BA_ "FlexKomIsMotorola" SG_ 672 ETC_IND_LMP 1;
BA_ "FlexKomComment" SG_ 672 ETC_IND_LMP "ETC faulty, indicator lamp request";
BA_ "FlexKomSigName" SG_ 672 ETC_IND_LMP "ETC_IND_LMP";
BA_ "FlexKomSigLaenge" SG_ 672 ETC_IND_LMP 2;
BA_ "FlexKomSigStartPos" SG_ 672 ETC_IND_LMP 3;
BA_ "FlexKomSID" SG_ 672 ETC_IND_LMP 712;
BA_ "GenSigTimeout_ETM" SG_ 672 ETC_IND_LMP 1050;
BA_ "GenSigTimeout_IC" SG_ 672 ETC_IND_LMP 1050;
BA_ "FlexKomSigStartValue" SG_ 672 ETC_IND_LMP "00h";
BA_ "GenSigCycleTime" SG_ 672 ETC_IND_LMP 100;
BA_ "GenSigSNA" SG_ 672 EngRun_Stat "7h";
BA_ "FlexKomIsMotorola" SG_ 672 EngRun_Stat 1;
BA_ "FlexKomComment" SG_ 672 EngRun_Stat "Engine running state";
BA_ "FlexKomSigName" SG_ 672 EngRun_Stat "EngRun_Stat";
BA_ "FlexKomSigLaenge" SG_ 672 EngRun_Stat 3;
BA_ "FlexKomSigStartPos" SG_ 672 EngRun_Stat 58;
BA_ "FlexKomSID" SG_ 672 EngRun_Stat 1081;
BA_ "GenSigTimeout_IC" SG_ 672 EngRun_Stat 1050;
BA_ "GenSigTimeout_CBC" SG_ 672 EngRun_Stat 1050;
BA_ "GenSigStartValue" SG_ 672 EngRun_Stat 7;
BA_ "FlexKomSigStartValue" SG_ 672 EngRun_Stat "07h";
BA_ "GenSigCycleTime" SG_ 672 EngRun_Stat 100;
BA_ "GenSigSNA" SG_ 672 EngOilTemp "FFh";
BA_ "FlexKomIsMotorola" SG_ 672 EngOilTemp 1;
BA_ "FlexKomComment" SG_ 672 EngOilTemp "Oil temperature";
BA_ "FlexKomSigName" SG_ 672 EngOilTemp "EngOilTemp";
BA_ "FlexKomSigLaenge" SG_ 672 EngOilTemp 8;
BA_ "FlexKomSigStartPos" SG_ 672 EngOilTemp 31;
BA_ "FlexKomSID" SG_ 672 EngOilTemp 440;
BA_ "GenSigTimeout_IC" SG_ 672 EngOilTemp 1050;
BA_ "GenSigTimeout_CBC" SG_ 672 EngOilTemp 1050;
BA_ "GenSigStartValue" SG_ 672 EngOilTemp 255;
BA_ "FlexKomSigStartValue" SG_ 672 EngOilTemp "FFh";
BA_ "GenSigCycleTime" SG_ 672 EngOilTemp 100;
BA_ "GenSigSNA" SG_ 672 EngOilIndLmp_On_Rq "1h";
BA_ "FlexKomIsMotorola" SG_ 672 EngOilIndLmp_On_Rq 1;
BA_ "FlexKomComment" SG_ 672 EngOilIndLmp_On_Rq "Request oil level/oil pressure indicator lamp";
BA_ "FlexKomSigName" SG_ 672 EngOilIndLmp_On_Rq "EngOilIndLmp_On_Rq";
BA_ "FlexKomSigLaenge" SG_ 672 EngOilIndLmp_On_Rq 1;
BA_ "FlexKomSigStartPos" SG_ 672 EngOilIndLmp_On_Rq 10;
BA_ "FlexKomSID" SG_ 672 EngOilIndLmp_On_Rq 1080;
BA_ "GenSigTimeout_ETM" SG_ 672 EngOilIndLmp_On_Rq 1050;
BA_ "GenSigTimeout_IC" SG_ 672 EngOilIndLmp_On_Rq 1050;
BA_ "FlexKomSigStartValue" SG_ 672 EngOilIndLmp_On_Rq "00h";
BA_ "GenSigCycleTime" SG_ 672 EngOilIndLmp_On_Rq 100;
BA_ "GenSigSNA" SG_ 672 DefFuelEcon "FFh";
BA_ "FlexKomIsMotorola" SG_ 672 DefFuelEcon 1;
BA_ "FlexKomComment" SG_ 672 DefFuelEcon "Default fuel economy";
BA_ "FlexKomSigName" SG_ 672 DefFuelEcon "DefFuelEcon";
BA_ "FlexKomSigLaenge" SG_ 672 DefFuelEcon 8;
BA_ "FlexKomSigStartPos" SG_ 672 DefFuelEcon 55;
BA_ "FlexKomSID" SG_ 672 DefFuelEcon 709;
BA_ "GenSigTimeout_IC" SG_ 672 DefFuelEcon 1050;
BA_ "GenSigStartValue" SG_ 672 DefFuelEcon 255;
BA_ "FlexKomSigStartValue" SG_ 672 DefFuelEcon "FFh";
BA_ "GenSigCycleTime" SG_ 672 DefFuelEcon 100;
BA_ "GenMsgStartValue" BO_ 671 "04000000000000FFh";
BA_ "GenMsgNrOfRepetitions" BO_ 671 2;
BA_ "GenMsgDelayTime" BO_ 671 20;
BA_ "GenMsgCycleTime" BO_ 671 20;
BA_ "GenSigSNA" SG_ 671 TorqueOverlaySteeringReq "400h";
BA_ "FlexKomIsMotorola" SG_ 671 TorqueOverlaySteeringReq 1;
BA_ "FlexKomComment" SG_ 671 TorqueOverlaySteeringReq "PTS steering control packet";
BA_ "FlexKomSigName" SG_ 671 TorqueOverlaySteeringReq "PTS_StrCtrl";
BA_ "FlexKomSigLaenge" SG_ 671 TorqueOverlaySteeringReq 64;
BA_ "FlexKomSigStartPos" SG_ 671 TorqueOverlaySteeringReq 7;
BA_ "FlexKomSID" SG_ 671 TorqueOverlaySteeringReq 1907;
BA_ "GenSigStartValue" SG_ 671 TorqueOverlaySteeringReq 1024;
BA_ "FlexKomSigStartValue" SG_ 671 TorqueOverlaySteeringReq "04000000000000FFh";
BA_ "GenSigCycleTime" SG_ 671 TorqueOverlaySteeringReq 20;
BA_ "GenSigSNA" SG_ 671 TorqueOverlayIntActivation "0h";
BA_ "FlexKomIsMotorola" SG_ 671 TorqueOverlayIntActivation 1;
BA_ "FlexKomComment" SG_ 671 TorqueOverlayIntActivation "PTS steering control packet";
BA_ "FlexKomSigName" SG_ 671 TorqueOverlayIntActivation "PTS_StrCtrl";
BA_ "FlexKomSigLaenge" SG_ 671 TorqueOverlayIntActivation 64;
BA_ "FlexKomSigStartPos" SG_ 671 TorqueOverlayIntActivation 7;
BA_ "FlexKomSID" SG_ 671 TorqueOverlayIntActivation 1907;
BA_ "FlexKomSigStartValue" SG_ 671 TorqueOverlayIntActivation "04000000000000FFh";
BA_ "GenSigCycleTime" SG_ 671 TorqueOverlayIntActivation 20;
BA_ "GenSigSNA" SG_ 671 PTSSystemFault "0h";
BA_ "FlexKomIsMotorola" SG_ 671 PTSSystemFault 1;
BA_ "FlexKomComment" SG_ 671 PTSSystemFault "PTS steering control packet";
BA_ "FlexKomSigName" SG_ 671 PTSSystemFault "PTS_StrCtrl";
BA_ "FlexKomSigLaenge" SG_ 671 PTSSystemFault 64;
BA_ "FlexKomSigStartPos" SG_ 671 PTSSystemFault 7;
BA_ "FlexKomSID" SG_ 671 PTSSystemFault 1907;
BA_ "GenSigTimeout_IC" SG_ 671 PTSSystemFault 210;
BA_ "FlexKomSigStartValue" SG_ 671 PTSSystemFault "04000000000000FFh";
BA_ "GenSigCycleTime" SG_ 671 PTSSystemFault 20;
BA_ "GenSigSNA" SG_ 671 PTSDriveStyleReqSts "0h";
BA_ "FlexKomIsMotorola" SG_ 671 PTSDriveStyleReqSts 1;
BA_ "FlexKomComment" SG_ 671 PTSDriveStyleReqSts "PTS steering control packet";
BA_ "FlexKomSigName" SG_ 671 PTSDriveStyleReqSts "PTS_StrCtrl";
BA_ "FlexKomSigLaenge" SG_ 671 PTSDriveStyleReqSts 64;
BA_ "FlexKomSigStartPos" SG_ 671 PTSDriveStyleReqSts 7;
BA_ "FlexKomSID" SG_ 671 PTSDriveStyleReqSts 1907;
BA_ "FlexKomSigStartValue" SG_ 671 PTSDriveStyleReqSts "04000000000000FFh";
BA_ "GenSigCycleTime" SG_ 671 PTSDriveStyleReqSts 20;
BA_ "GenSigSNA" SG_ 671 PTS_ManoeuvreMode "7h";
BA_ "FlexKomIsMotorola" SG_ 671 PTS_ManoeuvreMode 1;
BA_ "FlexKomComment" SG_ 671 PTS_ManoeuvreMode "PTS steering control packet";
BA_ "FlexKomSigName" SG_ 671 PTS_ManoeuvreMode "PTS_StrCtrl";
BA_ "FlexKomSigLaenge" SG_ 671 PTS_ManoeuvreMode 64;
BA_ "FlexKomSigStartPos" SG_ 671 PTS_ManoeuvreMode 7;
BA_ "FlexKomSID" SG_ 671 PTS_ManoeuvreMode 1907;
BA_ "GenSigTimeout_IC" SG_ 671 PTS_ManoeuvreMode 210;
BA_ "FlexKomSigStartValue" SG_ 671 PTS_ManoeuvreMode "04000000000000FFh";
BA_ "GenSigCycleTime" SG_ 671 PTS_ManoeuvreMode 20;
BA_ "GenSigSNA" SG_ 671 MC_29Fh "0h";
BA_ "FlexKomIsMotorola" SG_ 671 MC_29Fh 1;
BA_ "FlexKomComment" SG_ 671 MC_29Fh "PTS steering control packet";
BA_ "FlexKomSigName" SG_ 671 MC_29Fh "PTS_StrCtrl";
BA_ "FlexKomSigLaenge" SG_ 671 MC_29Fh 64;
BA_ "FlexKomSigStartPos" SG_ 671 MC_29Fh 7;
BA_ "FlexKomSID" SG_ 671 MC_29Fh 1907;
BA_ "FlexKomSigStartValue" SG_ 671 MC_29Fh "04000000000000FFh";
BA_ "GenSigCycleTime" SG_ 671 MC_29Fh 20;
BA_ "GenSigSNA" SG_ 671 ManeuverPhase "0h";
BA_ "FlexKomIsMotorola" SG_ 671 ManeuverPhase 1;
BA_ "FlexKomComment" SG_ 671 ManeuverPhase "PTS steering control packet";
BA_ "FlexKomSigName" SG_ 671 ManeuverPhase "PTS_StrCtrl";
BA_ "FlexKomSigLaenge" SG_ 671 ManeuverPhase 64;
BA_ "FlexKomSigStartPos" SG_ 671 ManeuverPhase 7;
BA_ "FlexKomSID" SG_ 671 ManeuverPhase 1907;
BA_ "FlexKomSigStartValue" SG_ 671 ManeuverPhase "04000000000000FFh";
BA_ "GenSigCycleTime" SG_ 671 ManeuverPhase 20;
BA_ "GenSigSNA" SG_ 671 CRC_29Fh "FFh";
BA_ "FlexKomIsMotorola" SG_ 671 CRC_29Fh 1;
BA_ "FlexKomComment" SG_ 671 CRC_29Fh "PTS steering control packet";
BA_ "FlexKomSigName" SG_ 671 CRC_29Fh "PTS_StrCtrl";
BA_ "FlexKomSigLaenge" SG_ 671 CRC_29Fh 64;
BA_ "FlexKomSigStartPos" SG_ 671 CRC_29Fh 7;
BA_ "FlexKomSID" SG_ 671 CRC_29Fh 1907;
BA_ "GenSigStartValue" SG_ 671 CRC_29Fh 255;
BA_ "FlexKomSigStartValue" SG_ 671 CRC_29Fh "04000000000000FFh";
BA_ "GenSigCycleTime" SG_ 671 CRC_29Fh 20;
BA_ "GenMsgStartValue" BO_ 660 "04000000C00000FFh";
BA_ "GenMsgNrOfRepetitions" BO_ 660 2;
BA_ "GenMsgDelayTime" BO_ 660 20;
BA_ "GenMsgCycleTime" BO_ 660 20;
BA_ "GenSigSNA" SG_ 660 TOC_Sts "Fh";
BA_ "FlexKomIsMotorola" SG_ 660 TOC_Sts 1;
BA_ "FlexKomComment" SG_ 660 TOC_Sts "DST_TOC";
BA_ "FlexKomSigName" SG_ 660 TOC_Sts "DST_TOC";
BA_ "FlexKomSigLaenge" SG_ 660 TOC_Sts 64;
BA_ "FlexKomSigStartPos" SG_ 660 TOC_Sts 7;
BA_ "FlexKomSID" SG_ 660 TOC_Sts 1909;
BA_ "FlexKomSigStartValue" SG_ 660 TOC_Sts "04000000C00000FFh";
BA_ "GenSigCycleTime" SG_ 660 TOC_Sts 20;
BA_ "GenSigSNA" SG_ 660 TOC_Fault "3h";
BA_ "FlexKomIsMotorola" SG_ 660 TOC_Fault 1;
BA_ "FlexKomComment" SG_ 660 TOC_Fault "DST_TOC";
BA_ "FlexKomSigName" SG_ 660 TOC_Fault "DST_TOC";
BA_ "FlexKomSigLaenge" SG_ 660 TOC_Fault 64;
BA_ "FlexKomSigStartPos" SG_ 660 TOC_Fault 7;
BA_ "FlexKomSID" SG_ 660 TOC_Fault 1909;
BA_ "FlexKomSigStartValue" SG_ 660 TOC_Fault "04000000C00000FFh";
BA_ "GenSigCycleTime" SG_ 660 TOC_Fault 20;
BA_ "GenSigSNA" SG_ 660 TOC_Act_Req "3h";
BA_ "FlexKomIsMotorola" SG_ 660 TOC_Act_Req 1;
BA_ "FlexKomComment" SG_ 660 TOC_Act_Req "DST_TOC";
BA_ "FlexKomSigName" SG_ 660 TOC_Act_Req "DST_TOC";
BA_ "FlexKomSigLaenge" SG_ 660 TOC_Act_Req 64;
BA_ "FlexKomSigStartPos" SG_ 660 TOC_Act_Req 7;
BA_ "FlexKomSID" SG_ 660 TOC_Act_Req 1909;
BA_ "FlexKomSigStartValue" SG_ 660 TOC_Act_Req "04000000C00000FFh";
BA_ "GenSigCycleTime" SG_ 660 TOC_Act_Req 20;
BA_ "GenSigSNA" SG_ 660 TO_Req "7FFh";
BA_ "FlexKomIsMotorola" SG_ 660 TO_Req 1;
BA_ "FlexKomComment" SG_ 660 TO_Req "DST_TOC";
BA_ "FlexKomSigName" SG_ 660 TO_Req "DST_TOC";
BA_ "FlexKomSigLaenge" SG_ 660 TO_Req 64;
BA_ "FlexKomSigStartPos" SG_ 660 TO_Req 7;
BA_ "FlexKomSID" SG_ 660 TO_Req 1909;
BA_ "GenSigStartValue" SG_ 660 TO_Req 1024;
BA_ "FlexKomSigStartValue" SG_ 660 TO_Req "04000000C00000FFh";
BA_ "GenSigCycleTime" SG_ 660 TO_Req 20;
BA_ "GenSigSNA" SG_ 660 SyncPos "7h";
BA_ "FlexKomIsMotorola" SG_ 660 SyncPos 1;
BA_ "FlexKomComment" SG_ 660 SyncPos "DST_TOC";
BA_ "FlexKomSigName" SG_ 660 SyncPos "DST_TOC";
BA_ "FlexKomSigLaenge" SG_ 660 SyncPos 64;
BA_ "FlexKomSigStartPos" SG_ 660 SyncPos 7;
BA_ "FlexKomSID" SG_ 660 SyncPos 1909;
BA_ "GenSigStartValue" SG_ 660 SyncPos 6;
BA_ "FlexKomSigStartValue" SG_ 660 SyncPos "04000000C00000FFh";
BA_ "GenSigCycleTime" SG_ 660 SyncPos 20;
BA_ "GenSigSNA" SG_ 660 MC_294h "0h";
BA_ "FlexKomIsMotorola" SG_ 660 MC_294h 1;
BA_ "FlexKomComment" SG_ 660 MC_294h "DST_TOC";
BA_ "FlexKomSigName" SG_ 660 MC_294h "DST_TOC";
BA_ "FlexKomSigLaenge" SG_ 660 MC_294h 64;
BA_ "FlexKomSigStartPos" SG_ 660 MC_294h 7;
BA_ "FlexKomSID" SG_ 660 MC_294h 1909;
BA_ "FlexKomSigStartValue" SG_ 660 MC_294h "04000000C00000FFh";
BA_ "GenSigCycleTime" SG_ 660 MC_294h 20;
BA_ "GenSigSNA" SG_ 660 CRC_294h "FFh";
BA_ "FlexKomIsMotorola" SG_ 660 CRC_294h 1;
BA_ "FlexKomComment" SG_ 660 CRC_294h "DST_TOC";
BA_ "FlexKomSigName" SG_ 660 CRC_294h "DST_TOC";
BA_ "FlexKomSigLaenge" SG_ 660 CRC_294h 64;
BA_ "FlexKomSigStartPos" SG_ 660 CRC_294h 7;
BA_ "FlexKomSID" SG_ 660 CRC_294h 1909;
BA_ "GenSigStartValue" SG_ 660 CRC_294h 255;
BA_ "FlexKomSigStartValue" SG_ 660 CRC_294h "04000000C00000FFh";
BA_ "GenSigCycleTime" SG_ 660 CRC_294h 20;
BA_ "GenSigSNA" SG_ 660 BrkPrss_Two "0h";
BA_ "FlexKomIsMotorola" SG_ 660 BrkPrss_Two 1;
BA_ "FlexKomComment" SG_ 660 BrkPrss_Two "DST_TOC";
BA_ "FlexKomSigName" SG_ 660 BrkPrss_Two "DST_TOC";
BA_ "FlexKomSigLaenge" SG_ 660 BrkPrss_Two 64;
BA_ "FlexKomSigStartPos" SG_ 660 BrkPrss_Two 7;
BA_ "FlexKomSID" SG_ 660 BrkPrss_Two 1909;
BA_ "FlexKomSigStartValue" SG_ 660 BrkPrss_Two "04000000C00000FFh";
BA_ "GenSigCycleTime" SG_ 660 BrkPrss_Two 20;
BA_ "GenSigSNA" SG_ 660 BrkPrss_One "0h";
BA_ "FlexKomIsMotorola" SG_ 660 BrkPrss_One 1;
BA_ "FlexKomComment" SG_ 660 BrkPrss_One "DST_TOC";
BA_ "FlexKomSigName" SG_ 660 BrkPrss_One "DST_TOC";
BA_ "FlexKomSigLaenge" SG_ 660 BrkPrss_One 64;
BA_ "FlexKomSigStartPos" SG_ 660 BrkPrss_One 7;
BA_ "FlexKomSID" SG_ 660 BrkPrss_One 1909;
BA_ "FlexKomSigStartValue" SG_ 660 BrkPrss_One "04000000C00000FFh";
BA_ "GenSigCycleTime" SG_ 660 BrkPrss_One 20;
BA_ "GenMsgStartValue" BO_ 658 "0000000000FFh";
BA_ "GenMsgNrOfRepetitions" BO_ 658 2;
BA_ "GenMsgDelayTime" BO_ 658 20;
BA_ "GenMsgCycleTime" BO_ 658 10;
BA_ "GenSigSNA" SG_ 658 MTO_HALFSystemSts "0h";
BA_ "FlexKomIsMotorola" SG_ 658 MTO_HALFSystemSts 1;
BA_ "FlexKomComment" SG_ 658 MTO_HALFSystemSts "Half steering control packet";
BA_ "FlexKomSigName" SG_ 658 MTO_HALFSystemSts "HaLF_StrCtrl";
BA_ "FlexKomSigLaenge" SG_ 658 MTO_HALFSystemSts 48;
BA_ "FlexKomSigStartPos" SG_ 658 MTO_HALFSystemSts 7;
BA_ "FlexKomSID" SG_ 658 MTO_HALFSystemSts 1908;
BA_ "FlexKomSigStartValue" SG_ 658 MTO_HALFSystemSts "0000000000FFh";
BA_ "GenSigCycleTime" SG_ 658 MTO_HALFSystemSts 10;
BA_ "GenSigSNA" SG_ 658 MTO_HALFDriveStyleSts "7h";
BA_ "FlexKomIsMotorola" SG_ 658 MTO_HALFDriveStyleSts 1;
BA_ "FlexKomComment" SG_ 658 MTO_HALFDriveStyleSts "Half steering control packet";
BA_ "FlexKomSigName" SG_ 658 MTO_HALFDriveStyleSts "HaLF_StrCtrl";
BA_ "FlexKomSigLaenge" SG_ 658 MTO_HALFDriveStyleSts 48;
BA_ "FlexKomSigStartPos" SG_ 658 MTO_HALFDriveStyleSts 7;
BA_ "FlexKomSID" SG_ 658 MTO_HALFDriveStyleSts 1908;
BA_ "FlexKomSigStartValue" SG_ 658 MTO_HALFDriveStyleSts "0000000000FFh";
BA_ "GenSigCycleTime" SG_ 658 MTO_HALFDriveStyleSts 10;
BA_ "GenSigSNA" SG_ 658 MotorTorqueOverlaySteeringReq "0h";
BA_ "FlexKomIsMotorola" SG_ 658 MotorTorqueOverlaySteeringReq 1;
BA_ "FlexKomComment" SG_ 658 MotorTorqueOverlaySteeringReq "Half steering control packet";
BA_ "FlexKomSigName" SG_ 658 MotorTorqueOverlaySteeringReq "HaLF_StrCtrl";
BA_ "FlexKomSigLaenge" SG_ 658 MotorTorqueOverlaySteeringReq 48;
BA_ "FlexKomSigStartPos" SG_ 658 MotorTorqueOverlaySteeringReq 7;
BA_ "FlexKomSID" SG_ 658 MotorTorqueOverlaySteeringReq 1908;
BA_ "FlexKomSigStartValue" SG_ 658 MotorTorqueOverlaySteeringReq "0000000000FFh";
BA_ "GenSigCycleTime" SG_ 658 MotorTorqueOverlaySteeringReq 10;
BA_ "GenSigSNA" SG_ 658 MotorTorqueOverlayIntActivation "0h";
BA_ "FlexKomIsMotorola" SG_ 658 MotorTorqueOverlayIntActivation 1;
BA_ "FlexKomComment" SG_ 658 MotorTorqueOverlayIntActivation "Half steering control packet";
BA_ "FlexKomSigName" SG_ 658 MotorTorqueOverlayIntActivation "HaLF_StrCtrl";
BA_ "FlexKomSigLaenge" SG_ 658 MotorTorqueOverlayIntActivation 48;
BA_ "FlexKomSigStartPos" SG_ 658 MotorTorqueOverlayIntActivation 7;
BA_ "FlexKomSID" SG_ 658 MotorTorqueOverlayIntActivation 1908;
BA_ "FlexKomSigStartValue" SG_ 658 MotorTorqueOverlayIntActivation "0000000000FFh";
BA_ "GenSigCycleTime" SG_ 658 MotorTorqueOverlayIntActivation 10;
BA_ "GenSigSNA" SG_ 658 MC_292h "0h";
BA_ "FlexKomIsMotorola" SG_ 658 MC_292h 1;
BA_ "FlexKomComment" SG_ 658 MC_292h "Half steering control packet";
BA_ "FlexKomSigName" SG_ 658 MC_292h "HaLF_StrCtrl";
BA_ "FlexKomSigLaenge" SG_ 658 MC_292h 48;
BA_ "FlexKomSigStartPos" SG_ 658 MC_292h 7;
BA_ "FlexKomSID" SG_ 658 MC_292h 1908;
BA_ "FlexKomSigStartValue" SG_ 658 MC_292h "0000000000FFh";
BA_ "GenSigCycleTime" SG_ 658 MC_292h 10;
BA_ "GenSigSNA" SG_ 658 CRC_292h "FFh";
BA_ "FlexKomIsMotorola" SG_ 658 CRC_292h 1;
BA_ "FlexKomComment" SG_ 658 CRC_292h "Half steering control packet";
BA_ "FlexKomSigName" SG_ 658 CRC_292h "HaLF_StrCtrl";
BA_ "FlexKomSigLaenge" SG_ 658 CRC_292h 48;
BA_ "FlexKomSigStartPos" SG_ 658 CRC_292h 7;
BA_ "FlexKomSID" SG_ 658 CRC_292h 1908;
BA_ "GenSigStartValue" SG_ 658 CRC_292h 255;
BA_ "FlexKomSigStartValue" SG_ 658 CRC_292h "0000000000FFh";
BA_ "GenSigCycleTime" SG_ 658 CRC_292h 10;
BA_ "GenMsgStartValue" BO_ 656 "00000000h";
BA_ "GenMsgNrOfRepetitions" BO_ 656 2;
BA_ "GenMsgDelayTime" BO_ 656 20;
BA_ "GenMsgSendType" BO_ 656 1;
BA_ "GenSigSNA" SG_ 656 UConnSeed4 "0h";
BA_ "FlexKomIsMotorola" SG_ 656 UConnSeed4 1;
BA_ "FlexKomComment" SG_ 656 UConnSeed4 "RF hub characters";
BA_ "FlexKomSigName" SG_ 656 UConnSeed4 "RF_CharPkt";
BA_ "FlexKomSigLaenge" SG_ 656 UConnSeed4 32;
BA_ "FlexKomSigStartPos" SG_ 656 UConnSeed4 7;
BA_ "FlexKomSID" SG_ 656 UConnSeed4 1794;
BA_ "FlexKomSigStartValue" SG_ 656 UConnSeed4 "00000000h";
BA_ "GenSigSendType" SG_ 656 UConnSeed4 1;
BA_ "GenSigSNA" SG_ 656 UConnSeed3 "0h";
BA_ "FlexKomIsMotorola" SG_ 656 UConnSeed3 1;
BA_ "FlexKomComment" SG_ 656 UConnSeed3 "RF hub characters";
BA_ "FlexKomSigName" SG_ 656 UConnSeed3 "RF_CharPkt";
BA_ "FlexKomSigLaenge" SG_ 656 UConnSeed3 32;
BA_ "FlexKomSigStartPos" SG_ 656 UConnSeed3 7;
BA_ "FlexKomSID" SG_ 656 UConnSeed3 1794;
BA_ "FlexKomSigStartValue" SG_ 656 UConnSeed3 "00000000h";
BA_ "GenSigSendType" SG_ 656 UConnSeed3 1;
BA_ "GenSigSNA" SG_ 656 UConnSeed2 "0h";
BA_ "FlexKomIsMotorola" SG_ 656 UConnSeed2 1;
BA_ "FlexKomComment" SG_ 656 UConnSeed2 "RF hub characters";
BA_ "FlexKomSigName" SG_ 656 UConnSeed2 "RF_CharPkt";
BA_ "FlexKomSigLaenge" SG_ 656 UConnSeed2 32;
BA_ "FlexKomSigStartPos" SG_ 656 UConnSeed2 7;
BA_ "FlexKomSID" SG_ 656 UConnSeed2 1794;
BA_ "FlexKomSigStartValue" SG_ 656 UConnSeed2 "00000000h";
BA_ "GenSigSendType" SG_ 656 UConnSeed2 1;
BA_ "GenSigSNA" SG_ 656 UConnSeed1 "0h";
BA_ "FlexKomIsMotorola" SG_ 656 UConnSeed1 1;
BA_ "FlexKomComment" SG_ 656 UConnSeed1 "RF hub characters";
BA_ "FlexKomSigName" SG_ 656 UConnSeed1 "RF_CharPkt";
BA_ "FlexKomSigLaenge" SG_ 656 UConnSeed1 32;
BA_ "FlexKomSigStartPos" SG_ 656 UConnSeed1 7;
BA_ "FlexKomSID" SG_ 656 UConnSeed1 1794;
BA_ "FlexKomSigStartValue" SG_ 656 UConnSeed1 "00000000h";
BA_ "GenSigSendType" SG_ 656 UConnSeed1 1;
BA_ "GenMsgStartValue" BO_ 653 "0000000000000000h";
BA_ "GenMsgNrOfRepetitions" BO_ 653 2;
BA_ "GenMsgDelayTime" BO_ 653 20;
BA_ "GenMsgCycleTime" BO_ 653 20;
BA_ "GenSigSNA" SG_ 653 MIL_OnRq_EBCM "0h";
BA_ "FlexKomIsMotorola" SG_ 653 MIL_OnRq_EBCM 1;
BA_ "FlexKomComment" SG_ 653 MIL_OnRq_EBCM "Message EBCM_C1 packet";
BA_ "FlexKomSigName" SG_ 653 MIL_OnRq_EBCM "EBCM_C1_Pkt";
BA_ "FlexKomSigLaenge" SG_ 653 MIL_OnRq_EBCM 64;
BA_ "FlexKomSigStartPos" SG_ 653 MIL_OnRq_EBCM 7;
BA_ "FlexKomSID" SG_ 653 MIL_OnRq_EBCM 2377;
BA_ "FlexKomSigStartValue" SG_ 653 MIL_OnRq_EBCM "0000000000000000h";
BA_ "GenSigCycleTime" SG_ 653 MIL_OnRq_EBCM 20;
BA_ "GenSigSNA" SG_ 653 EBCMSysEmsMlfAtv "0h";
BA_ "FlexKomIsMotorola" SG_ 653 EBCMSysEmsMlfAtv 1;
BA_ "FlexKomComment" SG_ 653 EBCMSysEmsMlfAtv "Message EBCM_C1 packet";
BA_ "FlexKomSigName" SG_ 653 EBCMSysEmsMlfAtv "EBCM_C1_Pkt";
BA_ "FlexKomSigLaenge" SG_ 653 EBCMSysEmsMlfAtv 64;
BA_ "FlexKomSigStartPos" SG_ 653 EBCMSysEmsMlfAtv 7;
BA_ "FlexKomSID" SG_ 653 EBCMSysEmsMlfAtv 2377;
BA_ "FlexKomSigStartValue" SG_ 653 EBCMSysEmsMlfAtv "0000000000000000h";
BA_ "GenSigCycleTime" SG_ 653 EBCMSysEmsMlfAtv 20;
BA_ "GenSigCycleTime" SG_ 653 BrakePedalTravelSensorV 20;
BA_ "FlexKomSigStartValue" SG_ 653 BrakePedalTravelSensorV "0000000000000000h";
BA_ "FlexKomSID" SG_ 653 BrakePedalTravelSensorV 2377;
BA_ "FlexKomSigStartPos" SG_ 653 BrakePedalTravelSensorV 7;
BA_ "FlexKomSigLaenge" SG_ 653 BrakePedalTravelSensorV 64;
BA_ "FlexKomSigName" SG_ 653 BrakePedalTravelSensorV "EBCM_C1_Pkt";
BA_ "FlexKomComment" SG_ 653 BrakePedalTravelSensorV "Message EBCM_C1 packet";
BA_ "FlexKomIsMotorola" SG_ 653 BrakePedalTravelSensorV 1;
BA_ "GenSigSNA" SG_ 653 BrakePedalTravelSensorV "0h";
BA_ "GenSigCycleTime" SG_ 653 BrakePedalTravelSensor 20;
BA_ "FlexKomSigStartValue" SG_ 653 BrakePedalTravelSensor "0000000000000000h";
BA_ "FlexKomSID" SG_ 653 BrakePedalTravelSensor 2377;
BA_ "FlexKomSigStartPos" SG_ 653 BrakePedalTravelSensor 7;
BA_ "FlexKomSigLaenge" SG_ 653 BrakePedalTravelSensor 64;
BA_ "FlexKomSigName" SG_ 653 BrakePedalTravelSensor "EBCM_C1_Pkt";
BA_ "FlexKomComment" SG_ 653 BrakePedalTravelSensor "Message EBCM_C1 packet";
BA_ "FlexKomIsMotorola" SG_ 653 BrakePedalTravelSensor 1;
BA_ "GenSigSNA" SG_ 653 BrakePedalTravelSensor "FFh";
BA_ "GenSigSNA" SG_ 653 BrakePedalAppliedV "0h";
BA_ "FlexKomIsMotorola" SG_ 653 BrakePedalAppliedV 1;
BA_ "FlexKomComment" SG_ 653 BrakePedalAppliedV "Message EBCM_C1 packet";
BA_ "FlexKomSigName" SG_ 653 BrakePedalAppliedV "EBCM_C1_Pkt";
BA_ "FlexKomSigLaenge" SG_ 653 BrakePedalAppliedV 64;
BA_ "FlexKomSigStartPos" SG_ 653 BrakePedalAppliedV 7;
BA_ "FlexKomSID" SG_ 653 BrakePedalAppliedV 2377;
BA_ "FlexKomSigStartValue" SG_ 653 BrakePedalAppliedV "0000000000000000h";
BA_ "GenSigCycleTime" SG_ 653 BrakePedalAppliedV 20;
BA_ "GenSigSNA" SG_ 653 BrakePedalApplied "0h";
BA_ "FlexKomIsMotorola" SG_ 653 BrakePedalApplied 1;
BA_ "FlexKomComment" SG_ 653 BrakePedalApplied "Message EBCM_C1 packet";
BA_ "FlexKomSigName" SG_ 653 BrakePedalApplied "EBCM_C1_Pkt";
BA_ "FlexKomSigLaenge" SG_ 653 BrakePedalApplied 64;
BA_ "FlexKomSigStartPos" SG_ 653 BrakePedalApplied 7;
BA_ "FlexKomSID" SG_ 653 BrakePedalApplied 2377;
BA_ "FlexKomSigStartValue" SG_ 653 BrakePedalApplied "0000000000000000h";
BA_ "GenSigCycleTime" SG_ 653 BrakePedalApplied 20;
BA_ "GenMsgStartDelayTime" BO_ 639 90;
BA_ "GenMsgStartValue" BO_ 639 "FFFFFFFF00000000h";
BA_ "GenMsgNrOfRepetitions" BO_ 639 2;
BA_ "GenMsgDelayTime" BO_ 639 20;
BA_ "GenMsgCycleTime" BO_ 639 1000;
BA_ "GenSigSNA" SG_ 639 IBS_Tm_Lst_Reset_Sec "FFFFh";
BA_ "FlexKomIsMotorola" SG_ 639 IBS_Tm_Lst_Reset_Sec 1;
BA_ "FlexKomComment" SG_ 639 IBS_Tm_Lst_Reset_Sec "LIN to CAN C IBS data";
BA_ "FlexKomSigName" SG_ 639 IBS_Tm_Lst_Reset_Sec "GW_IBS_DataPkt";
BA_ "FlexKomSigLaenge" SG_ 639 IBS_Tm_Lst_Reset_Sec 64;
BA_ "FlexKomSigStartPos" SG_ 639 IBS_Tm_Lst_Reset_Sec 7;
BA_ "FlexKomSID" SG_ 639 IBS_Tm_Lst_Reset_Sec 1855;
BA_ "FlexKomSigStartValue" SG_ 639 IBS_Tm_Lst_Reset_Sec "FFFFFFFF00000000h";
BA_ "GenSigCycleTime" SG_ 639 IBS_Tm_Lst_Reset_Sec 1000;
BA_ "GenSigSNA" SG_ 639 IBS_Tm_Lst_Reset_Days "FFFh";
BA_ "FlexKomIsMotorola" SG_ 639 IBS_Tm_Lst_Reset_Days 1;
BA_ "FlexKomComment" SG_ 639 IBS_Tm_Lst_Reset_Days "LIN to CAN C IBS data";
BA_ "FlexKomSigName" SG_ 639 IBS_Tm_Lst_Reset_Days "GW_IBS_DataPkt";
BA_ "FlexKomSigLaenge" SG_ 639 IBS_Tm_Lst_Reset_Days 64;
BA_ "FlexKomSigStartPos" SG_ 639 IBS_Tm_Lst_Reset_Days 7;
BA_ "FlexKomSID" SG_ 639 IBS_Tm_Lst_Reset_Days 1855;
BA_ "FlexKomSigStartValue" SG_ 639 IBS_Tm_Lst_Reset_Days "FFFFFFFF00000000h";
BA_ "GenSigCycleTime" SG_ 639 IBS_Tm_Lst_Reset_Days 1000;
BA_ "GenSigSNA" SG_ 639 IBS_Q_released "FFFFh";
BA_ "FlexKomIsMotorola" SG_ 639 IBS_Q_released 1;
BA_ "FlexKomComment" SG_ 639 IBS_Q_released "LIN to CAN C IBS data";
BA_ "FlexKomSigName" SG_ 639 IBS_Q_released "GW_IBS_DataPkt";
BA_ "FlexKomSigLaenge" SG_ 639 IBS_Q_released 64;
BA_ "FlexKomSigStartPos" SG_ 639 IBS_Q_released 7;
BA_ "FlexKomSID" SG_ 639 IBS_Q_released 1855;
BA_ "GenSigStartValue" SG_ 639 IBS_Q_released 65535;
BA_ "FlexKomSigStartValue" SG_ 639 IBS_Q_released "FFFFFFFF00000000h";
BA_ "GenSigCycleTime" SG_ 639 IBS_Q_released 1000;
BA_ "GenSigSNA" SG_ 639 IBS_Q_received "FFFFh";
BA_ "FlexKomIsMotorola" SG_ 639 IBS_Q_received 1;
BA_ "FlexKomComment" SG_ 639 IBS_Q_received "LIN to CAN C IBS data";
BA_ "FlexKomSigName" SG_ 639 IBS_Q_received "GW_IBS_DataPkt";
BA_ "FlexKomSigLaenge" SG_ 639 IBS_Q_received 64;
BA_ "FlexKomSigStartPos" SG_ 639 IBS_Q_received 7;
BA_ "FlexKomSID" SG_ 639 IBS_Q_received 1855;
BA_ "GenSigStartValue" SG_ 639 IBS_Q_received 65535;
BA_ "FlexKomSigStartValue" SG_ 639 IBS_Q_received "FFFFFFFF00000000h";
BA_ "GenSigCycleTime" SG_ 639 IBS_Q_received 1000;
BA_ "GenMsgStartValue" BO_ 632 "FF00FFFF00FF0000h";
BA_ "GenMsgNrOfRepetitions" BO_ 632 2;
BA_ "GenMsgDelayTime" BO_ 632 20;
BA_ "GenMsgCycleTime" BO_ 632 100;
BA_ "GenSigCycleTime" SG_ 632 SpStWarnStat 100;
BA_ "FlexKomSigStartValue" SG_ 632 SpStWarnStat "0000h";
BA_ "GenSigTimeout_IC" SG_ 632 SpStWarnStat 1050;
BA_ "GenSigTimeout_ORC" SG_ 632 SpStWarnStat 350;
BA_ "FlexKomSID" SG_ 632 SpStWarnStat 1567;
BA_ "FlexKomSigStartPos" SG_ 632 SpStWarnStat 55;
BA_ "FlexKomSigLaenge" SG_ 632 SpStWarnStat 16;
BA_ "FlexKomSigName" SG_ 632 SpStWarnStat "SpStPacket";
BA_ "FlexKomComment" SG_ 632 SpStWarnStat "Stop start packet";
BA_ "FlexKomIsMotorola" SG_ 632 SpStWarnStat 1;
BA_ "GenSigSNA" SG_ 632 SpStWarnStat "Fh";
BA_ "GenSigSNA" SG_ 632 SpStSwStat "3h";
BA_ "FlexKomIsMotorola" SG_ 632 SpStSwStat 1;
BA_ "FlexKomComment" SG_ 632 SpStSwStat "Stop start packet";
BA_ "FlexKomSigName" SG_ 632 SpStSwStat "SpStPacket";
BA_ "FlexKomSigLaenge" SG_ 632 SpStSwStat 16;
BA_ "FlexKomSigStartPos" SG_ 632 SpStSwStat 55;
BA_ "FlexKomSID" SG_ 632 SpStSwStat 1567;
BA_ "GenSigTimeout_ORC" SG_ 632 SpStSwStat 350;
BA_ "GenSigTimeout_IC" SG_ 632 SpStSwStat 1050;
BA_ "GenSigTimeout_CBC" SG_ 632 SpStSwStat 1050;
BA_ "FlexKomSigStartValue" SG_ 632 SpStSwStat "0000h";
BA_ "GenSigCycleTime" SG_ 632 SpStSwStat 100;
BA_ "GenSigCycleTime" SG_ 632 SpStDispstat 100;
BA_ "FlexKomSigStartValue" SG_ 632 SpStDispstat "0000h";
BA_ "GenSigTimeout_IC" SG_ 632 SpStDispstat 1050;
BA_ "GenSigTimeout_ORC" SG_ 632 SpStDispstat 350;
BA_ "FlexKomSID" SG_ 632 SpStDispstat 1567;
BA_ "FlexKomSigStartPos" SG_ 632 SpStDispstat 55;
BA_ "FlexKomSigLaenge" SG_ 632 SpStDispstat 16;
BA_ "FlexKomSigName" SG_ 632 SpStDispstat "SpStPacket";
BA_ "FlexKomComment" SG_ 632 SpStDispstat "Stop start packet";
BA_ "FlexKomIsMotorola" SG_ 632 SpStDispstat 1;
BA_ "GenSigSNA" SG_ 632 SpStDispstat "3Fh";
BA_ "FlexKomComment" SG_ 632 ESS_ActvEBrake "ESS active E-brake. 1 = Active, 0 = Inactive";
BA_ "GenSigCycleTime" SG_ 632 ESS_ActvEBrake 100;
BA_ "FlexKomSigStartValue" SG_ 632 ESS_ActvEBrake "00h";
BA_ "FlexKomSID" SG_ 632 ESS_ActvEBrake 2528;
BA_ "FlexKomSigStartPos" SG_ 632 ESS_ActvEBrake 38;
BA_ "FlexKomSigLaenge" SG_ 632 ESS_ActvEBrake 1;
BA_ "FlexKomSigName" SG_ 632 ESS_ActvEBrake "ESS_ActvEBrake";
BA_ "FlexKomIsMotorola" SG_ 632 ESS_ActvEBrake 1;
BA_ "GenSigSNA" SG_ 632 ESS_ActvEBrake "0h";
BA_ "GenSigSNA" SG_ 632 CC_SetSpdDsplMPH "FFh";
BA_ "FlexKomIsMotorola" SG_ 632 CC_SetSpdDsplMPH 1;
BA_ "FlexKomComment" SG_ 632 CC_SetSpdDsplMPH "Cruise control set speed for display in miles per ";
BA_ "FlexKomSigName" SG_ 632 CC_SetSpdDsplMPH "CC_SetSpdDsplMPH";
BA_ "FlexKomSigLaenge" SG_ 632 CC_SetSpdDsplMPH 8;
BA_ "FlexKomSigStartPos" SG_ 632 CC_SetSpdDsplMPH 47;
BA_ "FlexKomSID" SG_ 632 CC_SetSpdDsplMPH 1610;
BA_ "GenSigTimeout_IC" SG_ 632 CC_SetSpdDsplMPH 1050;
BA_ "GenSigStartValue" SG_ 632 CC_SetSpdDsplMPH 255;
BA_ "FlexKomSigStartValue" SG_ 632 CC_SetSpdDsplMPH "FFh";
BA_ "GenSigCycleTime" SG_ 632 CC_SetSpdDsplMPH 100;
BA_ "GenSigSNA" SG_ 632 CC_SetSpdDspl "FFh";
BA_ "FlexKomIsMotorola" SG_ 632 CC_SetSpdDspl 1;
BA_ "FlexKomComment" SG_ 632 CC_SetSpdDspl "Cruise control set speed for display (kmph only)";
BA_ "FlexKomSigName" SG_ 632 CC_SetSpdDspl "CC_SetSpdDspl";
BA_ "FlexKomSigLaenge" SG_ 632 CC_SetSpdDspl 8;
BA_ "FlexKomSigStartPos" SG_ 632 CC_SetSpdDspl 7;
BA_ "FlexKomSID" SG_ 632 CC_SetSpdDspl 1361;
BA_ "GenSigTimeout_IC" SG_ 632 CC_SetSpdDspl 1050;
BA_ "GenSigStartValue" SG_ 632 CC_SetSpdDspl 255;
BA_ "FlexKomSigStartValue" SG_ 632 CC_SetSpdDspl "FFh";
BA_ "GenSigCycleTime" SG_ 632 CC_SetSpdDspl 100;
BA_ "GenMsgStartValue" BO_ 625 "000000FF000000FFh";
BA_ "GenMsgNrOfRepetitions" BO_ 625 2;
BA_ "GenMsgDelayTime" BO_ 625 20;
BA_ "GenMsgCycleTime" BO_ 625 20;
BA_ "GenSigSNA" SG_ 625 WhlTrqRq_DAS "7FFFh";
BA_ "FlexKomIsMotorola" SG_ 625 WhlTrqRq_DAS 1;
BA_ "FlexKomComment" SG_ 625 WhlTrqRq_DAS "DAS_A5 Packet";
BA_ "FlexKomSigName" SG_ 625 WhlTrqRq_DAS "DAS_A5_PKT";
BA_ "FlexKomSigLaenge" SG_ 625 WhlTrqRq_DAS 64;
BA_ "FlexKomSigStartPos" SG_ 625 WhlTrqRq_DAS 7;
BA_ "FlexKomSID" SG_ 625 WhlTrqRq_DAS 2333;
BA_ "FlexKomSigStartValue" SG_ 625 WhlTrqRq_DAS "000000FF000000FFh";
BA_ "GenSigCycleTime" SG_ 625 WhlTrqRq_DAS 20;
BA_ "GenSigSNA" SG_ 625 WhlTrqActRq_DAS "0h";
BA_ "FlexKomIsMotorola" SG_ 625 WhlTrqActRq_DAS 1;
BA_ "FlexKomComment" SG_ 625 WhlTrqActRq_DAS "DAS_A5 Packet";
BA_ "FlexKomSigName" SG_ 625 WhlTrqActRq_DAS "DAS_A5_PKT";
BA_ "FlexKomSigLaenge" SG_ 625 WhlTrqActRq_DAS 64;
BA_ "FlexKomSigStartPos" SG_ 625 WhlTrqActRq_DAS 7;
BA_ "FlexKomSID" SG_ 625 WhlTrqActRq_DAS 2333;
BA_ "FlexKomSigStartValue" SG_ 625 WhlTrqActRq_DAS "000000FF000000FFh";
BA_ "GenSigCycleTime" SG_ 625 WhlTrqActRq_DAS 20;
BA_ "GenSigSNA" SG_ 625 MC_DAS_A5 "0h";
BA_ "FlexKomIsMotorola" SG_ 625 MC_DAS_A5 1;
BA_ "FlexKomComment" SG_ 625 MC_DAS_A5 "DAS_A5 Packet";
BA_ "FlexKomSigName" SG_ 625 MC_DAS_A5 "DAS_A5_PKT";
BA_ "FlexKomSigLaenge" SG_ 625 MC_DAS_A5 64;
BA_ "FlexKomSigStartPos" SG_ 625 MC_DAS_A5 7;
BA_ "FlexKomSID" SG_ 625 MC_DAS_A5 2333;
BA_ "FlexKomSigStartValue" SG_ 625 MC_DAS_A5 "000000FF000000FFh";
BA_ "GenSigCycleTime" SG_ 625 MC_DAS_A5 20;
BA_ "GenSigSNA" SG_ 625 FCWState "0h";
BA_ "FlexKomIsMotorola" SG_ 625 FCWState 1;
BA_ "FlexKomComment" SG_ 625 FCWState "DAS_A5 Packet";
BA_ "FlexKomSigName" SG_ 625 FCWState "DAS_A5_PKT";
BA_ "FlexKomSigLaenge" SG_ 625 FCWState 64;
BA_ "FlexKomSigStartPos" SG_ 625 FCWState 7;
BA_ "FlexKomSID" SG_ 625 FCWState 2333;
BA_ "GenSigTimeout_ORC" SG_ 625 FCWState 70;
BA_ "GenSigTimeout_IC" SG_ 625 FCWState 210;
BA_ "FlexKomSigStartValue" SG_ 625 FCWState "000000FF000000FFh";
BA_ "GenSigCycleTime" SG_ 625 FCWState 20;
BA_ "GenSigSNA" SG_ 625 FCWSettingTeen "0h";
BA_ "FlexKomIsMotorola" SG_ 625 FCWSettingTeen 1;
BA_ "FlexKomComment" SG_ 625 FCWSettingTeen "DAS_A5 Packet";
BA_ "FlexKomSigName" SG_ 625 FCWSettingTeen "DAS_A5_PKT";
BA_ "FlexKomSigLaenge" SG_ 625 FCWSettingTeen 64;
BA_ "FlexKomSigStartPos" SG_ 625 FCWSettingTeen 7;
BA_ "FlexKomSID" SG_ 625 FCWSettingTeen 2333;
BA_ "GenSigTimeout_ORC" SG_ 625 FCWSettingTeen 70;
BA_ "GenSigTimeout_IC" SG_ 625 FCWSettingTeen 210;
BA_ "GenSigTimeout_CBC" SG_ 625 FCWSettingTeen 210;
BA_ "FlexKomSigStartValue" SG_ 625 FCWSettingTeen "000000FF000000FFh";
BA_ "GenSigCycleTime" SG_ 625 FCWSettingTeen 20;
BA_ "GenSigSNA" SG_ 625 FCWSetting "0h";
BA_ "FlexKomIsMotorola" SG_ 625 FCWSetting 1;
BA_ "FlexKomComment" SG_ 625 FCWSetting "DAS_A5 Packet";
BA_ "FlexKomSigName" SG_ 625 FCWSetting "DAS_A5_PKT";
BA_ "FlexKomSigLaenge" SG_ 625 FCWSetting 64;
BA_ "FlexKomSigStartPos" SG_ 625 FCWSetting 7;
BA_ "FlexKomSID" SG_ 625 FCWSetting 2333;
BA_ "GenSigTimeout_ORC" SG_ 625 FCWSetting 70;
BA_ "GenSigTimeout_IC" SG_ 625 FCWSetting 210;
BA_ "GenSigTimeout_CBC" SG_ 625 FCWSetting 210;
BA_ "FlexKomSigStartValue" SG_ 625 FCWSetting "000000FF000000FFh";
BA_ "GenSigCycleTime" SG_ 625 FCWSetting 20;
BA_ "GenSigSNA" SG_ 625 FCWBrkTeen "0h";
BA_ "FlexKomIsMotorola" SG_ 625 FCWBrkTeen 1;
BA_ "FlexKomComment" SG_ 625 FCWBrkTeen "DAS_A5 Packet";
BA_ "FlexKomSigName" SG_ 625 FCWBrkTeen "DAS_A5_PKT";
BA_ "FlexKomSigLaenge" SG_ 625 FCWBrkTeen 64;
BA_ "FlexKomSigStartPos" SG_ 625 FCWBrkTeen 7;
BA_ "FlexKomSID" SG_ 625 FCWBrkTeen 2333;
BA_ "GenSigTimeout_ORC" SG_ 625 FCWBrkTeen 70;
BA_ "GenSigTimeout_IC" SG_ 625 FCWBrkTeen 210;
BA_ "FlexKomSigStartValue" SG_ 625 FCWBrkTeen "000000FF000000FFh";
BA_ "GenSigCycleTime" SG_ 625 FCWBrkTeen 20;
BA_ "GenSigSNA" SG_ 625 CRC_DAS_A5 "FFh";
BA_ "FlexKomIsMotorola" SG_ 625 CRC_DAS_A5 1;
BA_ "FlexKomComment" SG_ 625 CRC_DAS_A5 "DAS_A5 Packet";
BA_ "FlexKomSigName" SG_ 625 CRC_DAS_A5 "DAS_A5_PKT";
BA_ "FlexKomSigLaenge" SG_ 625 CRC_DAS_A5 64;
BA_ "FlexKomSigStartPos" SG_ 625 CRC_DAS_A5 7;
BA_ "FlexKomSID" SG_ 625 CRC_DAS_A5 2333;
BA_ "GenSigStartValue" SG_ 625 CRC_DAS_A5 255;
BA_ "FlexKomSigStartValue" SG_ 625 CRC_DAS_A5 "000000FF000000FFh";
BA_ "GenSigCycleTime" SG_ 625 CRC_DAS_A5 20;
BA_ "GenMsgStartDelayTime" BO_ 624 40;
BA_ "GenMsgStartValue" BO_ 624 "0000000000000FFFh";
BA_ "GenMsgNrOfRepetitions" BO_ 624 2;
BA_ "GenMsgDelayTime" BO_ 624 20;
BA_ "GenMsgCycleTime" BO_ 624 1000;
BA_ "GenMsgSendType" BO_ 624 5;
BA_ "FlexKomComment" SG_ 624 R_R_Req_PE "Right rear passive entry requested; True = [1]";
BA_ "GenSigSNA" SG_ 624 R_R_Req_PE "0h";
BA_ "FlexKomIsMotorola" SG_ 624 R_R_Req_PE 1;
BA_ "FlexKomSigName" SG_ 624 R_R_Req_PE "R_R_Req_PE";
BA_ "FlexKomSigLaenge" SG_ 624 R_R_Req_PE 2;
BA_ "FlexKomSigStartPos" SG_ 624 R_R_Req_PE 21;
BA_ "FlexKomSID" SG_ 624 R_R_Req_PE 2416;
BA_ "FlexKomSigStartValue" SG_ 624 R_R_Req_PE "00h";
BA_ "GenSigCycleTime" SG_ 624 R_R_Req_PE 1000;
BA_ "GenSigSendType" SG_ 624 R_R_Req_PE 5;
BA_ "GenSigSNA" SG_ 624 PNC_ALM_ACT "0h";
BA_ "FlexKomIsMotorola" SG_ 624 PNC_ALM_ACT 1;
BA_ "FlexKomComment" SG_ 624 PNC_ALM_ACT "Panic alarm active; [1] = True";
BA_ "FlexKomSigName" SG_ 624 PNC_ALM_ACT "PNC_ALM_ACT";
BA_ "FlexKomSigLaenge" SG_ 624 PNC_ALM_ACT 1;
BA_ "FlexKomSigStartPos" SG_ 624 PNC_ALM_ACT 55;
BA_ "FlexKomSID" SG_ 624 PNC_ALM_ACT 756;
BA_ "FlexKomSigStartValue" SG_ 624 PNC_ALM_ACT "00h";
BA_ "GenSigCycleTime" SG_ 624 PNC_ALM_ACT 1000;
BA_ "GenSigSendType" SG_ 624 PNC_ALM_ACT 5;
BA_ "FlexKomComment" SG_ 624 L_R_Req_PE "Left rear passive entry requested; True = [1]";
BA_ "GenSigSNA" SG_ 624 L_R_Req_PE "0h";
BA_ "FlexKomIsMotorola" SG_ 624 L_R_Req_PE 1;
BA_ "FlexKomSigName" SG_ 624 L_R_Req_PE "L_R_Req_PE";
BA_ "FlexKomSigLaenge" SG_ 624 L_R_Req_PE 2;
BA_ "FlexKomSigStartPos" SG_ 624 L_R_Req_PE 19;
BA_ "FlexKomSID" SG_ 624 L_R_Req_PE 2415;
BA_ "FlexKomSigStartValue" SG_ 624 L_R_Req_PE "00h";
BA_ "GenSigCycleTime" SG_ 624 L_R_Req_PE 1000;
BA_ "GenSigSendType" SG_ 624 L_R_Req_PE 5;
BA_ "FlexKomComment" SG_ 624 Gate_Req_PE "Gate passive entry requested; True = [1]";
BA_ "GenSigSNA" SG_ 624 Gate_Req_PE "0h";
BA_ "FlexKomIsMotorola" SG_ 624 Gate_Req_PE 1;
BA_ "FlexKomSigName" SG_ 624 Gate_Req_PE "Gate_Req_PE";
BA_ "FlexKomSigLaenge" SG_ 624 Gate_Req_PE 2;
BA_ "FlexKomSigStartPos" SG_ 624 Gate_Req_PE 23;
BA_ "FlexKomSID" SG_ 624 Gate_Req_PE 2417;
BA_ "FlexKomSigStartValue" SG_ 624 Gate_Req_PE "00h";
BA_ "GenSigCycleTime" SG_ 624 Gate_Req_PE 1000;
BA_ "GenSigSendType" SG_ 624 Gate_Req_PE 5;
BA_ "GenSigSNA" SG_ 624 EngineOffTimer "FFFh";
BA_ "FlexKomIsMotorola" SG_ 624 EngineOffTimer 1;
BA_ "FlexKomComment" SG_ 624 EngineOffTimer "Engine off timer - engine off ignition NOT lock.";
BA_ "FlexKomSigName" SG_ 624 EngineOffTimer "EngineOffTimer";
BA_ "FlexKomSigLaenge" SG_ 624 EngineOffTimer 16;
BA_ "FlexKomSigStartPos" SG_ 624 EngineOffTimer 55;
BA_ "FlexKomSID" SG_ 624 EngineOffTimer 1906;
BA_ "GenSigStartValue" SG_ 624 EngineOffTimer 4095;
BA_ "FlexKomSigStartValue" SG_ 624 EngineOffTimer "0FFFh";
BA_ "GenSigCycleTime" SG_ 624 EngineOffTimer 1000;
BA_ "GenMsgStartValue" BO_ 608 "FF001400000000FFh";
BA_ "GenMsgNrOfRepetitions" BO_ 608 2;
BA_ "GenMsgDelayTime" BO_ 608 20;
BA_ "GenMsgCycleTime" BO_ 608 500;
BA_ "GenMsgSendType" BO_ 608 5;
BA_ "GenSigSNA" SG_ 608 RR_PTS_StopControlStsTeen "0h";
BA_ "FlexKomIsMotorola" SG_ 608 RR_PTS_StopControlStsTeen 1;
BA_ "FlexKomComment" SG_ 608 RR_PTS_StopControlStsTeen "PTS 2 message packet";
BA_ "FlexKomSigName" SG_ 608 RR_PTS_StopControlStsTeen "PTS_2_Pkt";
BA_ "FlexKomSigLaenge" SG_ 608 RR_PTS_StopControlStsTeen 64;
BA_ "FlexKomSigStartPos" SG_ 608 RR_PTS_StopControlStsTeen 7;
BA_ "FlexKomSID" SG_ 608 RR_PTS_StopControlStsTeen 1954;
BA_ "FlexKomSigStartValue" SG_ 608 RR_PTS_StopControlStsTeen "FF001400000000FFh";
BA_ "GenSigCycleTime" SG_ 608 RR_PTS_StopControlStsTeen 500;
BA_ "GenSigSendType" SG_ 608 RR_PTS_StopControlStsTeen 5;
BA_ "GenSigSNA" SG_ 608 RR_PTS_StopControlSts "0h";
BA_ "FlexKomIsMotorola" SG_ 608 RR_PTS_StopControlSts 1;
BA_ "FlexKomComment" SG_ 608 RR_PTS_StopControlSts "PTS 2 message packet";
BA_ "FlexKomSigName" SG_ 608 RR_PTS_StopControlSts "PTS_2_Pkt";
BA_ "FlexKomSigLaenge" SG_ 608 RR_PTS_StopControlSts 64;
BA_ "FlexKomSigStartPos" SG_ 608 RR_PTS_StopControlSts 7;
BA_ "FlexKomSID" SG_ 608 RR_PTS_StopControlSts 1954;
BA_ "FlexKomSigStartValue" SG_ 608 RR_PTS_StopControlSts "FF001400000000FFh";
BA_ "GenSigCycleTime" SG_ 608 RR_PTS_StopControlSts 500;
BA_ "GenSigSendType" SG_ 608 RR_PTS_StopControlSts 5;
BA_ "GenSigSNA" SG_ 608 RR_PTS_Dist "FFh";
BA_ "FlexKomIsMotorola" SG_ 608 RR_PTS_Dist 1;
BA_ "FlexKomComment" SG_ 608 RR_PTS_Dist "PTS 2 message packet";
BA_ "FlexKomSigName" SG_ 608 RR_PTS_Dist "PTS_2_Pkt";
BA_ "FlexKomSigLaenge" SG_ 608 RR_PTS_Dist 64;
BA_ "FlexKomSigStartPos" SG_ 608 RR_PTS_Dist 7;
BA_ "FlexKomSID" SG_ 608 RR_PTS_Dist 1954;
BA_ "GenSigStartValue" SG_ 608 RR_PTS_Dist 255;
BA_ "FlexKomSigStartValue" SG_ 608 RR_PTS_Dist "FF001400000000FFh";
BA_ "GenSigCycleTime" SG_ 608 RR_PTS_Dist 500;
BA_ "GenSigSendType" SG_ 608 RR_PTS_Dist 5;
BA_ "GenSigSNA" SG_ 608 RR_PTS_Brk_RqSts "0h";
BA_ "FlexKomIsMotorola" SG_ 608 RR_PTS_Brk_RqSts 1;
BA_ "FlexKomComment" SG_ 608 RR_PTS_Brk_RqSts "PTS 2 message packet";
BA_ "FlexKomSigName" SG_ 608 RR_PTS_Brk_RqSts "PTS_2_Pkt";
BA_ "FlexKomSigLaenge" SG_ 608 RR_PTS_Brk_RqSts 64;
BA_ "FlexKomSigStartPos" SG_ 608 RR_PTS_Brk_RqSts 7;
BA_ "FlexKomSID" SG_ 608 RR_PTS_Brk_RqSts 1954;
BA_ "FlexKomSigStartValue" SG_ 608 RR_PTS_Brk_RqSts "FF001400000000FFh";
BA_ "GenSigCycleTime" SG_ 608 RR_PTS_Brk_RqSts 500;
BA_ "GenSigSendType" SG_ 608 RR_PTS_Brk_RqSts 5;
BA_ "GenSigSNA" SG_ 608 PTS_RR_VOL_TeenKey "3h";
BA_ "FlexKomIsMotorola" SG_ 608 PTS_RR_VOL_TeenKey 1;
BA_ "FlexKomComment" SG_ 608 PTS_RR_VOL_TeenKey "PTS 2 message packet";
BA_ "FlexKomSigName" SG_ 608 PTS_RR_VOL_TeenKey "PTS_2_Pkt";
BA_ "FlexKomSigLaenge" SG_ 608 PTS_RR_VOL_TeenKey 64;
BA_ "FlexKomSigStartPos" SG_ 608 PTS_RR_VOL_TeenKey 7;
BA_ "FlexKomSID" SG_ 608 PTS_RR_VOL_TeenKey 1954;
BA_ "GenSigTimeout_CBC" SG_ 608 PTS_RR_VOL_TeenKey 5250;
BA_ "GenSigStartValue" SG_ 608 PTS_RR_VOL_TeenKey 1;
BA_ "FlexKomSigStartValue" SG_ 608 PTS_RR_VOL_TeenKey "FF001400000000FFh";
BA_ "GenSigCycleTime" SG_ 608 PTS_RR_VOL_TeenKey 500;
BA_ "GenSigSendType" SG_ 608 PTS_RR_VOL_TeenKey 5;
BA_ "GenSigSNA" SG_ 608 PTS_RR_TEMP_NA "0h";
BA_ "FlexKomIsMotorola" SG_ 608 PTS_RR_TEMP_NA 1;
BA_ "FlexKomComment" SG_ 608 PTS_RR_TEMP_NA "PTS 2 message packet";
BA_ "FlexKomSigName" SG_ 608 PTS_RR_TEMP_NA "PTS_2_Pkt";
BA_ "FlexKomSigLaenge" SG_ 608 PTS_RR_TEMP_NA 64;
BA_ "FlexKomSigStartPos" SG_ 608 PTS_RR_TEMP_NA 7;
BA_ "FlexKomSID" SG_ 608 PTS_RR_TEMP_NA 1954;
BA_ "GenSigTimeout_IC" SG_ 608 PTS_RR_TEMP_NA 5250;
BA_ "FlexKomSigStartValue" SG_ 608 PTS_RR_TEMP_NA "FF001400000000FFh";
BA_ "GenSigCycleTime" SG_ 608 PTS_RR_TEMP_NA 500;
BA_ "GenSigSendType" SG_ 608 PTS_RR_TEMP_NA 5;
BA_ "GenSigSNA" SG_ 608 PTS_PopUpRqst "FFh";
BA_ "FlexKomIsMotorola" SG_ 608 PTS_PopUpRqst 1;
BA_ "FlexKomComment" SG_ 608 PTS_PopUpRqst "PTS 2 message packet";
BA_ "FlexKomSigName" SG_ 608 PTS_PopUpRqst "PTS_2_Pkt";
BA_ "FlexKomSigLaenge" SG_ 608 PTS_PopUpRqst 64;
BA_ "FlexKomSigStartPos" SG_ 608 PTS_PopUpRqst 7;
BA_ "FlexKomSID" SG_ 608 PTS_PopUpRqst 1954;
BA_ "GenSigTimeout_IC" SG_ 608 PTS_PopUpRqst 5250;
BA_ "FlexKomSigStartValue" SG_ 608 PTS_PopUpRqst "FF001400000000FFh";
BA_ "GenSigCycleTime" SG_ 608 PTS_PopUpRqst 500;
BA_ "GenSigSendType" SG_ 608 PTS_PopUpRqst 5;
BA_ "GenSigSNA" SG_ 608 PTS_Off_Status "0h";
BA_ "FlexKomIsMotorola" SG_ 608 PTS_Off_Status 1;
BA_ "FlexKomComment" SG_ 608 PTS_Off_Status "PTS 2 message packet";
BA_ "FlexKomSigName" SG_ 608 PTS_Off_Status "PTS_2_Pkt";
BA_ "FlexKomSigLaenge" SG_ 608 PTS_Off_Status 64;
BA_ "FlexKomSigStartPos" SG_ 608 PTS_Off_Status 7;
BA_ "FlexKomSID" SG_ 608 PTS_Off_Status 1954;
BA_ "GenSigTimeout_IC" SG_ 608 PTS_Off_Status 5250;
BA_ "FlexKomSigStartValue" SG_ 608 PTS_Off_Status "FF001400000000FFh";
BA_ "GenSigCycleTime" SG_ 608 PTS_Off_Status 500;
BA_ "GenSigSendType" SG_ 608 PTS_Off_Status 5;
BA_ "GenSigSNA" SG_ 608 PTS_FT_VOL_TeenKey "3h";
BA_ "FlexKomIsMotorola" SG_ 608 PTS_FT_VOL_TeenKey 1;
BA_ "FlexKomComment" SG_ 608 PTS_FT_VOL_TeenKey "PTS 2 message packet";
BA_ "FlexKomSigName" SG_ 608 PTS_FT_VOL_TeenKey "PTS_2_Pkt";
BA_ "FlexKomSigLaenge" SG_ 608 PTS_FT_VOL_TeenKey 64;
BA_ "FlexKomSigStartPos" SG_ 608 PTS_FT_VOL_TeenKey 7;
BA_ "FlexKomSID" SG_ 608 PTS_FT_VOL_TeenKey 1954;
BA_ "GenSigTimeout_CBC" SG_ 608 PTS_FT_VOL_TeenKey 5250;
BA_ "GenSigStartValue" SG_ 608 PTS_FT_VOL_TeenKey 1;
BA_ "FlexKomSigStartValue" SG_ 608 PTS_FT_VOL_TeenKey "FF001400000000FFh";
BA_ "GenSigCycleTime" SG_ 608 PTS_FT_VOL_TeenKey 500;
BA_ "GenSigSendType" SG_ 608 PTS_FT_VOL_TeenKey 5;
BA_ "GenSigSNA" SG_ 608 PTS_FT_TEMP_NA "0h";
BA_ "FlexKomIsMotorola" SG_ 608 PTS_FT_TEMP_NA 1;
BA_ "FlexKomComment" SG_ 608 PTS_FT_TEMP_NA "PTS 2 message packet";
BA_ "FlexKomSigName" SG_ 608 PTS_FT_TEMP_NA "PTS_2_Pkt";
BA_ "FlexKomSigLaenge" SG_ 608 PTS_FT_TEMP_NA 64;
BA_ "FlexKomSigStartPos" SG_ 608 PTS_FT_TEMP_NA 7;
BA_ "FlexKomSID" SG_ 608 PTS_FT_TEMP_NA 1954;
BA_ "GenSigTimeout_IC" SG_ 608 PTS_FT_TEMP_NA 5250;
BA_ "FlexKomSigStartValue" SG_ 608 PTS_FT_TEMP_NA "FF001400000000FFh";
BA_ "GenSigCycleTime" SG_ 608 PTS_FT_TEMP_NA 500;
BA_ "GenSigSendType" SG_ 608 PTS_FT_TEMP_NA 5;
BA_ "GenSigSNA" SG_ 608 PTS_CFG_STAT_TeenKey "3h";
BA_ "FlexKomIsMotorola" SG_ 608 PTS_CFG_STAT_TeenKey 1;
BA_ "FlexKomComment" SG_ 608 PTS_CFG_STAT_TeenKey "PTS 2 message packet";
BA_ "FlexKomSigName" SG_ 608 PTS_CFG_STAT_TeenKey "PTS_2_Pkt";
BA_ "FlexKomSigLaenge" SG_ 608 PTS_CFG_STAT_TeenKey 64;
BA_ "FlexKomSigStartPos" SG_ 608 PTS_CFG_STAT_TeenKey 7;
BA_ "FlexKomSID" SG_ 608 PTS_CFG_STAT_TeenKey 1954;
BA_ "GenSigTimeout_CBC" SG_ 608 PTS_CFG_STAT_TeenKey 5250;
BA_ "FlexKomSigStartValue" SG_ 608 PTS_CFG_STAT_TeenKey "FF001400000000FFh";
BA_ "GenSigCycleTime" SG_ 608 PTS_CFG_STAT_TeenKey 500;
BA_ "GenSigSendType" SG_ 608 PTS_CFG_STAT_TeenKey 5;
BA_ "GenSigSNA" SG_ 608 MC_PTS_2 "0h";
BA_ "FlexKomIsMotorola" SG_ 608 MC_PTS_2 1;
BA_ "FlexKomComment" SG_ 608 MC_PTS_2 "PTS 2 message packet";
BA_ "FlexKomSigName" SG_ 608 MC_PTS_2 "PTS_2_Pkt";
BA_ "FlexKomSigLaenge" SG_ 608 MC_PTS_2 64;
BA_ "FlexKomSigStartPos" SG_ 608 MC_PTS_2 7;
BA_ "FlexKomSID" SG_ 608 MC_PTS_2 1954;
BA_ "FlexKomSigStartValue" SG_ 608 MC_PTS_2 "FF001400000000FFh";
BA_ "GenSigCycleTime" SG_ 608 MC_PTS_2 500;
BA_ "GenSigSendType" SG_ 608 MC_PTS_2 5;
BA_ "GenSigSNA" SG_ 608 CRC_PTS_2 "FFh";
BA_ "FlexKomIsMotorola" SG_ 608 CRC_PTS_2 1;
BA_ "FlexKomComment" SG_ 608 CRC_PTS_2 "PTS 2 message packet";
BA_ "FlexKomSigName" SG_ 608 CRC_PTS_2 "PTS_2_Pkt";
BA_ "FlexKomSigLaenge" SG_ 608 CRC_PTS_2 64;
BA_ "FlexKomSigStartPos" SG_ 608 CRC_PTS_2 7;
BA_ "FlexKomSID" SG_ 608 CRC_PTS_2 1954;
BA_ "GenSigStartValue" SG_ 608 CRC_PTS_2 255;
BA_ "FlexKomSigStartValue" SG_ 608 CRC_PTS_2 "FF001400000000FFh";
BA_ "GenSigCycleTime" SG_ 608 CRC_PTS_2 500;
BA_ "GenSigSendType" SG_ 608 CRC_PTS_2 5;
BA_ "GenMsgStartDelayTime" BO_ 584 70;
BA_ "GenMsgStartValue" BO_ 584 "0000FFFFFF03FFFFh";
BA_ "GenMsgNrOfRepetitions" BO_ 584 2;
BA_ "GenMsgDelayTime" BO_ 584 20;
BA_ "GenMsgCycleTime" BO_ 584 500;
BA_ "GenMsgSendType" BO_ 584 5;
BA_ "GenSigSNA" SG_ 584 PN14_LS_Actv "0h";
BA_ "FlexKomIsMotorola" SG_ 584 PN14_LS_Actv 1;
BA_ "FlexKomComment" SG_ 584 PN14_LS_Actv "14 V powernet limp-home cutoff state";
BA_ "FlexKomSigName" SG_ 584 PN14_LS_Actv "PN14_LHC_Stat";
BA_ "FlexKomSigLaenge" SG_ 584 PN14_LS_Actv 64;
BA_ "FlexKomSigStartPos" SG_ 584 PN14_LS_Actv 7;
BA_ "FlexKomSID" SG_ 584 PN14_LS_Actv 1092;
BA_ "GenSigTimeout_IC" SG_ 584 PN14_LS_Actv 5250;
BA_ "FlexKomSigStartValue" SG_ 584 PN14_LS_Actv "0000FFFFFF03FFFFh";
BA_ "GenSigCycleTime" SG_ 584 PN14_LS_Actv 500;
BA_ "GenSigSendType" SG_ 584 PN14_LS_Actv 5;
BA_ "GenSigSNA" SG_ 584 IBS_SOH_Q_Accuracy "3h";
BA_ "FlexKomIsMotorola" SG_ 584 IBS_SOH_Q_Accuracy 1;
BA_ "FlexKomComment" SG_ 584 IBS_SOH_Q_Accuracy "14 V powernet limp-home cutoff state";
BA_ "FlexKomSigName" SG_ 584 IBS_SOH_Q_Accuracy "PN14_LHC_Stat";
BA_ "FlexKomSigLaenge" SG_ 584 IBS_SOH_Q_Accuracy 64;
BA_ "FlexKomSigStartPos" SG_ 584 IBS_SOH_Q_Accuracy 7;
BA_ "FlexKomSID" SG_ 584 IBS_SOH_Q_Accuracy 1092;
BA_ "GenSigStartValue" SG_ 584 IBS_SOH_Q_Accuracy 3;
BA_ "FlexKomSigStartValue" SG_ 584 IBS_SOH_Q_Accuracy "0000FFFFFF03FFFFh";
BA_ "GenSigCycleTime" SG_ 584 IBS_SOH_Q_Accuracy 500;
BA_ "GenSigSendType" SG_ 584 IBS_SOH_Q_Accuracy 5;
BA_ "GenSigSNA" SG_ 584 IBS_SOH_Q "FFh";
BA_ "FlexKomIsMotorola" SG_ 584 IBS_SOH_Q 1;
BA_ "FlexKomComment" SG_ 584 IBS_SOH_Q "14 V powernet limp-home cutoff state";
BA_ "FlexKomSigName" SG_ 584 IBS_SOH_Q "PN14_LHC_Stat";
BA_ "FlexKomSigLaenge" SG_ 584 IBS_SOH_Q 64;
BA_ "FlexKomSigStartPos" SG_ 584 IBS_SOH_Q 7;
BA_ "FlexKomSID" SG_ 584 IBS_SOH_Q 1092;
BA_ "GenSigStartValue" SG_ 584 IBS_SOH_Q 255;
BA_ "FlexKomSigStartValue" SG_ 584 IBS_SOH_Q "0000FFFFFF03FFFFh";
BA_ "GenSigCycleTime" SG_ 584 IBS_SOH_Q 500;
BA_ "GenSigSendType" SG_ 584 IBS_SOH_Q 5;
BA_ "GenSigSNA" SG_ 584 IBS_SOF_t_Accuracy "3h";
BA_ "FlexKomIsMotorola" SG_ 584 IBS_SOF_t_Accuracy 1;
BA_ "FlexKomComment" SG_ 584 IBS_SOF_t_Accuracy "14 V powernet limp-home cutoff state";
BA_ "FlexKomSigName" SG_ 584 IBS_SOF_t_Accuracy "PN14_LHC_Stat";
BA_ "FlexKomSigLaenge" SG_ 584 IBS_SOF_t_Accuracy 64;
BA_ "FlexKomSigStartPos" SG_ 584 IBS_SOF_t_Accuracy 7;
BA_ "FlexKomSID" SG_ 584 IBS_SOF_t_Accuracy 1092;
BA_ "GenSigStartValue" SG_ 584 IBS_SOF_t_Accuracy 3;
BA_ "FlexKomSigStartValue" SG_ 584 IBS_SOF_t_Accuracy "0000FFFFFF03FFFFh";
BA_ "GenSigCycleTime" SG_ 584 IBS_SOF_t_Accuracy 500;
BA_ "GenSigSendType" SG_ 584 IBS_SOF_t_Accuracy 5;
BA_ "GenSigSNA" SG_ 584 IBS_SOF_t "3FFh";
BA_ "FlexKomIsMotorola" SG_ 584 IBS_SOF_t 1;
BA_ "FlexKomComment" SG_ 584 IBS_SOF_t "14 V powernet limp-home cutoff state";
BA_ "FlexKomSigName" SG_ 584 IBS_SOF_t "PN14_LHC_Stat";
BA_ "FlexKomSigLaenge" SG_ 584 IBS_SOF_t 64;
BA_ "FlexKomSigStartPos" SG_ 584 IBS_SOF_t 7;
BA_ "FlexKomSID" SG_ 584 IBS_SOF_t 1092;
BA_ "GenSigStartValue" SG_ 584 IBS_SOF_t 1023;
BA_ "FlexKomSigStartValue" SG_ 584 IBS_SOF_t "0000FFFFFF03FFFFh";
BA_ "GenSigCycleTime" SG_ 584 IBS_SOF_t 500;
BA_ "GenSigSendType" SG_ 584 IBS_SOF_t 5;
BA_ "GenSigSNA" SG_ 584 IBS_SOF_Q_Accuracy "3h";
BA_ "FlexKomIsMotorola" SG_ 584 IBS_SOF_Q_Accuracy 1;
BA_ "FlexKomComment" SG_ 584 IBS_SOF_Q_Accuracy "14 V powernet limp-home cutoff state";
BA_ "FlexKomSigName" SG_ 584 IBS_SOF_Q_Accuracy "PN14_LHC_Stat";
BA_ "FlexKomSigLaenge" SG_ 584 IBS_SOF_Q_Accuracy 64;
BA_ "FlexKomSigStartPos" SG_ 584 IBS_SOF_Q_Accuracy 7;
BA_ "FlexKomSID" SG_ 584 IBS_SOF_Q_Accuracy 1092;
BA_ "GenSigStartValue" SG_ 584 IBS_SOF_Q_Accuracy 3;
BA_ "FlexKomSigStartValue" SG_ 584 IBS_SOF_Q_Accuracy "0000FFFFFF03FFFFh";
BA_ "GenSigCycleTime" SG_ 584 IBS_SOF_Q_Accuracy 500;
BA_ "GenSigSendType" SG_ 584 IBS_SOF_Q_Accuracy 5;
BA_ "GenSigSNA" SG_ 584 IBS_SOF_Q "FFh";
BA_ "FlexKomIsMotorola" SG_ 584 IBS_SOF_Q 1;
BA_ "FlexKomComment" SG_ 584 IBS_SOF_Q "14 V powernet limp-home cutoff state";
BA_ "FlexKomSigName" SG_ 584 IBS_SOF_Q "PN14_LHC_Stat";
BA_ "FlexKomSigLaenge" SG_ 584 IBS_SOF_Q 64;
BA_ "FlexKomSigStartPos" SG_ 584 IBS_SOF_Q 7;
BA_ "FlexKomSID" SG_ 584 IBS_SOF_Q 1092;
BA_ "GenSigStartValue" SG_ 584 IBS_SOF_Q 255;
BA_ "FlexKomSigStartValue" SG_ 584 IBS_SOF_Q "0000FFFFFF03FFFFh";
BA_ "GenSigCycleTime" SG_ 584 IBS_SOF_Q 500;
BA_ "GenSigSendType" SG_ 584 IBS_SOF_Q 5;
BA_ "GenSigSNA" SG_ 584 IBS_SOC_Accuracy "3h";
BA_ "FlexKomIsMotorola" SG_ 584 IBS_SOC_Accuracy 1;
BA_ "FlexKomComment" SG_ 584 IBS_SOC_Accuracy "14 V powernet limp-home cutoff state";
BA_ "FlexKomSigName" SG_ 584 IBS_SOC_Accuracy "PN14_LHC_Stat";
BA_ "FlexKomSigLaenge" SG_ 584 IBS_SOC_Accuracy 64;
BA_ "FlexKomSigStartPos" SG_ 584 IBS_SOC_Accuracy 7;
BA_ "FlexKomSID" SG_ 584 IBS_SOC_Accuracy 1092;
BA_ "GenSigStartValue" SG_ 584 IBS_SOC_Accuracy 3;
BA_ "FlexKomSigStartValue" SG_ 584 IBS_SOC_Accuracy "0000FFFFFF03FFFFh";
BA_ "GenSigCycleTime" SG_ 584 IBS_SOC_Accuracy 500;
BA_ "GenSigSendType" SG_ 584 IBS_SOC_Accuracy 5;
BA_ "GenSigSNA" SG_ 584 IBS_SOC "FFh";
BA_ "FlexKomIsMotorola" SG_ 584 IBS_SOC 1;
BA_ "FlexKomComment" SG_ 584 IBS_SOC "14 V powernet limp-home cutoff state";
BA_ "FlexKomSigName" SG_ 584 IBS_SOC "PN14_LHC_Stat";
BA_ "FlexKomSigLaenge" SG_ 584 IBS_SOC 64;
BA_ "FlexKomSigStartPos" SG_ 584 IBS_SOC 7;
BA_ "FlexKomSID" SG_ 584 IBS_SOC 1092;
BA_ "GenSigTimeout_ORC" SG_ 584 IBS_SOC 1750;
BA_ "GenSigStartValue" SG_ 584 IBS_SOC 255;
BA_ "FlexKomSigStartValue" SG_ 584 IBS_SOC "0000FFFFFF03FFFFh";
BA_ "GenSigCycleTime" SG_ 584 IBS_SOC 500;
BA_ "GenSigSendType" SG_ 584 IBS_SOC 5;
BA_ "GenSigSNA" SG_ 584 Batt_ST_Crit "0h";
BA_ "FlexKomIsMotorola" SG_ 584 Batt_ST_Crit 1;
BA_ "FlexKomComment" SG_ 584 Batt_ST_Crit "14 V powernet limp-home cutoff state";
BA_ "FlexKomSigName" SG_ 584 Batt_ST_Crit "PN14_LHC_Stat";
BA_ "FlexKomSigLaenge" SG_ 584 Batt_ST_Crit 64;
BA_ "FlexKomSigStartPos" SG_ 584 Batt_ST_Crit 7;
BA_ "FlexKomSID" SG_ 584 Batt_ST_Crit 1092;
BA_ "FlexKomSigStartValue" SG_ 584 Batt_ST_Crit "0000FFFFFF03FFFFh";
BA_ "GenSigCycleTime" SG_ 584 Batt_ST_Crit 500;
BA_ "GenSigSendType" SG_ 584 Batt_ST_Crit 5;
BA_ "GenMsgStartValue" BO_ 571 "0000FFh";
BA_ "GenMsgNrOfRepetitions" BO_ 571 2;
BA_ "GenMsgDelayTime" BO_ 571 20;
BA_ "GenMsgSendType" BO_ 571 1;
BA_ "GenSigSNA" SG_ 571 ResumeSwitch "0h";
BA_ "FlexKomIsMotorola" SG_ 571 ResumeSwitch 1;
BA_ "FlexKomComment" SG_ 571 ResumeSwitch "Cruise Control Lever Status";
BA_ "FlexKomSigName" SG_ 571 ResumeSwitch "CrsCtrlLvrSts";
BA_ "FlexKomSigLaenge" SG_ 571 ResumeSwitch 24;
BA_ "FlexKomSigStartPos" SG_ 571 ResumeSwitch 7;
BA_ "FlexKomSID" SG_ 571 ResumeSwitch 1848;
BA_ "FlexKomSigStartValue" SG_ 571 ResumeSwitch "0000FFh";
BA_ "GenSigSendType" SG_ 571 ResumeSwitch 1;
BA_ "GenSigSNA" SG_ 571 MC_CSWC_1 "0h";
BA_ "FlexKomIsMotorola" SG_ 571 MC_CSWC_1 1;
BA_ "FlexKomComment" SG_ 571 MC_CSWC_1 "Cruise Control Lever Status";
BA_ "FlexKomSigName" SG_ 571 MC_CSWC_1 "CrsCtrlLvrSts";
BA_ "FlexKomSigLaenge" SG_ 571 MC_CSWC_1 24;
BA_ "FlexKomSigStartPos" SG_ 571 MC_CSWC_1 7;
BA_ "FlexKomSID" SG_ 571 MC_CSWC_1 1848;
BA_ "FlexKomSigStartValue" SG_ 571 MC_CSWC_1 "0000FFh";
BA_ "GenSigSendType" SG_ 571 MC_CSWC_1 1;
BA_ "GenSigSNA" SG_ 571 DeceleratorSts "0h";
BA_ "FlexKomIsMotorola" SG_ 571 DeceleratorSts 1;
BA_ "FlexKomComment" SG_ 571 DeceleratorSts "Cruise Control Lever Status";
BA_ "FlexKomSigName" SG_ 571 DeceleratorSts "CrsCtrlLvrSts";
BA_ "FlexKomSigLaenge" SG_ 571 DeceleratorSts 24;
BA_ "FlexKomSigStartPos" SG_ 571 DeceleratorSts 7;
BA_ "FlexKomSID" SG_ 571 DeceleratorSts 1848;
BA_ "FlexKomSigStartValue" SG_ 571 DeceleratorSts "0000FFh";
BA_ "GenSigSendType" SG_ 571 DeceleratorSts 1;
BA_ "GenSigSNA" SG_ 571 CrusCnclSwitch "0h";
BA_ "FlexKomIsMotorola" SG_ 571 CrusCnclSwitch 1;
BA_ "FlexKomComment" SG_ 571 CrusCnclSwitch "Cruise Control Lever Status";
BA_ "FlexKomSigName" SG_ 571 CrusCnclSwitch "CrsCtrlLvrSts";
BA_ "FlexKomSigLaenge" SG_ 571 CrusCnclSwitch 24;
BA_ "FlexKomSigStartPos" SG_ 571 CrusCnclSwitch 7;
BA_ "FlexKomSID" SG_ 571 CrusCnclSwitch 1848;
BA_ "FlexKomSigStartValue" SG_ 571 CrusCnclSwitch "0000FFh";
BA_ "GenSigSendType" SG_ 571 CrusCnclSwitch 1;
BA_ "GenSigSNA" SG_ 571 CruiseControlOnOffSts "0h";
BA_ "FlexKomIsMotorola" SG_ 571 CruiseControlOnOffSts 1;
BA_ "FlexKomComment" SG_ 571 CruiseControlOnOffSts "Cruise Control Lever Status";
BA_ "FlexKomSigName" SG_ 571 CruiseControlOnOffSts "CrsCtrlLvrSts";
BA_ "FlexKomSigLaenge" SG_ 571 CruiseControlOnOffSts 24;
BA_ "FlexKomSigStartPos" SG_ 571 CruiseControlOnOffSts 7;
BA_ "FlexKomSID" SG_ 571 CruiseControlOnOffSts 1848;
BA_ "FlexKomSigStartValue" SG_ 571 CruiseControlOnOffSts "0000FFh";
BA_ "GenSigSendType" SG_ 571 CruiseControlOnOffSts 1;
BA_ "GenSigSNA" SG_ 571 CruiseControlFailSts "0h";
BA_ "FlexKomIsMotorola" SG_ 571 CruiseControlFailSts 1;
BA_ "FlexKomComment" SG_ 571 CruiseControlFailSts "Cruise Control Lever Status";
BA_ "FlexKomSigName" SG_ 571 CruiseControlFailSts "CrsCtrlLvrSts";
BA_ "FlexKomSigLaenge" SG_ 571 CruiseControlFailSts 24;
BA_ "FlexKomSigStartPos" SG_ 571 CruiseControlFailSts 7;
BA_ "FlexKomSID" SG_ 571 CruiseControlFailSts 1848;
BA_ "FlexKomSigStartValue" SG_ 571 CruiseControlFailSts "0000FFh";
BA_ "GenSigSendType" SG_ 571 CruiseControlFailSts 1;
BA_ "GenSigSNA" SG_ 571 CRC_CSWC_1 "FFh";
BA_ "FlexKomIsMotorola" SG_ 571 CRC_CSWC_1 1;
BA_ "FlexKomComment" SG_ 571 CRC_CSWC_1 "Cruise Control Lever Status";
BA_ "FlexKomSigName" SG_ 571 CRC_CSWC_1 "CrsCtrlLvrSts";
BA_ "FlexKomSigLaenge" SG_ 571 CRC_CSWC_1 24;
BA_ "FlexKomSigStartPos" SG_ 571 CRC_CSWC_1 7;
BA_ "FlexKomSID" SG_ 571 CRC_CSWC_1 1848;
BA_ "GenSigStartValue" SG_ 571 CRC_CSWC_1 255;
BA_ "FlexKomSigStartValue" SG_ 571 CRC_CSWC_1 "0000FFh";
BA_ "GenSigSendType" SG_ 571 CRC_CSWC_1 1;
BA_ "GenSigSNA" SG_ 571 AcceleratorSts "0h";
BA_ "FlexKomIsMotorola" SG_ 571 AcceleratorSts 1;
BA_ "FlexKomComment" SG_ 571 AcceleratorSts "Cruise Control Lever Status";
BA_ "FlexKomSigName" SG_ 571 AcceleratorSts "CrsCtrlLvrSts";
BA_ "FlexKomSigLaenge" SG_ 571 AcceleratorSts 24;
BA_ "FlexKomSigStartPos" SG_ 571 AcceleratorSts 7;
BA_ "FlexKomSID" SG_ 571 AcceleratorSts 1848;
BA_ "FlexKomSigStartValue" SG_ 571 AcceleratorSts "0000FFh";
BA_ "GenSigSendType" SG_ 571 AcceleratorSts 1;
BA_ "GenSigSNA" SG_ 571 ACC_On "0h";
BA_ "FlexKomIsMotorola" SG_ 571 ACC_On 1;
BA_ "FlexKomComment" SG_ 571 ACC_On "Cruise Control Lever Status";
BA_ "FlexKomSigName" SG_ 571 ACC_On "CrsCtrlLvrSts";
BA_ "FlexKomSigLaenge" SG_ 571 ACC_On 24;
BA_ "FlexKomSigStartPos" SG_ 571 ACC_On 7;
BA_ "FlexKomSID" SG_ 571 ACC_On 1848;
BA_ "FlexKomSigStartValue" SG_ 571 ACC_On "0000FFh";
BA_ "GenSigSendType" SG_ 571 ACC_On 1;
BA_ "GenSigSNA" SG_ 571 ACC_DistSwInc "0h";
BA_ "FlexKomIsMotorola" SG_ 571 ACC_DistSwInc 1;
BA_ "FlexKomComment" SG_ 571 ACC_DistSwInc "Cruise Control Lever Status";
BA_ "FlexKomSigName" SG_ 571 ACC_DistSwInc "CrsCtrlLvrSts";
BA_ "FlexKomSigLaenge" SG_ 571 ACC_DistSwInc 24;
BA_ "FlexKomSigStartPos" SG_ 571 ACC_DistSwInc 7;
BA_ "FlexKomSID" SG_ 571 ACC_DistSwInc 1848;
BA_ "FlexKomSigStartValue" SG_ 571 ACC_DistSwInc "0000FFh";
BA_ "GenSigSendType" SG_ 571 ACC_DistSwInc 1;
BA_ "GenSigSNA" SG_ 571 ACC_DistSwDec "0h";
BA_ "FlexKomIsMotorola" SG_ 571 ACC_DistSwDec 1;
BA_ "FlexKomComment" SG_ 571 ACC_DistSwDec "Cruise Control Lever Status";
BA_ "FlexKomSigName" SG_ 571 ACC_DistSwDec "CrsCtrlLvrSts";
BA_ "FlexKomSigLaenge" SG_ 571 ACC_DistSwDec 24;
BA_ "FlexKomSigStartPos" SG_ 571 ACC_DistSwDec 7;
BA_ "FlexKomSID" SG_ 571 ACC_DistSwDec 1848;
BA_ "FlexKomSigStartValue" SG_ 571 ACC_DistSwDec "0000FFh";
BA_ "GenSigSendType" SG_ 571 ACC_DistSwDec 1;
BA_ "GenMsgStartDelayTime" BO_ 564 10;
BA_ "GenMsgStartValue" BO_ 564 "FF030CFFh";
BA_ "GenMsgNrOfRepetitions" BO_ 564 2;
BA_ "GenMsgDelayTime" BO_ 564 20;
BA_ "GenMsgCycleTime" BO_ 564 100;
BA_ "GenSigSNA" SG_ 564 IBS_SOF_V1 "FFh";
BA_ "FlexKomIsMotorola" SG_ 564 IBS_SOF_V1 1;
BA_ "FlexKomComment" SG_ 564 IBS_SOF_V1 "IBS Battery Information additional";
BA_ "FlexKomSigName" SG_ 564 IBS_SOF_V1 "PN14_IBS_DATA_2";
BA_ "FlexKomSigLaenge" SG_ 564 IBS_SOF_V1 32;
BA_ "FlexKomSigStartPos" SG_ 564 IBS_SOF_V1 7;
BA_ "FlexKomSID" SG_ 564 IBS_SOF_V1 1405;
BA_ "GenSigStartValue" SG_ 564 IBS_SOF_V1 255;
BA_ "FlexKomSigStartValue" SG_ 564 IBS_SOF_V1 "FF0300FFh";
BA_ "GenSigCycleTime" SG_ 564 IBS_SOF_V1 100;
BA_ "GenSigSNA" SG_ 564 IBS_SOF_V_Accuracy "3h";
BA_ "FlexKomIsMotorola" SG_ 564 IBS_SOF_V_Accuracy 1;
BA_ "FlexKomComment" SG_ 564 IBS_SOF_V_Accuracy "IBS Battery Information additional";
BA_ "FlexKomSigName" SG_ 564 IBS_SOF_V_Accuracy "PN14_IBS_DATA_2";
BA_ "FlexKomSigLaenge" SG_ 564 IBS_SOF_V_Accuracy 32;
BA_ "FlexKomSigStartPos" SG_ 564 IBS_SOF_V_Accuracy 7;
BA_ "FlexKomSID" SG_ 564 IBS_SOF_V_Accuracy 1405;
BA_ "GenSigStartValue" SG_ 564 IBS_SOF_V_Accuracy 3;
BA_ "FlexKomSigStartValue" SG_ 564 IBS_SOF_V_Accuracy "FF0300FFh";
BA_ "GenSigCycleTime" SG_ 564 IBS_SOF_V_Accuracy 100;
BA_ "GenSigSNA" SG_ 564 IBS_SOF_V "FFh";
BA_ "FlexKomIsMotorola" SG_ 564 IBS_SOF_V 1;
BA_ "FlexKomComment" SG_ 564 IBS_SOF_V "IBS Battery Information additional";
BA_ "FlexKomSigName" SG_ 564 IBS_SOF_V "PN14_IBS_DATA_2";
BA_ "FlexKomSigLaenge" SG_ 564 IBS_SOF_V 32;
BA_ "FlexKomSigStartPos" SG_ 564 IBS_SOF_V 7;
BA_ "FlexKomSID" SG_ 564 IBS_SOF_V 1405;
BA_ "GenSigStartValue" SG_ 564 IBS_SOF_V 255;
BA_ "FlexKomSigStartValue" SG_ 564 IBS_SOF_V "FF0300FFh";
BA_ "GenSigCycleTime" SG_ 564 IBS_SOF_V 100;
BA_ "GenSigSNA" SG_ 564 IBS_Error_NVM "0h";
BA_ "FlexKomIsMotorola" SG_ 564 IBS_Error_NVM 1;
BA_ "FlexKomComment" SG_ 564 IBS_Error_NVM "IBS Battery Information additional";
BA_ "FlexKomSigName" SG_ 564 IBS_Error_NVM "PN14_IBS_DATA_2";
BA_ "FlexKomSigLaenge" SG_ 564 IBS_Error_NVM 32;
BA_ "FlexKomSigStartPos" SG_ 564 IBS_Error_NVM 7;
BA_ "FlexKomSID" SG_ 564 IBS_Error_NVM 1405;
BA_ "FlexKomSigStartValue" SG_ 564 IBS_Error_NVM "FF0300FFh";
BA_ "GenSigCycleTime" SG_ 564 IBS_Error_NVM 100;
BA_ "GenSigSNA" SG_ 564 IBS_Error_Ident "0h";
BA_ "FlexKomIsMotorola" SG_ 564 IBS_Error_Ident 1;
BA_ "FlexKomComment" SG_ 564 IBS_Error_Ident "IBS Battery Information additional";
BA_ "FlexKomSigName" SG_ 564 IBS_Error_Ident "PN14_IBS_DATA_2";
BA_ "FlexKomSigLaenge" SG_ 564 IBS_Error_Ident 32;
BA_ "FlexKomSigStartPos" SG_ 564 IBS_Error_Ident 7;
BA_ "FlexKomSID" SG_ 564 IBS_Error_Ident 1405;
BA_ "FlexKomSigStartValue" SG_ 564 IBS_Error_Ident "FF0300FFh";
BA_ "GenSigCycleTime" SG_ 564 IBS_Error_Ident 100;
BA_ "GenSigSNA" SG_ 564 IBS_Error_Calib "0h";
BA_ "FlexKomIsMotorola" SG_ 564 IBS_Error_Calib 1;
BA_ "FlexKomComment" SG_ 564 IBS_Error_Calib "IBS Battery Information additional";
BA_ "FlexKomSigName" SG_ 564 IBS_Error_Calib "PN14_IBS_DATA_2";
BA_ "FlexKomSigLaenge" SG_ 564 IBS_Error_Calib 32;
BA_ "FlexKomSigStartPos" SG_ 564 IBS_Error_Calib 7;
BA_ "FlexKomSID" SG_ 564 IBS_Error_Calib 1405;
BA_ "FlexKomSigStartValue" SG_ 564 IBS_Error_Calib "FF0300FFh";
BA_ "GenSigCycleTime" SG_ 564 IBS_Error_Calib 100;
BA_ "GenSigSNA" SG_ 564 AM_ECM_Trace "3h";
BA_ "FlexKomIsMotorola" SG_ 564 AM_ECM_Trace 1;
BA_ "FlexKomComment" SG_ 564 AM_ECM_Trace "Aftermarket ECM trace";
BA_ "FlexKomSigName" SG_ 564 AM_ECM_Trace "AM_ECM_Trace";
BA_ "FlexKomSigLaenge" SG_ 564 AM_ECM_Trace 2;
BA_ "FlexKomSigStartPos" SG_ 564 AM_ECM_Trace 23;
BA_ "FlexKomSID" SG_ 564 AM_ECM_Trace 1942;
BA_ "FlexKomSigStartValue" SG_ 564 AM_ECM_Trace "00h";
BA_ "GenSigCycleTime" SG_ 564 AM_ECM_Trace 100;
BA_ "GenMsgStartValue" BO_ 560 "08000000h";
BA_ "GenMsgNrOfRepetitions" BO_ 560 2;
BA_ "GenMsgDelayTime" BO_ 560 20;
BA_ "GenMsgCycleTime" BO_ 560 500;
BA_ "GenMsgSendType" BO_ 560 5;
BA_ "GenSigSNA" SG_ 560 EvapTempTar "FFh";
BA_ "FlexKomIsMotorola" SG_ 560 EvapTempTar 1;
BA_ "FlexKomComment" SG_ 560 EvapTempTar "Evaporator temperature target";
BA_ "FlexKomSigName" SG_ 560 EvapTempTar "EvapTempTar";
BA_ "FlexKomSigLaenge" SG_ 560 EvapTempTar 8;
BA_ "FlexKomSigStartPos" SG_ 560 EvapTempTar 23;
BA_ "FlexKomSID" SG_ 560 EvapTempTar 30;
BA_ "FlexKomSigStartValue" SG_ 560 EvapTempTar "00h";
BA_ "GenSigCycleTime" SG_ 560 EvapTempTar 500;
BA_ "GenSigSendType" SG_ 560 EvapTempTar 5;
BA_ "GenSigSNA" SG_ 560 EVAP_TEMP "FFh";
BA_ "FlexKomIsMotorola" SG_ 560 EVAP_TEMP 1;
BA_ "FlexKomComment" SG_ 560 EVAP_TEMP "AC evaporator temperature";
BA_ "FlexKomSigName" SG_ 560 EVAP_TEMP "EVAP_TEMP";
BA_ "FlexKomSigLaenge" SG_ 560 EVAP_TEMP 8;
BA_ "FlexKomSigStartPos" SG_ 560 EVAP_TEMP 15;
BA_ "FlexKomSID" SG_ 560 EVAP_TEMP 29;
BA_ "FlexKomSigStartValue" SG_ 560 EVAP_TEMP "00h";
BA_ "GenSigCycleTime" SG_ 560 EVAP_TEMP 500;
BA_ "GenSigSendType" SG_ 560 EVAP_TEMP 5;
BA_ "GenSigSNA" SG_ 560 DEFROST_SEL "0h";
BA_ "FlexKomIsMotorola" SG_ 560 DEFROST_SEL 1;
BA_ "FlexKomComment" SG_ 560 DEFROST_SEL "Defrost select switch";
BA_ "FlexKomSigName" SG_ 560 DEFROST_SEL "DEFROST_SEL";
BA_ "FlexKomSigLaenge" SG_ 560 DEFROST_SEL 1;
BA_ "FlexKomSigStartPos" SG_ 560 DEFROST_SEL 2;
BA_ "FlexKomSID" SG_ 560 DEFROST_SEL 28;
BA_ "FlexKomSigStartValue" SG_ 560 DEFROST_SEL "00h";
BA_ "GenSigCycleTime" SG_ 560 DEFROST_SEL 500;
BA_ "GenSigSendType" SG_ 560 DEFROST_SEL 5;
BA_ "GenSigSNA" SG_ 560 AC_SEL "0h";
BA_ "FlexKomIsMotorola" SG_ 560 AC_SEL 1;
BA_ "FlexKomComment" SG_ 560 AC_SEL "Customer has selected A/C; [1] = A/C selected; 0 =";
BA_ "FlexKomSigName" SG_ 560 AC_SEL "AC_SEL";
BA_ "FlexKomSigLaenge" SG_ 560 AC_SEL 1;
BA_ "FlexKomSigStartPos" SG_ 560 AC_SEL 1;
BA_ "FlexKomSID" SG_ 560 AC_SEL 31;
BA_ "FlexKomSigStartValue" SG_ 560 AC_SEL "00h";
BA_ "GenSigCycleTime" SG_ 560 AC_SEL 500;
BA_ "GenSigSendType" SG_ 560 AC_SEL 5;
BA_ "GenSigSNA" SG_ 560 AC_RQ "0h";
BA_ "FlexKomIsMotorola" SG_ 560 AC_RQ 1;
BA_ "FlexKomComment" SG_ 560 AC_RQ "A/C clutch request; [1] = A/C Clutch requested; 0";
BA_ "FlexKomSigName" SG_ 560 AC_RQ "AC_RQ";
BA_ "FlexKomSigLaenge" SG_ 560 AC_RQ 1;
BA_ "FlexKomSID" SG_ 560 AC_RQ 27;
BA_ "FlexKomSigStartValue" SG_ 560 AC_RQ "00h";
BA_ "GenSigCycleTime" SG_ 560 AC_RQ 500;
BA_ "GenSigSendType" SG_ 560 AC_RQ 5;
BA_ "GenSigSNA" SG_ 560 AC_PT_Demand "0h";
BA_ "FlexKomIsMotorola" SG_ 560 AC_PT_Demand 1;
BA_ "FlexKomComment" SG_ 560 AC_PT_Demand "Maximum A/C demand to powertrain";
BA_ "FlexKomSigName" SG_ 560 AC_PT_Demand "AC_PT_Demand";
BA_ "FlexKomSigLaenge" SG_ 560 AC_PT_Demand 1;
BA_ "FlexKomSigStartPos" SG_ 560 AC_PT_Demand 5;
BA_ "FlexKomSID" SG_ 560 AC_PT_Demand 1945;
BA_ "FlexKomSigStartValue" SG_ 560 AC_PT_Demand "00h";
BA_ "GenSigCycleTime" SG_ 560 AC_PT_Demand 500;
BA_ "GenSigSendType" SG_ 560 AC_PT_Demand 5;
BA_ "GenMsgStartValue" BO_ 559 "FFFFFFFF00000CFFh";
BA_ "GenMsgNrOfRepetitions" BO_ 559 2;
BA_ "GenMsgDelayTime" BO_ 559 20;
BA_ "GenMsgCycleTime" BO_ 559 20;
BA_ "GenSigSNA" SG_ 559 MC_ECM_A5 "0h";
BA_ "FlexKomIsMotorola" SG_ 559 MC_ECM_A5 1;
BA_ "FlexKomComment" SG_ 559 MC_ECM_A5 "ECM_A5 Packet";
BA_ "FlexKomSigName" SG_ 559 MC_ECM_A5 "ECM_A5_PKT";
BA_ "FlexKomSigLaenge" SG_ 559 MC_ECM_A5 64;
BA_ "FlexKomSigStartPos" SG_ 559 MC_ECM_A5 7;
BA_ "FlexKomSID" SG_ 559 MC_ECM_A5 1821;
BA_ "FlexKomSigStartValue" SG_ 559 MC_ECM_A5 "FFFFFFFF00000CFFh";
BA_ "GenSigCycleTime" SG_ 559 MC_ECM_A5 20;
BA_ "GenSigSNA" SG_ 559 CRC_ECM_A5 "FFh";
BA_ "FlexKomIsMotorola" SG_ 559 CRC_ECM_A5 1;
BA_ "FlexKomComment" SG_ 559 CRC_ECM_A5 "ECM_A5 Packet";
BA_ "FlexKomSigName" SG_ 559 CRC_ECM_A5 "ECM_A5_PKT";
BA_ "FlexKomSigLaenge" SG_ 559 CRC_ECM_A5 64;
BA_ "FlexKomSigStartPos" SG_ 559 CRC_ECM_A5 7;
BA_ "FlexKomSID" SG_ 559 CRC_ECM_A5 1821;
BA_ "GenSigStartValue" SG_ 559 CRC_ECM_A5 255;
BA_ "FlexKomSigStartValue" SG_ 559 CRC_ECM_A5 "FFFFFFFF00000CFFh";
BA_ "GenSigCycleTime" SG_ 559 CRC_ECM_A5 20;
BA_ "GenSigSNA" SG_ 559 ActlAccelPdlPosn "FFh";
BA_ "FlexKomIsMotorola" SG_ 559 ActlAccelPdlPosn 1;
BA_ "FlexKomComment" SG_ 559 ActlAccelPdlPosn "ECM_A5 Packet";
BA_ "FlexKomSigName" SG_ 559 ActlAccelPdlPosn "ECM_A5_PKT";
BA_ "FlexKomSigLaenge" SG_ 559 ActlAccelPdlPosn 64;
BA_ "FlexKomSigStartPos" SG_ 559 ActlAccelPdlPosn 7;
BA_ "FlexKomSID" SG_ 559 ActlAccelPdlPosn 1821;
BA_ "GenSigStartValue" SG_ 559 ActlAccelPdlPosn 255;
BA_ "FlexKomSigStartValue" SG_ 559 ActlAccelPdlPosn "FFFFFFFF00000CFFh";
BA_ "GenSigCycleTime" SG_ 559 ActlAccelPdlPosn 20;
BA_ "GenSigTimeout_CBC" SG_ 559 ActlAccelPdlPosn 210;
BA_ "GenMsgStartDelayTime" BO_ 557 110;
BA_ "GenMsgStartValue" BO_ 557 "FF00000000000000h";
BA_ "GenMsgNrOfRepetitions" BO_ 557 2;
BA_ "GenMsgDelayTime" BO_ 557 20;
BA_ "GenMsgCycleTime" BO_ 557 1000;
BA_ "GenMsgSendType" BO_ 557 5;
BA_ "GenSigSNA" SG_ 557 Command_15 "3h";
BA_ "FlexKomIsMotorola" SG_ 557 Command_15 1;
BA_ "FlexKomComment" SG_ 557 Command_15 "Steering wheel switch packet";
BA_ "FlexKomSigName" SG_ 557 Command_15 "SWS8_Pkt";
BA_ "FlexKomSigLaenge" SG_ 557 Command_15 64;
BA_ "FlexKomSigStartPos" SG_ 557 Command_15 7;
BA_ "FlexKomSID" SG_ 557 Command_15 1811;
BA_ "GenSigTimeout_IC" SG_ 557 Command_15 10500;
BA_ "FlexKomSigStartValue" SG_ 557 Command_15 "FF00000000000000h";
BA_ "GenSigCycleTime" SG_ 557 Command_15 1000;
BA_ "GenSigSendType" SG_ 557 Command_15 5;
BA_ "GenSigSNA" SG_ 557 Command_14 "3h";
BA_ "FlexKomIsMotorola" SG_ 557 Command_14 1;
BA_ "FlexKomComment" SG_ 557 Command_14 "Steering wheel switch packet";
BA_ "FlexKomSigName" SG_ 557 Command_14 "SWS8_Pkt";
BA_ "FlexKomSigLaenge" SG_ 557 Command_14 64;
BA_ "FlexKomSigStartPos" SG_ 557 Command_14 7;
BA_ "FlexKomSID" SG_ 557 Command_14 1811;
BA_ "GenSigTimeout_IC" SG_ 557 Command_14 10500;
BA_ "FlexKomSigStartValue" SG_ 557 Command_14 "FF00000000000000h";
BA_ "GenSigCycleTime" SG_ 557 Command_14 1000;
BA_ "GenSigSendType" SG_ 557 Command_14 5;
BA_ "GenSigSNA" SG_ 557 Command_13 "3h";
BA_ "FlexKomIsMotorola" SG_ 557 Command_13 1;
BA_ "FlexKomComment" SG_ 557 Command_13 "Steering wheel switch packet";
BA_ "FlexKomSigName" SG_ 557 Command_13 "SWS8_Pkt";
BA_ "FlexKomSigLaenge" SG_ 557 Command_13 64;
BA_ "FlexKomSigStartPos" SG_ 557 Command_13 7;
BA_ "FlexKomSID" SG_ 557 Command_13 1811;
BA_ "GenSigTimeout_IC" SG_ 557 Command_13 10500;
BA_ "FlexKomSigStartValue" SG_ 557 Command_13 "FF00000000000000h";
BA_ "GenSigCycleTime" SG_ 557 Command_13 1000;
BA_ "GenSigSendType" SG_ 557 Command_13 5;
BA_ "GenSigSNA" SG_ 557 Command_12 "3h";
BA_ "FlexKomIsMotorola" SG_ 557 Command_12 1;
BA_ "FlexKomComment" SG_ 557 Command_12 "Steering wheel switch packet";
BA_ "FlexKomSigName" SG_ 557 Command_12 "SWS8_Pkt";
BA_ "FlexKomSigLaenge" SG_ 557 Command_12 64;
BA_ "FlexKomSigStartPos" SG_ 557 Command_12 7;
BA_ "FlexKomSID" SG_ 557 Command_12 1811;
BA_ "GenSigTimeout_IC" SG_ 557 Command_12 10500;
BA_ "FlexKomSigStartValue" SG_ 557 Command_12 "FF00000000000000h";
BA_ "GenSigCycleTime" SG_ 557 Command_12 1000;
BA_ "GenSigSendType" SG_ 557 Command_12 5;
BA_ "GenSigSNA" SG_ 557 Command_11 "3h";
BA_ "FlexKomIsMotorola" SG_ 557 Command_11 1;
BA_ "FlexKomComment" SG_ 557 Command_11 "Steering wheel switch packet";
BA_ "FlexKomSigName" SG_ 557 Command_11 "SWS8_Pkt";
BA_ "FlexKomSigLaenge" SG_ 557 Command_11 64;
BA_ "FlexKomSigStartPos" SG_ 557 Command_11 7;
BA_ "FlexKomSID" SG_ 557 Command_11 1811;
BA_ "GenSigTimeout_IC" SG_ 557 Command_11 10500;
BA_ "FlexKomSigStartValue" SG_ 557 Command_11 "FF00000000000000h";
BA_ "GenSigCycleTime" SG_ 557 Command_11 1000;
BA_ "GenSigSendType" SG_ 557 Command_11 5;
BA_ "GenMsgStartValue" BO_ 544 "07FF0FFF040000FFh";
BA_ "GenMsgNrOfRepetitions" BO_ 544 2;
BA_ "GenMsgDelayTime" BO_ 544 20;
BA_ "GenMsgCycleTime" BO_ 544 10;
BA_ "GenSigSNA" SG_ 544 TOI_Act_Sts "Fh";
BA_ "FlexKomIsMotorola" SG_ 544 TOI_Act_Sts 1;
BA_ "FlexKomComment" SG_ 544 TOI_Act_Sts "EPS_1 packet";
BA_ "FlexKomSigName" SG_ 544 TOI_Act_Sts "EPS_1_PKT";
BA_ "FlexKomSigLaenge" SG_ 544 TOI_Act_Sts 64;
BA_ "FlexKomSigStartPos" SG_ 544 TOI_Act_Sts 7;
BA_ "FlexKomSID" SG_ 544 TOI_Act_Sts 1415;
BA_ "GenSigTimeout_HaLF" SG_ 544 TOI_Act_Sts 105;
BA_ "GenSigTimeout_PTS" SG_ 544 TOI_Act_Sts 105;
BA_ "FlexKomSigStartValue" SG_ 544 TOI_Act_Sts "07FF0FFF040000FFh";
BA_ "GenSigCycleTime" SG_ 544 TOI_Act_Sts 10;
BA_ "GenSigSNA" SG_ 544 StrClmTrqVD "0h";
BA_ "FlexKomIsMotorola" SG_ 544 StrClmTrqVD 1;
BA_ "FlexKomComment" SG_ 544 StrClmTrqVD "EPS_1 packet";
BA_ "FlexKomSigName" SG_ 544 StrClmTrqVD "EPS_1_PKT";
BA_ "FlexKomSigLaenge" SG_ 544 StrClmTrqVD 64;
BA_ "FlexKomSigStartPos" SG_ 544 StrClmTrqVD 7;
BA_ "FlexKomSID" SG_ 544 StrClmTrqVD 1415;
BA_ "GenSigTimeout_HaLF" SG_ 544 StrClmTrqVD 105;
BA_ "GenSigTimeout_PTS" SG_ 544 StrClmTrqVD 105;
BA_ "FlexKomSigStartValue" SG_ 544 StrClmTrqVD "07FF0FFF040000FFh";
BA_ "GenSigCycleTime" SG_ 544 StrClmTrqVD 10;
BA_ "GenSigSNA" SG_ 544 StrClmTrq "7FFh";
BA_ "FlexKomIsMotorola" SG_ 544 StrClmTrq 1;
BA_ "FlexKomComment" SG_ 544 StrClmTrq "EPS_1 packet";
BA_ "FlexKomSigName" SG_ 544 StrClmTrq "EPS_1_PKT";
BA_ "FlexKomSigLaenge" SG_ 544 StrClmTrq 64;
BA_ "FlexKomSigStartPos" SG_ 544 StrClmTrq 7;
BA_ "FlexKomSID" SG_ 544 StrClmTrq 1415;
BA_ "GenSigTimeout_HaLF" SG_ 544 StrClmTrq 105;
BA_ "GenSigTimeout_PTS" SG_ 544 StrClmTrq 105;
BA_ "GenSigStartValue" SG_ 544 StrClmTrq 2047;
BA_ "FlexKomSigStartValue" SG_ 544 StrClmTrq "07FF0FFF040000FFh";
BA_ "GenSigCycleTime" SG_ 544 StrClmTrq 10;
BA_ "GenSigSNA" SG_ 544 PTSTorqueOverlayIntActivated "0h";
BA_ "FlexKomIsMotorola" SG_ 544 PTSTorqueOverlayIntActivated 1;
BA_ "FlexKomComment" SG_ 544 PTSTorqueOverlayIntActivated "EPS_1 packet";
BA_ "FlexKomSigName" SG_ 544 PTSTorqueOverlayIntActivated "EPS_1_PKT";
BA_ "FlexKomSigLaenge" SG_ 544 PTSTorqueOverlayIntActivated 64;
BA_ "FlexKomSigStartPos" SG_ 544 PTSTorqueOverlayIntActivated 7;
BA_ "FlexKomSID" SG_ 544 PTSTorqueOverlayIntActivated 1415;
BA_ "GenSigTimeout_HaLF" SG_ 544 PTSTorqueOverlayIntActivated 105;
BA_ "GenSigTimeout_PTS" SG_ 544 PTSTorqueOverlayIntActivated 105;
BA_ "FlexKomSigStartValue" SG_ 544 PTSTorqueOverlayIntActivated "07FF0FFF040000FFh";
BA_ "GenSigCycleTime" SG_ 544 PTSTorqueOverlayIntActivated 10;
BA_ "GenSigSNA" SG_ 544 PTSTorqueOverlayFault "0h";
BA_ "FlexKomIsMotorola" SG_ 544 PTSTorqueOverlayFault 1;
BA_ "FlexKomComment" SG_ 544 PTSTorqueOverlayFault "EPS_1 packet";
BA_ "FlexKomSigName" SG_ 544 PTSTorqueOverlayFault "EPS_1_PKT";
BA_ "FlexKomSigLaenge" SG_ 544 PTSTorqueOverlayFault 64;
BA_ "FlexKomSigStartPos" SG_ 544 PTSTorqueOverlayFault 7;
BA_ "FlexKomSID" SG_ 544 PTSTorqueOverlayFault 1415;
BA_ "GenSigTimeout_HaLF" SG_ 544 PTSTorqueOverlayFault 105;
BA_ "GenSigTimeout_PTS" SG_ 544 PTSTorqueOverlayFault 105;
BA_ "FlexKomSigStartValue" SG_ 544 PTSTorqueOverlayFault "07FF0FFF040000FFh";
BA_ "GenSigCycleTime" SG_ 544 PTSTorqueOverlayFault 10;
BA_ "GenSigSNA" SG_ 544 PTSDriveStyleSts "0h";
BA_ "FlexKomIsMotorola" SG_ 544 PTSDriveStyleSts 1;
BA_ "FlexKomComment" SG_ 544 PTSDriveStyleSts "EPS_1 packet";
BA_ "FlexKomSigName" SG_ 544 PTSDriveStyleSts "EPS_1_PKT";
BA_ "FlexKomSigLaenge" SG_ 544 PTSDriveStyleSts 64;
BA_ "FlexKomSigStartPos" SG_ 544 PTSDriveStyleSts 7;
BA_ "FlexKomSID" SG_ 544 PTSDriveStyleSts 1415;
BA_ "GenSigTimeout_HaLF" SG_ 544 PTSDriveStyleSts 105;
BA_ "GenSigTimeout_PTS" SG_ 544 PTSDriveStyleSts 105;
BA_ "FlexKomSigStartValue" SG_ 544 PTSDriveStyleSts "07FF0FFF040000FFh";
BA_ "GenSigCycleTime" SG_ 544 PTSDriveStyleSts 10;
BA_ "GenSigSNA" SG_ 544 MC_EPS_1 "0h";
BA_ "FlexKomIsMotorola" SG_ 544 MC_EPS_1 1;
BA_ "FlexKomComment" SG_ 544 MC_EPS_1 "EPS_1 packet";
BA_ "FlexKomSigName" SG_ 544 MC_EPS_1 "EPS_1_PKT";
BA_ "FlexKomSigLaenge" SG_ 544 MC_EPS_1 64;
BA_ "FlexKomSigStartPos" SG_ 544 MC_EPS_1 7;
BA_ "FlexKomSID" SG_ 544 MC_EPS_1 1415;
BA_ "GenSigTimeout_HaLF" SG_ 544 MC_EPS_1 105;
BA_ "GenSigTimeout_PTS" SG_ 544 MC_EPS_1 105;
BA_ "FlexKomSigStartValue" SG_ 544 MC_EPS_1 "07FF0FFF040000FFh";
BA_ "GenSigCycleTime" SG_ 544 MC_EPS_1 10;
BA_ "GenSigSNA" SG_ 544 HALFTorqueOverlayIntActivated "0h";
BA_ "FlexKomIsMotorola" SG_ 544 HALFTorqueOverlayIntActivated 1;
BA_ "FlexKomComment" SG_ 544 HALFTorqueOverlayIntActivated "EPS_1 packet";
BA_ "FlexKomSigName" SG_ 544 HALFTorqueOverlayIntActivated "EPS_1_PKT";
BA_ "FlexKomSigLaenge" SG_ 544 HALFTorqueOverlayIntActivated 64;
BA_ "FlexKomSigStartPos" SG_ 544 HALFTorqueOverlayIntActivated 7;
BA_ "FlexKomSID" SG_ 544 HALFTorqueOverlayIntActivated 1415;
BA_ "GenSigTimeout_HaLF" SG_ 544 HALFTorqueOverlayIntActivated 105;
BA_ "GenSigTimeout_PTS" SG_ 544 HALFTorqueOverlayIntActivated 105;
BA_ "FlexKomSigStartValue" SG_ 544 HALFTorqueOverlayIntActivated "07FF0FFF040000FFh";
BA_ "GenSigCycleTime" SG_ 544 HALFTorqueOverlayIntActivated 10;
BA_ "GenSigSNA" SG_ 544 HALFTorqueOverlayFault "0h";
BA_ "FlexKomIsMotorola" SG_ 544 HALFTorqueOverlayFault 1;
BA_ "FlexKomComment" SG_ 544 HALFTorqueOverlayFault "EPS_1 packet";
BA_ "FlexKomSigName" SG_ 544 HALFTorqueOverlayFault "EPS_1_PKT";
BA_ "FlexKomSigLaenge" SG_ 544 HALFTorqueOverlayFault 64;
BA_ "FlexKomSigStartPos" SG_ 544 HALFTorqueOverlayFault 7;
BA_ "FlexKomSID" SG_ 544 HALFTorqueOverlayFault 1415;
BA_ "GenSigTimeout_HaLF" SG_ 544 HALFTorqueOverlayFault 105;
BA_ "GenSigTimeout_PTS" SG_ 544 HALFTorqueOverlayFault 105;
BA_ "FlexKomSigStartValue" SG_ 544 HALFTorqueOverlayFault "07FF0FFF040000FFh";
BA_ "GenSigCycleTime" SG_ 544 HALFTorqueOverlayFault 10;
BA_ "GenSigSNA" SG_ 544 EPSTemporaryDeactivationPPPA "0h";
BA_ "FlexKomIsMotorola" SG_ 544 EPSTemporaryDeactivationPPPA 1;
BA_ "FlexKomComment" SG_ 544 EPSTemporaryDeactivationPPPA "EPS_1 packet";
BA_ "FlexKomSigName" SG_ 544 EPSTemporaryDeactivationPPPA "EPS_1_PKT";
BA_ "FlexKomSigLaenge" SG_ 544 EPSTemporaryDeactivationPPPA 64;
BA_ "FlexKomSigStartPos" SG_ 544 EPSTemporaryDeactivationPPPA 7;
BA_ "FlexKomSID" SG_ 544 EPSTemporaryDeactivationPPPA 1415;
BA_ "GenSigTimeout_HaLF" SG_ 544 EPSTemporaryDeactivationPPPA 105;
BA_ "GenSigTimeout_PTS" SG_ 544 EPSTemporaryDeactivationPPPA 105;
BA_ "FlexKomSigStartValue" SG_ 544 EPSTemporaryDeactivationPPPA "07FF0FFF040000FFh";
BA_ "GenSigCycleTime" SG_ 544 EPSTemporaryDeactivationPPPA 10;
BA_ "GenSigSNA" SG_ 544 EPSTemporaryDeactivationLDW "0h";
BA_ "FlexKomIsMotorola" SG_ 544 EPSTemporaryDeactivationLDW 1;
BA_ "FlexKomComment" SG_ 544 EPSTemporaryDeactivationLDW "EPS_1 packet";
BA_ "FlexKomSigName" SG_ 544 EPSTemporaryDeactivationLDW "EPS_1_PKT";
BA_ "FlexKomSigLaenge" SG_ 544 EPSTemporaryDeactivationLDW 64;
BA_ "FlexKomSigStartPos" SG_ 544 EPSTemporaryDeactivationLDW 7;
BA_ "FlexKomSID" SG_ 544 EPSTemporaryDeactivationLDW 1415;
BA_ "FlexKomSigStartValue" SG_ 544 EPSTemporaryDeactivationLDW "07FF0FFF040000FFh";
BA_ "GenSigCycleTime" SG_ 544 EPSTemporaryDeactivationLDW 10;
BA_ "GenSigSNA" SG_ 544 EPSMotorTorqueValidData "0h";
BA_ "FlexKomIsMotorola" SG_ 544 EPSMotorTorqueValidData 1;
BA_ "FlexKomComment" SG_ 544 EPSMotorTorqueValidData "EPS_1 packet";
BA_ "FlexKomSigName" SG_ 544 EPSMotorTorqueValidData "EPS_1_PKT";
BA_ "FlexKomSigLaenge" SG_ 544 EPSMotorTorqueValidData 64;
BA_ "FlexKomSigStartPos" SG_ 544 EPSMotorTorqueValidData 7;
BA_ "FlexKomSID" SG_ 544 EPSMotorTorqueValidData 1415;
BA_ "GenSigTimeout_HaLF" SG_ 544 EPSMotorTorqueValidData 105;
BA_ "FlexKomSigStartValue" SG_ 544 EPSMotorTorqueValidData "07FF0FFF040000FFh";
BA_ "GenSigCycleTime" SG_ 544 EPSMotorTorqueValidData 10;
BA_ "GenSigSNA" SG_ 544 EPSMotorTorque "400h";
BA_ "FlexKomIsMotorola" SG_ 544 EPSMotorTorque 1;
BA_ "FlexKomComment" SG_ 544 EPSMotorTorque "EPS_1 packet";
BA_ "FlexKomSigName" SG_ 544 EPSMotorTorque "EPS_1_PKT";
BA_ "FlexKomSigLaenge" SG_ 544 EPSMotorTorque 64;
BA_ "FlexKomSigStartPos" SG_ 544 EPSMotorTorque 7;
BA_ "FlexKomSID" SG_ 544 EPSMotorTorque 1415;
BA_ "GenSigTimeout_HaLF" SG_ 544 EPSMotorTorque 105;
BA_ "GenSigStartValue" SG_ 544 EPSMotorTorque 1024;
BA_ "FlexKomSigStartValue" SG_ 544 EPSMotorTorque "07FF0FFF040000FFh";
BA_ "GenSigCycleTime" SG_ 544 EPSMotorTorque 10;
BA_ "GenSigSNA" SG_ 544 EPSHandsOnRecognition "0h";
BA_ "FlexKomIsMotorola" SG_ 544 EPSHandsOnRecognition 1;
BA_ "FlexKomComment" SG_ 544 EPSHandsOnRecognition "EPS_1 packet";
BA_ "FlexKomSigName" SG_ 544 EPSHandsOnRecognition "EPS_1_PKT";
BA_ "FlexKomSigLaenge" SG_ 544 EPSHandsOnRecognition 64;
BA_ "FlexKomSigStartPos" SG_ 544 EPSHandsOnRecognition 7;
BA_ "FlexKomSID" SG_ 544 EPSHandsOnRecognition 1415;
BA_ "GenSigTimeout_HaLF" SG_ 544 EPSHandsOnRecognition 105;
BA_ "GenSigTimeout_PTS" SG_ 544 EPSHandsOnRecognition 105;
BA_ "FlexKomSigStartValue" SG_ 544 EPSHandsOnRecognition "07FF0FFF040000FFh";
BA_ "GenSigCycleTime" SG_ 544 EPSHandsOnRecognition 10;
BA_ "GenSigSNA" SG_ 544 DSTTorqueOverlayIntActivated "0h";
BA_ "FlexKomIsMotorola" SG_ 544 DSTTorqueOverlayIntActivated 1;
BA_ "FlexKomComment" SG_ 544 DSTTorqueOverlayIntActivated "EPS_1 packet";
BA_ "FlexKomSigName" SG_ 544 DSTTorqueOverlayIntActivated "EPS_1_PKT";
BA_ "FlexKomSigLaenge" SG_ 544 DSTTorqueOverlayIntActivated 64;
BA_ "FlexKomSigStartPos" SG_ 544 DSTTorqueOverlayIntActivated 7;
BA_ "FlexKomSID" SG_ 544 DSTTorqueOverlayIntActivated 1415;
BA_ "GenSigTimeout_HaLF" SG_ 544 DSTTorqueOverlayIntActivated 105;
BA_ "FlexKomSigStartValue" SG_ 544 DSTTorqueOverlayIntActivated "07FF0FFF040000FFh";
BA_ "GenSigCycleTime" SG_ 544 DSTTorqueOverlayIntActivated 10;
BA_ "GenSigSNA" SG_ 544 DSTTorqueOverlayFault "0h";
BA_ "FlexKomIsMotorola" SG_ 544 DSTTorqueOverlayFault 1;
BA_ "FlexKomComment" SG_ 544 DSTTorqueOverlayFault "EPS_1 packet";
BA_ "FlexKomSigName" SG_ 544 DSTTorqueOverlayFault "EPS_1_PKT";
BA_ "FlexKomSigLaenge" SG_ 544 DSTTorqueOverlayFault 64;
BA_ "FlexKomSigStartPos" SG_ 544 DSTTorqueOverlayFault 7;
BA_ "FlexKomSID" SG_ 544 DSTTorqueOverlayFault 1415;
BA_ "GenSigTimeout_HaLF" SG_ 544 DSTTorqueOverlayFault 105;
BA_ "GenSigTimeout_PTS" SG_ 544 DSTTorqueOverlayFault 105;
BA_ "FlexKomSigStartValue" SG_ 544 DSTTorqueOverlayFault "07FF0FFF040000FFh";
BA_ "GenSigCycleTime" SG_ 544 DSTTorqueOverlayFault 10;
BA_ "GenSigSNA" SG_ 544 CRC_EPS_1 "FFh";
BA_ "FlexKomIsMotorola" SG_ 544 CRC_EPS_1 1;
BA_ "FlexKomComment" SG_ 544 CRC_EPS_1 "EPS_1 packet";
BA_ "FlexKomSigName" SG_ 544 CRC_EPS_1 "EPS_1_PKT";
BA_ "FlexKomSigLaenge" SG_ 544 CRC_EPS_1 64;
BA_ "FlexKomSigStartPos" SG_ 544 CRC_EPS_1 7;
BA_ "FlexKomSID" SG_ 544 CRC_EPS_1 1415;
BA_ "GenSigTimeout_HaLF" SG_ 544 CRC_EPS_1 105;
BA_ "GenSigTimeout_PTS" SG_ 544 CRC_EPS_1 105;
BA_ "GenSigStartValue" SG_ 544 CRC_EPS_1 255;
BA_ "FlexKomSigStartValue" SG_ 544 CRC_EPS_1 "07FF0FFF040000FFh";
BA_ "GenSigCycleTime" SG_ 544 CRC_EPS_1 10;
BA_ "GenSigSNA" SG_ 544 AssistanceTorque "FFFh";
BA_ "FlexKomIsMotorola" SG_ 544 AssistanceTorque 1;
BA_ "FlexKomComment" SG_ 544 AssistanceTorque "EPS_1 packet";
BA_ "FlexKomSigName" SG_ 544 AssistanceTorque "EPS_1_PKT";
BA_ "FlexKomSigLaenge" SG_ 544 AssistanceTorque 64;
BA_ "FlexKomSigStartPos" SG_ 544 AssistanceTorque 7;
BA_ "FlexKomSID" SG_ 544 AssistanceTorque 1415;
BA_ "GenSigTimeout_HaLF" SG_ 544 AssistanceTorque 105;
BA_ "GenSigTimeout_PTS" SG_ 544 AssistanceTorque 105;
BA_ "GenSigStartValue" SG_ 544 AssistanceTorque 4095;
BA_ "FlexKomSigStartValue" SG_ 544 AssistanceTorque "07FF0FFF040000FFh";
BA_ "GenSigCycleTime" SG_ 544 AssistanceTorque 10;
BA_ "GenMsgStartDelayTime" BO_ 532 10;
BA_ "GenMsgStartValue" BO_ 532 "3FFFFFFFFF03FFC0h";
BA_ "GenMsgNrOfRepetitions" BO_ 532 2;
BA_ "GenMsgDelayTime" BO_ 532 20;
BA_ "GenMsgCycleTime" BO_ 532 100;
BA_ "GenSigSNA" SG_ 532 IBS_Voltage_Status "0h";
BA_ "FlexKomIsMotorola" SG_ 532 IBS_Voltage_Status 1;
BA_ "FlexKomComment" SG_ 532 IBS_Voltage_Status "IBS Battery Information";
BA_ "FlexKomSigName" SG_ 532 IBS_Voltage_Status "PN14_IBS_DATA";
BA_ "FlexKomSigLaenge" SG_ 532 IBS_Voltage_Status 64;
BA_ "FlexKomSigStartPos" SG_ 532 IBS_Voltage_Status 7;
BA_ "FlexKomSID" SG_ 532 IBS_Voltage_Status 1094;
BA_ "FlexKomSigStartValue" SG_ 532 IBS_Voltage_Status "3FFFFFFFFF03FFC0h";
BA_ "GenSigCycleTime" SG_ 532 IBS_Voltage_Status 100;
BA_ "GenSigSNA" SG_ 532 IBS_V_BATT "3FFFh";
BA_ "FlexKomIsMotorola" SG_ 532 IBS_V_BATT 1;
BA_ "FlexKomComment" SG_ 532 IBS_V_BATT "IBS Battery Information";
BA_ "FlexKomSigName" SG_ 532 IBS_V_BATT "PN14_IBS_DATA";
BA_ "FlexKomSigLaenge" SG_ 532 IBS_V_BATT 64;
BA_ "FlexKomSigStartPos" SG_ 532 IBS_V_BATT 7;
BA_ "FlexKomSID" SG_ 532 IBS_V_BATT 1094;
BA_ "GenSigStartValue" SG_ 532 IBS_V_BATT 16383;
BA_ "FlexKomSigStartValue" SG_ 532 IBS_V_BATT "3FFFFFFFFF03FFC0h";
BA_ "GenSigCycleTime" SG_ 532 IBS_V_BATT 100;
BA_ "GenSigSNA" SG_ 532 IBS_Temp_Status "0h";
BA_ "FlexKomIsMotorola" SG_ 532 IBS_Temp_Status 1;
BA_ "FlexKomComment" SG_ 532 IBS_Temp_Status "IBS Battery Information";
BA_ "FlexKomSigName" SG_ 532 IBS_Temp_Status "PN14_IBS_DATA";
BA_ "FlexKomSigLaenge" SG_ 532 IBS_Temp_Status 64;
BA_ "FlexKomSigStartPos" SG_ 532 IBS_Temp_Status 7;
BA_ "FlexKomSID" SG_ 532 IBS_Temp_Status 1094;
BA_ "FlexKomSigStartValue" SG_ 532 IBS_Temp_Status "3FFFFFFFFF03FFC0h";
BA_ "GenSigCycleTime" SG_ 532 IBS_Temp_Status 100;
BA_ "GenSigSNA" SG_ 532 IBS_T_BATT "FFh";
BA_ "FlexKomIsMotorola" SG_ 532 IBS_T_BATT 1;
BA_ "FlexKomComment" SG_ 532 IBS_T_BATT "IBS Battery Information";
BA_ "FlexKomSigName" SG_ 532 IBS_T_BATT "PN14_IBS_DATA";
BA_ "FlexKomSigLaenge" SG_ 532 IBS_T_BATT 64;
BA_ "FlexKomSigStartPos" SG_ 532 IBS_T_BATT 7;
BA_ "FlexKomSID" SG_ 532 IBS_T_BATT 1094;
BA_ "GenSigStartValue" SG_ 532 IBS_T_BATT 255;
BA_ "FlexKomSigStartValue" SG_ 532 IBS_T_BATT "3FFFFFFFFF03FFC0h";
BA_ "GenSigCycleTime" SG_ 532 IBS_T_BATT 100;
BA_ "GenSigSNA" SG_ 532 IBS_PreWakeupVoltage "3FFh";
BA_ "FlexKomIsMotorola" SG_ 532 IBS_PreWakeupVoltage 1;
BA_ "FlexKomComment" SG_ 532 IBS_PreWakeupVoltage "IBS Battery Information";
BA_ "FlexKomSigName" SG_ 532 IBS_PreWakeupVoltage "PN14_IBS_DATA";
BA_ "FlexKomSigLaenge" SG_ 532 IBS_PreWakeupVoltage 64;
BA_ "FlexKomSigStartPos" SG_ 532 IBS_PreWakeupVoltage 7;
BA_ "FlexKomSID" SG_ 532 IBS_PreWakeupVoltage 1094;
BA_ "GenSigStartValue" SG_ 532 IBS_PreWakeupVoltage 1023;
BA_ "FlexKomSigStartValue" SG_ 532 IBS_PreWakeupVoltage "3FFFFFFFFF03FFC0h";
BA_ "GenSigCycleTime" SG_ 532 IBS_PreWakeupVoltage 100;
BA_ "GenSigSNA" SG_ 532 IBS_I_RANGE "3h";
BA_ "FlexKomIsMotorola" SG_ 532 IBS_I_RANGE 1;
BA_ "FlexKomComment" SG_ 532 IBS_I_RANGE "IBS Battery Information";
BA_ "FlexKomSigName" SG_ 532 IBS_I_RANGE "PN14_IBS_DATA";
BA_ "FlexKomSigLaenge" SG_ 532 IBS_I_RANGE 64;
BA_ "FlexKomSigStartPos" SG_ 532 IBS_I_RANGE 7;
BA_ "FlexKomSID" SG_ 532 IBS_I_RANGE 1094;
BA_ "GenSigStartValue" SG_ 532 IBS_I_RANGE 3;
BA_ "FlexKomSigStartValue" SG_ 532 IBS_I_RANGE "3FFFFFFFFF03FFC0h";
BA_ "GenSigCycleTime" SG_ 532 IBS_I_RANGE 100;
BA_ "GenSigSNA" SG_ 532 IBS_I_BATT "FFFFh";
BA_ "FlexKomIsMotorola" SG_ 532 IBS_I_BATT 1;
BA_ "FlexKomComment" SG_ 532 IBS_I_BATT "IBS Battery Information";
BA_ "FlexKomSigName" SG_ 532 IBS_I_BATT "PN14_IBS_DATA";
BA_ "FlexKomSigLaenge" SG_ 532 IBS_I_BATT 64;
BA_ "FlexKomSigStartPos" SG_ 532 IBS_I_BATT 7;
BA_ "FlexKomSID" SG_ 532 IBS_I_BATT 1094;
BA_ "GenSigStartValue" SG_ 532 IBS_I_BATT 65535;
BA_ "FlexKomSigStartValue" SG_ 532 IBS_I_BATT "3FFFFFFFFF03FFC0h";
BA_ "GenSigCycleTime" SG_ 532 IBS_I_BATT 100;
BA_ "GenSigSNA" SG_ 532 IBS_Current_Status "0h";
BA_ "FlexKomIsMotorola" SG_ 532 IBS_Current_Status 1;
BA_ "FlexKomComment" SG_ 532 IBS_Current_Status "IBS Battery Information";
BA_ "FlexKomSigName" SG_ 532 IBS_Current_Status "PN14_IBS_DATA";
BA_ "FlexKomSigLaenge" SG_ 532 IBS_Current_Status 64;
BA_ "FlexKomSigStartPos" SG_ 532 IBS_Current_Status 7;
BA_ "FlexKomSID" SG_ 532 IBS_Current_Status 1094;
BA_ "FlexKomSigStartValue" SG_ 532 IBS_Current_Status "3FFFFFFFFF03FFC0h";
BA_ "GenSigCycleTime" SG_ 532 IBS_Current_Status 100;
BA_ "GenMsgStartDelayTime" BO_ 520 10;
BA_ "GenMsgStartValue" BO_ 520 "3FFF0C0000000000h";
BA_ "GenMsgNrOfRepetitions" BO_ 520 2;
BA_ "GenMsgDelayTime" BO_ 520 20;
BA_ "GenMsgCycleTime" BO_ 520 20;
BA_ "GenSigCycleTime" SG_ 520 RefuelRequest 20;
BA_ "FlexKomSigStartValue" SG_ 520 RefuelRequest "3FFF0C0000000000h";
BA_ "FlexKomSID" SG_ 520 RefuelRequest 1943;
BA_ "FlexKomSigStartPos" SG_ 520 RefuelRequest 7;
BA_ "FlexKomSigLaenge" SG_ 520 RefuelRequest 64;
BA_ "FlexKomSigName" SG_ 520 RefuelRequest "CBC_PT6_Pkt";
BA_ "FlexKomComment" SG_ 520 RefuelRequest "CBC_PT6 message packet";
BA_ "FlexKomIsMotorola" SG_ 520 RefuelRequest 1;
BA_ "GenSigSNA" SG_ 520 RefuelRequest "3h";
BA_ "GenSigSNA" SG_ 520 PsngrDoorAjarXtionSts "3h";
BA_ "FlexKomIsMotorola" SG_ 520 PsngrDoorAjarXtionSts 1;
BA_ "FlexKomComment" SG_ 520 PsngrDoorAjarXtionSts "CBC_PT6 message packet";
BA_ "FlexKomSigName" SG_ 520 PsngrDoorAjarXtionSts "CBC_PT6_Pkt";
BA_ "FlexKomSigLaenge" SG_ 520 PsngrDoorAjarXtionSts 64;
BA_ "FlexKomSigStartPos" SG_ 520 PsngrDoorAjarXtionSts 7;
BA_ "FlexKomSID" SG_ 520 PsngrDoorAjarXtionSts 1943;
BA_ "GenSigStartValue" SG_ 520 PsngrDoorAjarXtionSts 3;
BA_ "FlexKomSigStartValue" SG_ 520 PsngrDoorAjarXtionSts "3FFF0C0000000000h";
BA_ "GenSigCycleTime" SG_ 520 PsngrDoorAjarXtionSts 20;
BA_ "GenSigSNA" SG_ 520 PsngrDoorAjarRawValSts "Fh";
BA_ "FlexKomIsMotorola" SG_ 520 PsngrDoorAjarRawValSts 1;
BA_ "FlexKomComment" SG_ 520 PsngrDoorAjarRawValSts "CBC_PT6 message packet";
BA_ "FlexKomSigName" SG_ 520 PsngrDoorAjarRawValSts "CBC_PT6_Pkt";
BA_ "FlexKomSigLaenge" SG_ 520 PsngrDoorAjarRawValSts 64;
BA_ "FlexKomSigStartPos" SG_ 520 PsngrDoorAjarRawValSts 7;
BA_ "FlexKomSID" SG_ 520 PsngrDoorAjarRawValSts 1943;
BA_ "GenSigTimeout_ORC" SG_ 520 PsngrDoorAjarRawValSts 70;
BA_ "FlexKomSigStartValue" SG_ 520 PsngrDoorAjarRawValSts "3FFF0C0000000000h";
BA_ "GenSigCycleTime" SG_ 520 PsngrDoorAjarRawValSts 20;
BA_ "GenSigCycleTime" SG_ 520 LeakCheckTimerExpired 20;
BA_ "FlexKomSigStartValue" SG_ 520 LeakCheckTimerExpired "3FFF0C0000000000h";
BA_ "FlexKomSID" SG_ 520 LeakCheckTimerExpired 1943;
BA_ "FlexKomSigStartPos" SG_ 520 LeakCheckTimerExpired 7;
BA_ "FlexKomSigLaenge" SG_ 520 LeakCheckTimerExpired 64;
BA_ "FlexKomSigName" SG_ 520 LeakCheckTimerExpired "CBC_PT6_Pkt";
BA_ "FlexKomComment" SG_ 520 LeakCheckTimerExpired "CBC_PT6 message packet";
BA_ "FlexKomIsMotorola" SG_ 520 LeakCheckTimerExpired 1;
BA_ "GenSigSNA" SG_ 520 LeakCheckTimerExpired "3h";
BA_ "GenSigSNA" SG_ 520 FuelDrRelSwRawSt "FFh";
BA_ "FlexKomIsMotorola" SG_ 520 FuelDrRelSwRawSt 1;
BA_ "FlexKomComment" SG_ 520 FuelDrRelSwRawSt "CBC_PT6 message packet";
BA_ "FlexKomSigName" SG_ 520 FuelDrRelSwRawSt "CBC_PT6_Pkt";
BA_ "FlexKomSigLaenge" SG_ 520 FuelDrRelSwRawSt 64;
BA_ "FlexKomSigStartPos" SG_ 520 FuelDrRelSwRawSt 7;
BA_ "FlexKomSID" SG_ 520 FuelDrRelSwRawSt 1943;
BA_ "FlexKomSigStartValue" SG_ 520 FuelDrRelSwRawSt "3FFF0C0000000000h";
BA_ "GenSigCycleTime" SG_ 520 FuelDrRelSwRawSt 20;
BA_ "GenSigSNA" SG_ 520 DriverDoorAjarXtionSts "3h";
BA_ "FlexKomIsMotorola" SG_ 520 DriverDoorAjarXtionSts 1;
BA_ "FlexKomComment" SG_ 520 DriverDoorAjarXtionSts "CBC_PT6 message packet";
BA_ "FlexKomSigName" SG_ 520 DriverDoorAjarXtionSts "CBC_PT6_Pkt";
BA_ "FlexKomSigLaenge" SG_ 520 DriverDoorAjarXtionSts 64;
BA_ "FlexKomSigStartPos" SG_ 520 DriverDoorAjarXtionSts 7;
BA_ "FlexKomSID" SG_ 520 DriverDoorAjarXtionSts 1943;
BA_ "GenSigStartValue" SG_ 520 DriverDoorAjarXtionSts 3;
BA_ "FlexKomSigStartValue" SG_ 520 DriverDoorAjarXtionSts "3FFF0C0000000000h";
BA_ "GenSigCycleTime" SG_ 520 DriverDoorAjarXtionSts 20;
BA_ "GenSigSNA" SG_ 520 DriverDoorAjarRawValSts "Fh";
BA_ "FlexKomIsMotorola" SG_ 520 DriverDoorAjarRawValSts 1;
BA_ "FlexKomComment" SG_ 520 DriverDoorAjarRawValSts "CBC_PT6 message packet";
BA_ "FlexKomSigName" SG_ 520 DriverDoorAjarRawValSts "CBC_PT6_Pkt";
BA_ "FlexKomSigLaenge" SG_ 520 DriverDoorAjarRawValSts 64;
BA_ "FlexKomSigStartPos" SG_ 520 DriverDoorAjarRawValSts 7;
BA_ "FlexKomSID" SG_ 520 DriverDoorAjarRawValSts 1943;
BA_ "GenSigTimeout_ORC" SG_ 520 DriverDoorAjarRawValSts 70;
BA_ "FlexKomSigStartValue" SG_ 520 DriverDoorAjarRawValSts "3FFF0C0000000000h";
BA_ "GenSigCycleTime" SG_ 520 DriverDoorAjarRawValSts 20;
BA_ "GenSigSNA" SG_ 520 DriverDoor2AjarXtionSts "3h";
BA_ "FlexKomIsMotorola" SG_ 520 DriverDoor2AjarXtionSts 1;
BA_ "FlexKomComment" SG_ 520 DriverDoor2AjarXtionSts "CBC_PT6 message packet";
BA_ "FlexKomSigName" SG_ 520 DriverDoor2AjarXtionSts "CBC_PT6_Pkt";
BA_ "FlexKomSigLaenge" SG_ 520 DriverDoor2AjarXtionSts 64;
BA_ "FlexKomSigStartPos" SG_ 520 DriverDoor2AjarXtionSts 7;
BA_ "FlexKomSID" SG_ 520 DriverDoor2AjarXtionSts 1943;
BA_ "GenSigStartValue" SG_ 520 DriverDoor2AjarXtionSts 3;
BA_ "FlexKomSigStartValue" SG_ 520 DriverDoor2AjarXtionSts "3FFF0C0000000000h";
BA_ "GenSigCycleTime" SG_ 520 DriverDoor2AjarXtionSts 20;
BA_ "GenSigSNA" SG_ 520 DriverDoor2AjarRawValSts "Fh";
BA_ "FlexKomIsMotorola" SG_ 520 DriverDoor2AjarRawValSts 1;
BA_ "FlexKomComment" SG_ 520 DriverDoor2AjarRawValSts "CBC_PT6 message packet";
BA_ "FlexKomSigName" SG_ 520 DriverDoor2AjarRawValSts "CBC_PT6_Pkt";
BA_ "FlexKomSigLaenge" SG_ 520 DriverDoor2AjarRawValSts 64;
BA_ "FlexKomSigStartPos" SG_ 520 DriverDoor2AjarRawValSts 7;
BA_ "FlexKomSID" SG_ 520 DriverDoor2AjarRawValSts 1943;
BA_ "FlexKomSigStartValue" SG_ 520 DriverDoor2AjarRawValSts "3FFF0C0000000000h";
BA_ "GenSigCycleTime" SG_ 520 DriverDoor2AjarRawValSts 20;
BA_ "GenSigSNA" SG_ 520 BrkPdlStat_CBC "3h";
BA_ "FlexKomIsMotorola" SG_ 520 BrkPdlStat_CBC 1;
BA_ "FlexKomComment" SG_ 520 BrkPdlStat_CBC "CBC_PT6 message packet";
BA_ "FlexKomSigName" SG_ 520 BrkPdlStat_CBC "CBC_PT6_Pkt";
BA_ "FlexKomSigLaenge" SG_ 520 BrkPdlStat_CBC 64;
BA_ "FlexKomSigStartPos" SG_ 520 BrkPdlStat_CBC 7;
BA_ "FlexKomSID" SG_ 520 BrkPdlStat_CBC 1943;
BA_ "GenSigTimeout_RF_HUB" SG_ 520 BrkPdlStat_CBC 210;
BA_ "GenSigStartValue" SG_ 520 BrkPdlStat_CBC 3;
BA_ "FlexKomSigStartValue" SG_ 520 BrkPdlStat_CBC "3FFF0C0000000000h";
BA_ "GenSigCycleTime" SG_ 520 BrkPdlStat_CBC 20;
BA_ "GenSigSNA" SG_ 520 BonnetAjarRawValSts "Fh";
BA_ "FlexKomIsMotorola" SG_ 520 BonnetAjarRawValSts 1;
BA_ "FlexKomComment" SG_ 520 BonnetAjarRawValSts "CBC_PT6 message packet";
BA_ "FlexKomSigName" SG_ 520 BonnetAjarRawValSts "CBC_PT6_Pkt";
BA_ "FlexKomSigLaenge" SG_ 520 BonnetAjarRawValSts 64;
BA_ "FlexKomSigStartPos" SG_ 520 BonnetAjarRawValSts 7;
BA_ "FlexKomSID" SG_ 520 BonnetAjarRawValSts 1943;
BA_ "GenSigTimeout_ORC" SG_ 520 BonnetAjarRawValSts 70;
BA_ "FlexKomSigStartValue" SG_ 520 BonnetAjarRawValSts "3FFF0C0000000000h";
BA_ "GenSigCycleTime" SG_ 520 BonnetAjarRawValSts 20;
BA_ "GenMsgStartValue" BO_ 514 "FFFFFFFF00000000h";
BA_ "GenMsgNrOfRepetitions" BO_ 514 2;
BA_ "GenMsgDelayTime" BO_ 514 20;
BA_ "GenMsgCycleTime" BO_ 514 10;
BA_ "GenSigSNA" SG_ 514 WheelRPM_FR "FFFFh";
BA_ "FlexKomIsMotorola" SG_ 514 WheelRPM_FR 1;
BA_ "FlexKomComment" SG_ 514 WheelRPM_FR "ESP wheel speed";
BA_ "FlexKomSigName" SG_ 514 WheelRPM_FR "WHEEL_SPEED2";
BA_ "FlexKomSigLaenge" SG_ 514 WheelRPM_FR 32;
BA_ "FlexKomSigStartPos" SG_ 514 WheelRPM_FR 7;
BA_ "FlexKomSID" SG_ 514 WheelRPM_FR 2103;
BA_ "GenSigTimeout_EPS" SG_ 514 WheelRPM_FR 105;
BA_ "GenSigStartValue" SG_ 514 WheelRPM_FR 65535;
BA_ "FlexKomSigStartValue" SG_ 514 WheelRPM_FR "FFFFFFFFh";
BA_ "GenSigCycleTime" SG_ 514 WheelRPM_FR 10;
BA_ "GenSigSNA" SG_ 514 WheelRPM_FL "FFFFh";
BA_ "FlexKomIsMotorola" SG_ 514 WheelRPM_FL 1;
BA_ "FlexKomComment" SG_ 514 WheelRPM_FL "ESP wheel speed";
BA_ "FlexKomSigName" SG_ 514 WheelRPM_FL "WHEEL_SPEED2";
BA_ "FlexKomSigLaenge" SG_ 514 WheelRPM_FL 32;
BA_ "FlexKomSigStartPos" SG_ 514 WheelRPM_FL 7;
BA_ "FlexKomSID" SG_ 514 WheelRPM_FL 2103;
BA_ "GenSigTimeout_EPS" SG_ 514 WheelRPM_FL 105;
BA_ "GenSigStartValue" SG_ 514 WheelRPM_FL 65535;
BA_ "FlexKomSigStartValue" SG_ 514 WheelRPM_FL "FFFFFFFFh";
BA_ "GenSigCycleTime" SG_ 514 WheelRPM_FL 10;
BA_ "GenMsgStartValue" BO_ 512 "FFFFFFFFFFFFFFFFh";
BA_ "GenMsgNrOfRepetitions" BO_ 512 2;
BA_ "GenMsgDelayTime" BO_ 512 20;
BA_ "GenMsgCycleTime" BO_ 512 100;
BA_ "FlexKomComment" SG_ 512 FUEL_VOLT2 "Sub Side Fuel level sensor A/D Voltage (saddle/Dua";
BA_ "GenSigCycleTime" SG_ 512 FUEL_VOLT2 100;
BA_ "FlexKomSigStartValue" SG_ 512 FUEL_VOLT2 "FFh";
BA_ "GenSigStartValue" SG_ 512 FUEL_VOLT2 255;
BA_ "GenSigTimeout_IC" SG_ 512 FUEL_VOLT2 1050;
BA_ "FlexKomSID" SG_ 512 FUEL_VOLT2 882;
BA_ "FlexKomSigStartPos" SG_ 512 FUEL_VOLT2 47;
BA_ "FlexKomSigLaenge" SG_ 512 FUEL_VOLT2 8;
BA_ "FlexKomSigName" SG_ 512 FUEL_VOLT2 "FUEL_VOLT2";
BA_ "FlexKomIsMotorola" SG_ 512 FUEL_VOLT2 1;
BA_ "GenSigSNA" SG_ 512 FUEL_VOLT2 "FFh";
BA_ "GenSigSNA" SG_ 512 FUEL_VOLT "FFh";
BA_ "FlexKomIsMotorola" SG_ 512 FUEL_VOLT 1;
BA_ "FlexKomComment" SG_ 512 FUEL_VOLT "Fuel level A/D Voltage (Single tank OR Primary on ";
BA_ "FlexKomSigName" SG_ 512 FUEL_VOLT "FUEL_VOLT";
BA_ "FlexKomSigLaenge" SG_ 512 FUEL_VOLT 8;
BA_ "FlexKomSigStartPos" SG_ 512 FUEL_VOLT 39;
BA_ "FlexKomSID" SG_ 512 FUEL_VOLT 881;
BA_ "GenSigTimeout_IC" SG_ 512 FUEL_VOLT 1050;
BA_ "GenSigStartValue" SG_ 512 FUEL_VOLT 255;
BA_ "FlexKomSigStartValue" SG_ 512 FUEL_VOLT "FFh";
BA_ "GenSigCycleTime" SG_ 512 FUEL_VOLT 100;
BA_ "GenSigSNA" SG_ 512 BATT_VOLT "FFh";
BA_ "FlexKomIsMotorola" SG_ 512 BATT_VOLT 1;
BA_ "FlexKomComment" SG_ 512 BATT_VOLT "System voltage";
BA_ "FlexKomSigName" SG_ 512 BATT_VOLT "BATT_VOLT";
BA_ "FlexKomSigLaenge" SG_ 512 BATT_VOLT 8;
BA_ "FlexKomSigStartPos" SG_ 512 BATT_VOLT 55;
BA_ "FlexKomSID" SG_ 512 BATT_VOLT 839;
BA_ "GenSigTimeout_ORC" SG_ 512 BATT_VOLT 350;
BA_ "GenSigTimeout_ESM" SG_ 512 BATT_VOLT 1050;
BA_ "GenSigTimeout_SCCM" SG_ 512 BATT_VOLT 1050;
BA_ "GenSigTimeout_EPS" SG_ 512 BATT_VOLT 1050;
BA_ "GenSigTimeout_IC" SG_ 512 BATT_VOLT 1050;
BA_ "GenSigTimeout_RF_HUB" SG_ 512 BATT_VOLT 1050;
BA_ "GenSigStartValue" SG_ 512 BATT_VOLT 255;
BA_ "FlexKomSigStartValue" SG_ 512 BATT_VOLT "FFh";
BA_ "GenSigCycleTime" SG_ 512 BATT_VOLT 100;
BA_ "GenSigSNA" SG_ 512 AMB_TEMP_VOLT "FFh";
BA_ "FlexKomIsMotorola" SG_ 512 AMB_TEMP_VOLT 1;
BA_ "FlexKomComment" SG_ 512 AMB_TEMP_VOLT "Ambient Temp Sensor A/D Voltage";
BA_ "FlexKomSigName" SG_ 512 AMB_TEMP_VOLT "AMB_TEMP_VOLT";
BA_ "FlexKomSigLaenge" SG_ 512 AMB_TEMP_VOLT 8;
BA_ "FlexKomSigStartPos" SG_ 512 AMB_TEMP_VOLT 31;
BA_ "FlexKomSID" SG_ 512 AMB_TEMP_VOLT 1201;
BA_ "GenSigTimeout_ORC" SG_ 512 AMB_TEMP_VOLT 350;
BA_ "GenSigStartValue" SG_ 512 AMB_TEMP_VOLT 255;
BA_ "FlexKomSigStartValue" SG_ 512 AMB_TEMP_VOLT "FFh";
BA_ "GenSigCycleTime" SG_ 512 AMB_TEMP_VOLT 100;
BA_ "GenSigSNA" SG_ 512 AMB_TEMP_AVG "FFFFh";
BA_ "FlexKomIsMotorola" SG_ 512 AMB_TEMP_AVG 1;
BA_ "FlexKomComment" SG_ 512 AMB_TEMP_AVG "Averaged ambient temperature";
BA_ "FlexKomSigName" SG_ 512 AMB_TEMP_AVG "AMB_TEMP_AVG";
BA_ "FlexKomSigLaenge" SG_ 512 AMB_TEMP_AVG 16;
BA_ "FlexKomSigStartPos" SG_ 512 AMB_TEMP_AVG 15;
BA_ "FlexKomSID" SG_ 512 AMB_TEMP_AVG 840;
BA_ "GenSigTimeout_ORC" SG_ 512 AMB_TEMP_AVG 350;
BA_ "GenSigTimeout_IC" SG_ 512 AMB_TEMP_AVG 1050;
BA_ "GenSigTimeout_RF_HUB" SG_ 512 AMB_TEMP_AVG 1050;
BA_ "GenSigStartValue" SG_ 512 AMB_TEMP_AVG 65535;
BA_ "FlexKomSigStartValue" SG_ 512 AMB_TEMP_AVG "FFFFh";
BA_ "GenSigCycleTime" SG_ 512 AMB_TEMP_AVG 100;
BA_ "GenSigSNA" SG_ 512 AirTemp_Outsd "FFh";
BA_ "FlexKomIsMotorola" SG_ 512 AirTemp_Outsd 1;
BA_ "FlexKomComment" SG_ 512 AirTemp_Outsd "Outside air temperature";
BA_ "FlexKomSigName" SG_ 512 AirTemp_Outsd "AirTemp_Outsd";
BA_ "FlexKomSigLaenge" SG_ 512 AirTemp_Outsd 8;
BA_ "FlexKomSigStartPos" SG_ 512 AirTemp_Outsd 7;
BA_ "FlexKomSID" SG_ 512 AirTemp_Outsd 773;
BA_ "GenSigTimeout_ORC" SG_ 512 AirTemp_Outsd 350;
BA_ "GenSigTimeout_IC" SG_ 512 AirTemp_Outsd 1050;
BA_ "GenSigTimeout_RF_HUB" SG_ 512 AirTemp_Outsd 1050;
BA_ "GenSigStartValue" SG_ 512 AirTemp_Outsd 255;
BA_ "FlexKomSigStartValue" SG_ 512 AirTemp_Outsd "FFh";
BA_ "GenSigCycleTime" SG_ 512 AirTemp_Outsd 100;
BA_ "GenMsgStartValue" BO_ 501 "00FFFF00000000FFh";
BA_ "GenMsgNrOfRepetitions" BO_ 501 2;
BA_ "GenMsgDelayTime" BO_ 501 20;
BA_ "GenMsgCycleTime" BO_ 501 60;
BA_ "GenSigSNA" SG_ 501 Sm_ICON_Dspl "3Fh";
BA_ "FlexKomIsMotorola" SG_ 501 Sm_ICON_Dspl 1;
BA_ "FlexKomComment" SG_ 501 Sm_ICON_Dspl "DAS_A4 Packet";
BA_ "FlexKomSigName" SG_ 501 Sm_ICON_Dspl "DAS_A4_PKT";
BA_ "FlexKomSigLaenge" SG_ 501 Sm_ICON_Dspl 64;
BA_ "FlexKomSigStartPos" SG_ 501 Sm_ICON_Dspl 7;
BA_ "FlexKomSID" SG_ 501 Sm_ICON_Dspl 1717;
BA_ "GenSigTimeout_IC" SG_ 501 Sm_ICON_Dspl 630;
BA_ "FlexKomSigStartValue" SG_ 501 Sm_ICON_Dspl "00FFFF00000000FFh";
BA_ "GenSigCycleTime" SG_ 501 Sm_ICON_Dspl 60;
BA_ "GenSigSNA" SG_ 501 SetSpeed_MPH "FFh";
BA_ "FlexKomIsMotorola" SG_ 501 SetSpeed_MPH 1;
BA_ "FlexKomComment" SG_ 501 SetSpeed_MPH "DAS_A4 Packet";
BA_ "FlexKomSigName" SG_ 501 SetSpeed_MPH "DAS_A4_PKT";
BA_ "FlexKomSigLaenge" SG_ 501 SetSpeed_MPH 64;
BA_ "FlexKomSigStartPos" SG_ 501 SetSpeed_MPH 7;
BA_ "FlexKomSID" SG_ 501 SetSpeed_MPH 1717;
BA_ "GenSigTimeout_ORC" SG_ 501 SetSpeed_MPH 210;
BA_ "GenSigTimeout_IC" SG_ 501 SetSpeed_MPH 630;
BA_ "GenSigStartValue" SG_ 501 SetSpeed_MPH 255;
BA_ "FlexKomSigStartValue" SG_ 501 SetSpeed_MPH "00FFFF00000000FFh";
BA_ "GenSigCycleTime" SG_ 501 SetSpeed_MPH 60;
BA_ "GenSigSNA" SG_ 501 SetSpeed_KPH "FFh";
BA_ "FlexKomIsMotorola" SG_ 501 SetSpeed_KPH 1;
BA_ "FlexKomComment" SG_ 501 SetSpeed_KPH "DAS_A4 Packet";
BA_ "FlexKomSigName" SG_ 501 SetSpeed_KPH "DAS_A4_PKT";
BA_ "FlexKomSigLaenge" SG_ 501 SetSpeed_KPH 64;
BA_ "FlexKomSigStartPos" SG_ 501 SetSpeed_KPH 7;
BA_ "FlexKomSID" SG_ 501 SetSpeed_KPH 1717;
BA_ "GenSigTimeout_IC" SG_ 501 SetSpeed_KPH 630;
BA_ "GenSigStartValue" SG_ 501 SetSpeed_KPH 255;
BA_ "FlexKomSigStartValue" SG_ 501 SetSpeed_KPH "00FFFF00000000FFh";
BA_ "GenSigCycleTime" SG_ 501 SetSpeed_KPH 60;
BA_ "GenSigSNA" SG_ 501 RadarBlocked "0h";
BA_ "FlexKomIsMotorola" SG_ 501 RadarBlocked 1;
BA_ "FlexKomComment" SG_ 501 RadarBlocked "DAS_A4 Packet";
BA_ "FlexKomSigName" SG_ 501 RadarBlocked "DAS_A4_PKT";
BA_ "FlexKomSigLaenge" SG_ 501 RadarBlocked 64;
BA_ "FlexKomSigStartPos" SG_ 501 RadarBlocked 7;
BA_ "FlexKomSID" SG_ 501 RadarBlocked 1717;
BA_ "GenSigTimeout_ORC" SG_ 501 RadarBlocked 210;
BA_ "GenSigTimeout_IC" SG_ 501 RadarBlocked 630;
BA_ "FlexKomSigStartValue" SG_ 501 RadarBlocked "00FFFF00000000FFh";
BA_ "GenSigCycleTime" SG_ 501 RadarBlocked 60;
BA_ "GenSigSNA" SG_ 501 ObjIntrstDist "FFh";
BA_ "FlexKomIsMotorola" SG_ 501 ObjIntrstDist 1;
BA_ "FlexKomComment" SG_ 501 ObjIntrstDist "DAS_A4 Packet";
BA_ "FlexKomSigName" SG_ 501 ObjIntrstDist "DAS_A4_PKT";
BA_ "FlexKomSigLaenge" SG_ 501 ObjIntrstDist 64;
BA_ "FlexKomSigStartPos" SG_ 501 ObjIntrstDist 7;
BA_ "FlexKomSID" SG_ 501 ObjIntrstDist 1717;
BA_ "GenSigTimeout_ORC" SG_ 501 ObjIntrstDist 210;
BA_ "GenSigStartValue" SG_ 501 ObjIntrstDist 255;
BA_ "FlexKomSigStartValue" SG_ 501 ObjIntrstDist "00FFFF00000000FFh";
BA_ "GenSigCycleTime" SG_ 501 ObjIntrstDist 60;
BA_ "GenSigSNA" SG_ 501 NCConlyNA_DASMSts "0h";
BA_ "FlexKomIsMotorola" SG_ 501 NCConlyNA_DASMSts 1;
BA_ "FlexKomComment" SG_ 501 NCConlyNA_DASMSts "DAS_A4 Packet";
BA_ "FlexKomSigName" SG_ 501 NCConlyNA_DASMSts "DAS_A4_PKT";
BA_ "FlexKomSigLaenge" SG_ 501 NCConlyNA_DASMSts 64;
BA_ "FlexKomSigStartPos" SG_ 501 NCConlyNA_DASMSts 7;
BA_ "FlexKomSID" SG_ 501 NCConlyNA_DASMSts 1717;
BA_ "GenSigTimeout_IC" SG_ 501 NCConlyNA_DASMSts 630;
BA_ "FlexKomSigStartValue" SG_ 501 NCConlyNA_DASMSts "00FFFF00000000FFh";
BA_ "GenSigCycleTime" SG_ 501 NCConlyNA_DASMSts 60;
BA_ "GenSigSNA" SG_ 501 NCCNA_DASMSts "0h";
BA_ "FlexKomIsMotorola" SG_ 501 NCCNA_DASMSts 1;
BA_ "FlexKomComment" SG_ 501 NCCNA_DASMSts "DAS_A4 Packet";
BA_ "FlexKomSigName" SG_ 501 NCCNA_DASMSts "DAS_A4_PKT";
BA_ "FlexKomSigLaenge" SG_ 501 NCCNA_DASMSts 64;
BA_ "FlexKomSigStartPos" SG_ 501 NCCNA_DASMSts 7;
BA_ "FlexKomSID" SG_ 501 NCCNA_DASMSts 1717;
BA_ "GenSigTimeout_ORC" SG_ 501 NCCNA_DASMSts 210;
BA_ "GenSigTimeout_IC" SG_ 501 NCCNA_DASMSts 630;
BA_ "FlexKomSigStartValue" SG_ 501 NCCNA_DASMSts "00FFFF00000000FFh";
BA_ "GenSigCycleTime" SG_ 501 NCCNA_DASMSts 60;
BA_ "GenSigSNA" SG_ 501 HMI_Screens "FFh";
BA_ "FlexKomIsMotorola" SG_ 501 HMI_Screens 1;
BA_ "FlexKomComment" SG_ 501 HMI_Screens "DAS_A4 Packet";
BA_ "FlexKomSigName" SG_ 501 HMI_Screens "DAS_A4_PKT";
BA_ "FlexKomSigLaenge" SG_ 501 HMI_Screens 64;
BA_ "FlexKomSigStartPos" SG_ 501 HMI_Screens 7;
BA_ "FlexKomSID" SG_ 501 HMI_Screens 1717;
BA_ "GenSigTimeout_ORC" SG_ 501 HMI_Screens 210;
BA_ "GenSigTimeout_IC" SG_ 501 HMI_Screens 630;
BA_ "FlexKomSigStartValue" SG_ 501 HMI_Screens "00FFFF00000000FFh";
BA_ "GenSigCycleTime" SG_ 501 HMI_Screens 60;
BA_ "GenSigSNA" SG_ 501 FCWonlyNA_DASMSts "0h";
BA_ "FlexKomIsMotorola" SG_ 501 FCWonlyNA_DASMSts 1;
BA_ "FlexKomComment" SG_ 501 FCWonlyNA_DASMSts "DAS_A4 Packet";
BA_ "FlexKomSigName" SG_ 501 FCWonlyNA_DASMSts "DAS_A4_PKT";
BA_ "FlexKomSigLaenge" SG_ 501 FCWonlyNA_DASMSts 64;
BA_ "FlexKomSigStartPos" SG_ 501 FCWonlyNA_DASMSts 7;
BA_ "FlexKomSID" SG_ 501 FCWonlyNA_DASMSts 1717;
BA_ "FlexKomSigStartValue" SG_ 501 FCWonlyNA_DASMSts "00FFFF00000000FFh";
BA_ "GenSigCycleTime" SG_ 501 FCWonlyNA_DASMSts 60;
BA_ "GenSigSNA" SG_ 501 FCWBrakingOff "0h";
BA_ "FlexKomIsMotorola" SG_ 501 FCWBrakingOff 1;
BA_ "FlexKomComment" SG_ 501 FCWBrakingOff "DAS_A4 Packet";
BA_ "FlexKomSigName" SG_ 501 FCWBrakingOff "DAS_A4_PKT";
BA_ "FlexKomSigLaenge" SG_ 501 FCWBrakingOff 64;
BA_ "FlexKomSigStartPos" SG_ 501 FCWBrakingOff 7;
BA_ "FlexKomSID" SG_ 501 FCWBrakingOff 1717;
BA_ "GenSigTimeout_ORC" SG_ 501 FCWBrakingOff 210;
BA_ "GenSigTimeout_IC" SG_ 501 FCWBrakingOff 630;
BA_ "FlexKomSigStartValue" SG_ 501 FCWBrakingOff "00FFFF00000000FFh";
BA_ "GenSigCycleTime" SG_ 501 FCWBrakingOff 60;
BA_ "GenSigSNA" SG_ 501 FCW_Error "3h";
BA_ "FlexKomIsMotorola" SG_ 501 FCW_Error 1;
BA_ "FlexKomComment" SG_ 501 FCW_Error "DAS_A4 Packet";
BA_ "FlexKomSigName" SG_ 501 FCW_Error "DAS_A4_PKT";
BA_ "FlexKomSigLaenge" SG_ 501 FCW_Error 64;
BA_ "FlexKomSigStartPos" SG_ 501 FCW_Error 7;
BA_ "FlexKomSID" SG_ 501 FCW_Error 1717;
BA_ "GenSigTimeout_ORC" SG_ 501 FCW_Error 210;
BA_ "GenSigTimeout_IC" SG_ 501 FCW_Error 630;
BA_ "FlexKomSigStartValue" SG_ 501 FCW_Error "00FFFF00000000FFh";
BA_ "GenSigCycleTime" SG_ 501 FCW_Error 60;
BA_ "GenSigSNA" SG_ 501 FCW_BrkOn "0h";
BA_ "FlexKomIsMotorola" SG_ 501 FCW_BrkOn 1;
BA_ "FlexKomComment" SG_ 501 FCW_BrkOn "DAS_A4 Packet";
BA_ "FlexKomSigName" SG_ 501 FCW_BrkOn "DAS_A4_PKT";
BA_ "FlexKomSigLaenge" SG_ 501 FCW_BrkOn 64;
BA_ "FlexKomSigStartPos" SG_ 501 FCW_BrkOn 7;
BA_ "FlexKomSID" SG_ 501 FCW_BrkOn 1717;
BA_ "GenSigTimeout_ORC" SG_ 501 FCW_BrkOn 210;
BA_ "GenSigTimeout_IC" SG_ 501 FCW_BrkOn 630;
BA_ "GenSigTimeout_CBC" SG_ 501 FCW_BrkOn 630;
BA_ "FlexKomSigStartValue" SG_ 501 FCW_BrkOn "00FFFF00000000FFh";
BA_ "GenSigCycleTime" SG_ 501 FCW_BrkOn 60;
BA_ "GenSigSNA" SG_ 501 CIPV_Fused "0h";
BA_ "FlexKomIsMotorola" SG_ 501 CIPV_Fused 1;
BA_ "FlexKomComment" SG_ 501 CIPV_Fused "DAS_A4 Packet";
BA_ "FlexKomSigName" SG_ 501 CIPV_Fused "DAS_A4_PKT";
BA_ "FlexKomSigLaenge" SG_ 501 CIPV_Fused 64;
BA_ "FlexKomSigStartPos" SG_ 501 CIPV_Fused 7;
BA_ "FlexKomSID" SG_ 501 CIPV_Fused 1717;
BA_ "GenSigTimeout_ORC" SG_ 501 CIPV_Fused 210;
BA_ "FlexKomSigStartValue" SG_ 501 CIPV_Fused "00FFFF00000000FFh";
BA_ "GenSigCycleTime" SG_ 501 CIPV_Fused 60;
BA_ "GenSigSNA" SG_ 501 CameraFailure "0h";
BA_ "FlexKomIsMotorola" SG_ 501 CameraFailure 1;
BA_ "FlexKomComment" SG_ 501 CameraFailure "DAS_A4 Packet";
BA_ "FlexKomSigName" SG_ 501 CameraFailure "DAS_A4_PKT";
BA_ "FlexKomSigLaenge" SG_ 501 CameraFailure 64;
BA_ "FlexKomSigStartPos" SG_ 501 CameraFailure 7;
BA_ "FlexKomSID" SG_ 501 CameraFailure 1717;
BA_ "GenSigTimeout_ORC" SG_ 501 CameraFailure 210;
BA_ "GenSigTimeout_IC" SG_ 501 CameraFailure 630;
BA_ "FlexKomSigStartValue" SG_ 501 CameraFailure "00FFFF00000000FFh";
BA_ "GenSigCycleTime" SG_ 501 CameraFailure 60;
BA_ "GenSigSNA" SG_ 501 CameraBlocked "0h";
BA_ "FlexKomIsMotorola" SG_ 501 CameraBlocked 1;
BA_ "FlexKomComment" SG_ 501 CameraBlocked "DAS_A4 Packet";
BA_ "FlexKomSigName" SG_ 501 CameraBlocked "DAS_A4_PKT";
BA_ "FlexKomSigLaenge" SG_ 501 CameraBlocked 64;
BA_ "FlexKomSigStartPos" SG_ 501 CameraBlocked 7;
BA_ "FlexKomSID" SG_ 501 CameraBlocked 1717;
BA_ "GenSigTimeout_ORC" SG_ 501 CameraBlocked 210;
BA_ "GenSigTimeout_IC" SG_ 501 CameraBlocked 630;
BA_ "FlexKomSigStartValue" SG_ 501 CameraBlocked "00FFFF00000000FFh";
BA_ "GenSigCycleTime" SG_ 501 CameraBlocked 60;
BA_ "GenSigSNA" SG_ 501 ACCOnOff "7h";
BA_ "FlexKomIsMotorola" SG_ 501 ACCOnOff 1;
BA_ "FlexKomComment" SG_ 501 ACCOnOff "DAS_A4 Packet";
BA_ "FlexKomSigName" SG_ 501 ACCOnOff "DAS_A4_PKT";
BA_ "FlexKomSigLaenge" SG_ 501 ACCOnOff 64;
BA_ "FlexKomSigStartPos" SG_ 501 ACCOnOff 7;
BA_ "FlexKomSID" SG_ 501 ACCOnOff 1717;
BA_ "GenSigTimeout_ORC" SG_ 501 ACCOnOff 210;
BA_ "GenSigTimeout_IC" SG_ 501 ACCOnOff 630;
BA_ "FlexKomSigStartValue" SG_ 501 ACCOnOff "00FFFF00000000FFh";
BA_ "GenSigCycleTime" SG_ 501 ACCOnOff 60;
BA_ "GenSigSNA" SG_ 501 ACConlyNA_DASMSts "0h";
BA_ "FlexKomIsMotorola" SG_ 501 ACConlyNA_DASMSts 1;
BA_ "FlexKomComment" SG_ 501 ACConlyNA_DASMSts "DAS_A4 Packet";
BA_ "FlexKomSigName" SG_ 501 ACConlyNA_DASMSts "DAS_A4_PKT";
BA_ "FlexKomSigLaenge" SG_ 501 ACConlyNA_DASMSts 64;
BA_ "FlexKomSigStartPos" SG_ 501 ACConlyNA_DASMSts 7;
BA_ "FlexKomSID" SG_ 501 ACConlyNA_DASMSts 1717;
BA_ "GenSigTimeout_IC" SG_ 501 ACConlyNA_DASMSts 630;
BA_ "FlexKomSigStartValue" SG_ 501 ACConlyNA_DASMSts "00FFFF00000000FFh";
BA_ "GenSigCycleTime" SG_ 501 ACConlyNA_DASMSts 60;
BA_ "GenSigSNA" SG_ 501 ACCNA_DASMSts "0h";
BA_ "FlexKomIsMotorola" SG_ 501 ACCNA_DASMSts 1;
BA_ "FlexKomComment" SG_ 501 ACCNA_DASMSts "DAS_A4 Packet";
BA_ "FlexKomSigName" SG_ 501 ACCNA_DASMSts "DAS_A4_PKT";
BA_ "FlexKomSigLaenge" SG_ 501 ACCNA_DASMSts 64;
BA_ "FlexKomSigStartPos" SG_ 501 ACCNA_DASMSts 7;
BA_ "FlexKomSID" SG_ 501 ACCNA_DASMSts 1717;
BA_ "GenSigTimeout_ORC" SG_ 501 ACCNA_DASMSts 210;
BA_ "GenSigTimeout_IC" SG_ 501 ACCNA_DASMSts 630;
BA_ "FlexKomSigStartValue" SG_ 501 ACCNA_DASMSts "00FFFF00000000FFh";
BA_ "GenSigCycleTime" SG_ 501 ACCNA_DASMSts 60;
BA_ "GenSigSNA" SG_ 501 ACCFaulted "0h";
BA_ "FlexKomIsMotorola" SG_ 501 ACCFaulted 1;
BA_ "FlexKomComment" SG_ 501 ACCFaulted "DAS_A4 Packet";
BA_ "FlexKomSigName" SG_ 501 ACCFaulted "DAS_A4_PKT";
BA_ "FlexKomSigLaenge" SG_ 501 ACCFaulted 64;
BA_ "FlexKomSigStartPos" SG_ 501 ACCFaulted 7;
BA_ "FlexKomSID" SG_ 501 ACCFaulted 1717;
BA_ "GenSigTimeout_ORC" SG_ 501 ACCFaulted 210;
BA_ "GenSigTimeout_IC" SG_ 501 ACCFaulted 630;
BA_ "FlexKomSigStartValue" SG_ 501 ACCFaulted "00FFFF00000000FFh";
BA_ "GenSigCycleTime" SG_ 501 ACCFaulted 60;
BA_ "GenSigSNA" SG_ 501 ACC_HMI_SCRN_REQ "0h";
BA_ "FlexKomIsMotorola" SG_ 501 ACC_HMI_SCRN_REQ 1;
BA_ "FlexKomComment" SG_ 501 ACC_HMI_SCRN_REQ "DAS_A4 Packet";
BA_ "FlexKomSigName" SG_ 501 ACC_HMI_SCRN_REQ "DAS_A4_PKT";
BA_ "FlexKomSigLaenge" SG_ 501 ACC_HMI_SCRN_REQ 64;
BA_ "FlexKomSigStartPos" SG_ 501 ACC_HMI_SCRN_REQ 7;
BA_ "FlexKomSID" SG_ 501 ACC_HMI_SCRN_REQ 1717;
BA_ "GenSigTimeout_IC" SG_ 501 ACC_HMI_SCRN_REQ 630;
BA_ "FlexKomSigStartValue" SG_ 501 ACC_HMI_SCRN_REQ "00FFFF00000000FFh";
BA_ "GenSigCycleTime" SG_ 501 ACC_HMI_SCRN_REQ 60;
BA_ "GenMsgStartValue" BO_ 500 "1FFF0CCB000000FFh";
BA_ "GenMsgNrOfRepetitions" BO_ 500 2;
BA_ "GenMsgDelayTime" BO_ 500 20;
BA_ "GenMsgCycleTime" BO_ 500 20;
BA_ "GenSigSNA" SG_ 500 MC_DAS_A3 "0h";
BA_ "FlexKomIsMotorola" SG_ 500 MC_DAS_A3 1;
BA_ "FlexKomComment" SG_ 500 MC_DAS_A3 "DAS_A3_PKT";
BA_ "FlexKomSigName" SG_ 500 MC_DAS_A3 "DAS_A3_PKT";
BA_ "FlexKomSigLaenge" SG_ 500 MC_DAS_A3 64;
BA_ "FlexKomSigStartPos" SG_ 500 MC_DAS_A3 7;
BA_ "FlexKomSID" SG_ 500 MC_DAS_A3 1043;
BA_ "FlexKomSigStartValue" SG_ 500 MC_DAS_A3 "1FFF0CCB000000FFh";
BA_ "GenSigCycleTime" SG_ 500 MC_DAS_A3 20;
BA_ "GenSigSNA" SG_ 500 DsblFuelShutOff_ACC "0h";
BA_ "FlexKomIsMotorola" SG_ 500 DsblFuelShutOff_ACC 1;
BA_ "FlexKomComment" SG_ 500 DsblFuelShutOff_ACC "DAS_A3_PKT";
BA_ "FlexKomSigName" SG_ 500 DsblFuelShutOff_ACC "DAS_A3_PKT";
BA_ "FlexKomSigLaenge" SG_ 500 DsblFuelShutOff_ACC 64;
BA_ "FlexKomSigStartPos" SG_ 500 DsblFuelShutOff_ACC 7;
BA_ "FlexKomSID" SG_ 500 DsblFuelShutOff_ACC 1043;
BA_ "FlexKomSigStartValue" SG_ 500 DsblFuelShutOff_ACC "1FFF0CCB000000FFh";
BA_ "GenSigCycleTime" SG_ 500 DsblFuelShutOff_ACC 20;
BA_ "GenSigSNA" SG_ 500 DAS_Sts "3h";
BA_ "FlexKomIsMotorola" SG_ 500 DAS_Sts 1;
BA_ "FlexKomComment" SG_ 500 DAS_Sts "DAS_A3_PKT";
BA_ "FlexKomSigName" SG_ 500 DAS_Sts "DAS_A3_PKT";
BA_ "FlexKomSigLaenge" SG_ 500 DAS_Sts 64;
BA_ "FlexKomSigStartPos" SG_ 500 DAS_Sts 7;
BA_ "FlexKomSID" SG_ 500 DAS_Sts 1043;
BA_ "FlexKomSigStartValue" SG_ 500 DAS_Sts "1FFF0CCB000000FFh";
BA_ "GenSigCycleTime" SG_ 500 DAS_Sts 20;
BA_ "GenSigSNA" SG_ 500 DAS_Rq_ID "7h";
BA_ "FlexKomIsMotorola" SG_ 500 DAS_Rq_ID 1;
BA_ "FlexKomComment" SG_ 500 DAS_Rq_ID "DAS_A3_PKT";
BA_ "FlexKomSigName" SG_ 500 DAS_Rq_ID "DAS_A3_PKT";
BA_ "FlexKomSigLaenge" SG_ 500 DAS_Rq_ID 64;
BA_ "FlexKomSigStartPos" SG_ 500 DAS_Rq_ID 7;
BA_ "FlexKomSID" SG_ 500 DAS_Rq_ID 1043;
BA_ "GenSigTimeout_ORC" SG_ 500 DAS_Rq_ID 70;
BA_ "FlexKomSigStartValue" SG_ 500 DAS_Rq_ID "1FFF0CCB000000FFh";
BA_ "GenSigCycleTime" SG_ 500 DAS_Rq_ID 20;
BA_ "GenSigSNA" SG_ 500 DAS_ACCEL_Rq "FFFh";
BA_ "FlexKomIsMotorola" SG_ 500 DAS_ACCEL_Rq 1;
BA_ "FlexKomComment" SG_ 500 DAS_ACCEL_Rq "DAS_A3_PKT";
BA_ "FlexKomSigName" SG_ 500 DAS_ACCEL_Rq "DAS_A3_PKT";
BA_ "FlexKomSigLaenge" SG_ 500 DAS_ACCEL_Rq 64;
BA_ "FlexKomSigStartPos" SG_ 500 DAS_ACCEL_Rq 7;
BA_ "FlexKomSID" SG_ 500 DAS_ACCEL_Rq 1043;
BA_ "GenSigTimeout_ORC" SG_ 500 DAS_ACCEL_Rq 70;
BA_ "GenSigStartValue" SG_ 500 DAS_ACCEL_Rq 3275;
BA_ "FlexKomSigStartValue" SG_ 500 DAS_ACCEL_Rq "1FFF0CCB000000FFh";
BA_ "GenSigCycleTime" SG_ 500 DAS_ACCEL_Rq 20;
BA_ "GenSigSNA" SG_ 500 CRC_DAS_A3 "FFh";
BA_ "FlexKomIsMotorola" SG_ 500 CRC_DAS_A3 1;
BA_ "FlexKomComment" SG_ 500 CRC_DAS_A3 "DAS_A3_PKT";
BA_ "FlexKomSigName" SG_ 500 CRC_DAS_A3 "DAS_A3_PKT";
BA_ "FlexKomSigLaenge" SG_ 500 CRC_DAS_A3 64;
BA_ "FlexKomSigStartPos" SG_ 500 CRC_DAS_A3 7;
BA_ "FlexKomSID" SG_ 500 CRC_DAS_A3 1043;
BA_ "GenSigStartValue" SG_ 500 CRC_DAS_A3 255;
BA_ "FlexKomSigStartValue" SG_ 500 CRC_DAS_A3 "1FFF0CCB000000FFh";
BA_ "GenSigCycleTime" SG_ 500 CRC_DAS_A3 20;
BA_ "GenSigSNA" SG_ 500 Brk_PreFill_Rq "0h";
BA_ "FlexKomIsMotorola" SG_ 500 Brk_PreFill_Rq 1;
BA_ "FlexKomComment" SG_ 500 Brk_PreFill_Rq "DAS_A3_PKT";
BA_ "FlexKomSigName" SG_ 500 Brk_PreFill_Rq "DAS_A3_PKT";
BA_ "FlexKomSigLaenge" SG_ 500 Brk_PreFill_Rq 64;
BA_ "FlexKomSigStartPos" SG_ 500 Brk_PreFill_Rq 7;
BA_ "FlexKomSID" SG_ 500 Brk_PreFill_Rq 1043;
BA_ "GenSigTimeout_ORC" SG_ 500 Brk_PreFill_Rq 70;
BA_ "FlexKomSigStartValue" SG_ 500 Brk_PreFill_Rq "1FFF0CCB000000FFh";
BA_ "GenSigCycleTime" SG_ 500 Brk_PreFill_Rq 20;
BA_ "GenSigSNA" SG_ 500 Brk_Jrk_Rq "0h";
BA_ "FlexKomIsMotorola" SG_ 500 Brk_Jrk_Rq 1;
BA_ "FlexKomComment" SG_ 500 Brk_Jrk_Rq "DAS_A3_PKT";
BA_ "FlexKomSigName" SG_ 500 Brk_Jrk_Rq "DAS_A3_PKT";
BA_ "FlexKomSigLaenge" SG_ 500 Brk_Jrk_Rq 64;
BA_ "FlexKomSigStartPos" SG_ 500 Brk_Jrk_Rq 7;
BA_ "FlexKomSID" SG_ 500 Brk_Jrk_Rq 1043;
BA_ "FlexKomSigStartValue" SG_ 500 Brk_Jrk_Rq "1FFF0CCB000000FFh";
BA_ "GenSigCycleTime" SG_ 500 Brk_Jrk_Rq 20;
BA_ "GenSigSNA" SG_ 500 As_DispRq "3h";
BA_ "FlexKomIsMotorola" SG_ 500 As_DispRq 1;
BA_ "FlexKomComment" SG_ 500 As_DispRq "DAS_A3_PKT";
BA_ "FlexKomSigName" SG_ 500 As_DispRq "DAS_A3_PKT";
BA_ "FlexKomSigLaenge" SG_ 500 As_DispRq 64;
BA_ "FlexKomSigStartPos" SG_ 500 As_DispRq 7;
BA_ "FlexKomSID" SG_ 500 As_DispRq 1043;
BA_ "GenSigTimeout_ORC" SG_ 500 As_DispRq 70;
BA_ "GenSigTimeout_IC" SG_ 500 As_DispRq 210;
BA_ "FlexKomSigStartValue" SG_ 500 As_DispRq "1FFF0CCB000000FFh";
BA_ "GenSigCycleTime" SG_ 500 As_DispRq 20;
BA_ "GenSigSNA" SG_ 500 ACCFCW_ChimeRq "0h";
BA_ "FlexKomIsMotorola" SG_ 500 ACCFCW_ChimeRq 1;
BA_ "FlexKomComment" SG_ 500 ACCFCW_ChimeRq "DAS_A3_PKT";
BA_ "FlexKomSigName" SG_ 500 ACCFCW_ChimeRq "DAS_A3_PKT";
BA_ "FlexKomSigLaenge" SG_ 500 ACCFCW_ChimeRq 64;
BA_ "FlexKomSigStartPos" SG_ 500 ACCFCW_ChimeRq 7;
BA_ "FlexKomSID" SG_ 500 ACCFCW_ChimeRq 1043;
BA_ "GenSigTimeout_IC" SG_ 500 ACCFCW_ChimeRq 210;
BA_ "FlexKomSigStartValue" SG_ 500 ACCFCW_ChimeRq "1FFF0CCB000000FFh";
BA_ "GenSigCycleTime" SG_ 500 ACCFCW_ChimeRq 20;
BA_ "GenSigSNA" SG_ 500 ACC_Still_Cmd "0h";
BA_ "FlexKomIsMotorola" SG_ 500 ACC_Still_Cmd 1;
BA_ "FlexKomComment" SG_ 500 ACC_Still_Cmd "DAS_A3_PKT";
BA_ "FlexKomSigName" SG_ 500 ACC_Still_Cmd "DAS_A3_PKT";
BA_ "FlexKomSigLaenge" SG_ 500 ACC_Still_Cmd 64;
BA_ "FlexKomSigStartPos" SG_ 500 ACC_Still_Cmd 7;
BA_ "FlexKomSID" SG_ 500 ACC_Still_Cmd 1043;
BA_ "GenSigTimeout_ORC" SG_ 500 ACC_Still_Cmd 70;
BA_ "FlexKomSigStartValue" SG_ 500 ACC_Still_Cmd "1FFF0CCB000000FFh";
BA_ "GenSigCycleTime" SG_ 500 ACC_Still_Cmd 20;
BA_ "GenSigSNA" SG_ 500 ACC_Engd "0h";
BA_ "FlexKomIsMotorola" SG_ 500 ACC_Engd 1;
BA_ "FlexKomComment" SG_ 500 ACC_Engd "DAS_A3_PKT";
BA_ "FlexKomSigName" SG_ 500 ACC_Engd "DAS_A3_PKT";
BA_ "FlexKomSigLaenge" SG_ 500 ACC_Engd 64;
BA_ "FlexKomSigStartPos" SG_ 500 ACC_Engd 7;
BA_ "FlexKomSID" SG_ 500 ACC_Engd 1043;
BA_ "GenSigTimeout_ORC" SG_ 500 ACC_Engd 70;
BA_ "GenSigTimeout_IC" SG_ 500 ACC_Engd 210;
BA_ "FlexKomSigStartValue" SG_ 500 ACC_Engd "1FFF0CCB000000FFh";
BA_ "GenSigCycleTime" SG_ 500 ACC_Engd 20;
BA_ "GenSigSNA" SG_ 500 ACC_Enbl "0h";
BA_ "FlexKomIsMotorola" SG_ 500 ACC_Enbl 1;
BA_ "FlexKomComment" SG_ 500 ACC_Enbl "DAS_A3_PKT";
BA_ "FlexKomSigName" SG_ 500 ACC_Enbl "DAS_A3_PKT";
BA_ "FlexKomSigLaenge" SG_ 500 ACC_Enbl 64;
BA_ "FlexKomSigStartPos" SG_ 500 ACC_Enbl 7;
BA_ "FlexKomSID" SG_ 500 ACC_Enbl 1043;
BA_ "GenSigTimeout_ORC" SG_ 500 ACC_Enbl 70;
BA_ "GenSigTimeout_IC" SG_ 500 ACC_Enbl 210;
BA_ "FlexKomSigStartValue" SG_ 500 ACC_Enbl "1FFF0CCB000000FFh";
BA_ "GenSigCycleTime" SG_ 500 ACC_Enbl 20;
BA_ "GenSigSNA" SG_ 500 ACC_Drive_Cmd "0h";
BA_ "FlexKomIsMotorola" SG_ 500 ACC_Drive_Cmd 1;
BA_ "FlexKomComment" SG_ 500 ACC_Drive_Cmd "DAS_A3_PKT";
BA_ "FlexKomSigName" SG_ 500 ACC_Drive_Cmd "DAS_A3_PKT";
BA_ "FlexKomSigLaenge" SG_ 500 ACC_Drive_Cmd 64;
BA_ "FlexKomSigStartPos" SG_ 500 ACC_Drive_Cmd 7;
BA_ "FlexKomSID" SG_ 500 ACC_Drive_Cmd 1043;
BA_ "GenSigTimeout_ORC" SG_ 500 ACC_Drive_Cmd 70;
BA_ "FlexKomSigStartValue" SG_ 500 ACC_Drive_Cmd "1FFF0CCB000000FFh";
BA_ "GenSigCycleTime" SG_ 500 ACC_Drive_Cmd 20;
VAL_ 680 TX_WARN2 23 "WARN_23" 255 "SNA" 22 "WARN_22" 21 "WARN_21" 20 "WARN_20" 19 "WARN_19" 18 "WARN_18" 17 "WARN_17" 15 "WARN_15" 14 "WARN_14" 13 "WARN_13" 12 "WARN_12" 11 "WARN_11" 10 "WARN_10" 9 "WARN_9" 8 "WARN_8" 7 "WARN_7" 6 "WARN_6" 5 "WARN_5" 4 "WARN_4" 3 "WARN_3" 2 "WARN_2" 1 "WARN_1" 0 "None" ;
VAL_ 680 TCM_Vehicle_Hold_Rq 3 "SNA" 1 "ACTIVE" 0 "NA" ;
VAL_ 680 TargetGear 15 "SNA" 14 "ABBRUCH" 13 "P" 12 "R2" 11 "R" 10 "D9" 9 "D2P" 8 "D8" 7 "D7" 6 "D6" 5 "D5" 4 "D4" 3 "D3" 2 "D2" 1 "D1" 0 "N" ;
VAL_ 680 HCPShutDwnCmd 7 "SNA" 3 "Cancel_Powerdown" 2 "Shutdown" 1 "Initiate_Powerdown" 0 "default" ;
VAL_ 680 HCP_IMMO_STAT_CANC 3 "SNA" 2 "HCPRUN" 1 "HCPKILL" 0 "HCPIS" ;
VAL_ 680 CurrentGear 15 "SNA" 14 "KRAFTFREI" 13 "P" 12 "R2" 11 "R" 10 "D9" 9 "D2P" 8 "D8" 7 "D7" 6 "D6" 5 "D5" 4 "D4" 3 "D3" 2 "D2" 1 "D1" 0 "N" ;
VAL_ 678 TrqIntensitySts 7 "SNA" 3 "T3" 2 "T2" 1 "T1" 0 "OFF" ;
VAL_ 678 SensitivitySts 7 "SNA" 5 "S5" 4 "S4" 3 "S3" 2 "S2" 1 "S1" 0 "OFF" ;
VAL_ 678 ISO_TelltaleSts 7 "SNA" 4 "YELLOW_F" 3 "YELLOW" 2 "GREEN" 1 "WHITE" 0 "OFF" ;
VAL_ 678 HALF_CHIME_TYPESts 15 "SNA" 6 "HALF" 0 "NONE" ;
VAL_ 678 DispPopupSts 255 "SNA" 22 "MESS22" 21 "MESS21" 20 "MESS20" 19 "MESS19" 18 "MESS18" 17 "MESS17" 16 "MESS16" 15 "MESS15" 14 "MESS14" 13 "MESS13" 12 "MESS12" 11 "MESS11" 10 "MESS10" 9 "MESS9" 8 "MESS8" 7 "MESS7" 6 "MESS6" 5 "MESS5" 4 "MESS4" 3 "MESS3" 2 "MESS2" 1 "MESS1" 0 "NONE" ;
VAL_ 678 DisplaySts 255 "SNA" 240 "MESS27" 161 "MESS26" 160 "MESS25" 108 "MESS24" 107 "MESS23" 106 "MESS22" 105 "ESS21" 104 "MESS20" 103 "ESS19" 102 "MESS18" 101 "ESS17" 100 "ESS16" 99 "MESS15" 98 "MESS14" 97 "MESS13" 12 "MESS12" 11 "MESS11" 10 "MESS10" 9 "MESS9" 8 "MESS8" 7 "MESS7" 6 "MESS6" 5 "MESS5" 4 "MESS4" 3 "MESS3" 2 "MESS2" 1 "MESS1" 0 "OFF" ;
VAL_ 672 OIL_TEMP_IND_RQ 3 "SNA" 2 "IND_LMP_FLASH" 1 "IND_LMP_ON" 0 "IND_LMP_OFF" ;
VAL_ 672 OIL_TEMP_CHM_RQ 3 "FAST_CHM" 2 "SLOW_CHM" 1 "1_CHM" 0 "NO_CHM" ;
VAL_ 672 OIL_PRESS 255 "SNA" ;
VAL_ 672 FuelCons 65535 "SNA" ;
VAL_ 672 ETC_IND_LMP 3 "SNA" 2 "ON_Flashing" 1 "ON" 0 "OFF" ;
VAL_ 672 EngRun_Stat 7 "SNA" 6 "NDEF6" 5 "LIMITED" 4 "UNLIMITED" 3 "IDLE_STBL" 2 "IDLE_UNSTBL" 1 "START" 0 "STOP" ;
VAL_ 672 EngOilTemp 255 "SNA" ;
VAL_ 672 EngOilIndLmp_On_Rq 1 "SNA" ;
VAL_ 672 DefFuelEcon 255 "SNA" ;
VAL_ 671 PTS_ManoeuvreMode 7 "SNA" 4 "OVER" 3 "PULL_OUT" 2 "PERP" 1 "PARA" 0 "None" ;
VAL_ 660 TOC_Sts 15 "SNA" 7 "TOC_UCF" 6 "TOC_OCF" 5 "TOC_MCF" 3 "TOC_Ready" 2 "TOC_PNA" 1 "TOC_TNA" 0 "TOC_Deactivation" ;
VAL_ 660 TOC_Fault 3 "SNA" 1 "FAULT" 0 "AVAIL" ;
VAL_ 660 TOC_Act_Req 3 "SNA" 1 "ACTIVE" 0 "NOT" ;
VAL_ 660 TO_Req 2047 "SNA" ;
VAL_ 660 SyncPos 7 "SNA" 4 "NS" 3 "TEMP" 2 "PRESS" 1 "HIGH" 0 "LOW" ;
VAL_ 658 MTO_HALFDriveStyleSts 7 "SNA" 5 "TRACPLUS" 4 "SPORT_PLUS" 3 "WINTER" 2 "SPORT" 1 "CITY" 0 "NORMAL" ;
VAL_ 653 BrakePedalTravelSensor 255 "SNA" ;
VAL_ 639 IBS_Tm_Lst_Reset_Sec 65535 "SNA" ;
VAL_ 639 IBS_Tm_Lst_Reset_Days 4095 "SNA" ;
VAL_ 639 IBS_Q_released 65535 "SNA" ;
VAL_ 639 IBS_Q_received 65535 "SNA" ;
VAL_ 632 SpStWarnStat 15 "SNA" 14 "Park_Inhib" 13 "PSG_DR_INHIB" 12 "Hood_Inhib" 11 "Prk_Brk_Inhib" 10 "SYSFLT" 9 "BATT" 8 "KEY" 7 "TX_INHIB" 6 "DR_INHIB" 5 "D_AND_SB" 4 "D_OR_SB" 3 "ACTIVE" 2 "START" 1 "STARTING" 0 "NONE" ;
VAL_ 632 SpStSwStat 3 "SNA" 2 "BLINK" 1 "CONT" 0 "OFF" ;
VAL_ 632 SpStDispstat 63 "SNA" 40 "OFF_ROAD2" 39 "OFF_ROAD1" 38 "BATT_HIGH" 37 "ACC_SET" 36 "PSG_DR_INHIB" 35 "DPF_Regen" 34 "Hood_Inhib" 33 "Park_Inhib" 32 "Prk_Brk_Inhib" 31 "Eng_Temp_Lo" 30 "Eng_Temp_Hi" 29 "ST_WHEEL" 28 "EBL" 27 "FT_DEFROST" 26 "MAX_HVAC" 25 "CABIN" 24 "DR_AJAR" 23 "SB" 22 "ENG_TEMP" 21 "AMB_TEMP" 20 "INCLINE" 19 "LF" 18 "T4WD_L" 17 "TM" 16 "BATT_CHG" 15 "PEDAL" 14 "HOOD" 13 "OFF" 12 "READY" 11 "NR" 10 "SYSFLT" 9 "BATT" 8 "KEY" 7 "TX_INHIB" 6 "DR_INHIB" 5 "D_AND_SB" 4 "D_OR_SB" 3 "ACTIVE" 2 "START" 1 "STARTING" 0 "NONE" ;
VAL_ 632 CC_SetSpdDsplMPH 255 "SNA" ;
VAL_ 632 CC_SetSpdDspl 255 "SNA" ;
VAL_ 625 WhlTrqRq_DAS 32767 "SNA" ;
VAL_ 625 FCWSettingTeen 3 "FAR" 2 "MEDIUM" 1 "NEAR" 0 "OFF" ;
VAL_ 625 FCWSetting 3 "FAR" 2 "MEDIUM" 1 "NEAR" 0 "OFF" ;
VAL_ 624 R_R_Req_PE 3 "HF_PE_REQ" 2 "BTN_PE_REQ" 1 "HNDL_PE_REQ" 0 "NO_REQ" ;
VAL_ 624 L_R_Req_PE 3 "HF_PE_REQ" 2 "BTN_PE_REQ" 1 "HNDL_PE_REQ" 0 "NO_REQ" ;
VAL_ 624 Gate_Req_PE 3 "HF_PE_REQ" 2 "BTN_PE_REQ" 1 "HNDL_PE_REQ" 0 "NO_REQ" ;
VAL_ 624 EngineOffTimer 4095 "SNA" ;
VAL_ 608 RR_PTS_Dist 255 "SNA" ;
VAL_ 608 PTS_RR_VOL_TeenKey 3 "SNA" 2 "HIGH" 1 "MED" 0 "LOW" ;
VAL_ 608 PTS_PopUpRqst 255 "SNA" 100 "TM100" 99 "TM99" 98 "TM98" 97 "TM97" 96 "TM96" 95 "TM95" 94 "TM94" 93 "TM93" 92 "TM92" 91 "TM91" 90 "TM90" 89 "TM89" 88 "TM88" 87 "TM87" 86 "TM86" 85 "TM85" 84 "TM84" 83 "TM83" 82 "TM82" 81 "TM81" 80 "TM80" 79 "TM79" 78 "TM78" 77 "TM77" 76 "TM76" 75 "TM75" 74 "TM74" 73 "TM73" 72 "TM72" 71 "TM71" 70 "TM70" 69 "TM69" 68 "TM68" 67 "TM67" 66 "TM66" 65 "TM65" 64 "TM64" 63 "TM63" 62 "TM62" 61 "TM61" 60 "TM60" 59 "TM59" 58 "TM58" 57 "TM57" 56 "TM56" 55 "TM55" 54 "TM54" 53 "TM53" 52 "TM52" 51 "TM51" 50 "TM50" 49 "TM49" 48 "TM48" 47 "TM47" 46 "TM46" 45 "TM45" 44 "TM44" 43 "TM43" 42 "TM42" 41 "TM41" 40 "TM40" 39 "TM39" 38 "TM38" 37 "TM37" 36 "TM36" 35 "TM35" 34 "TM34" 33 "TM33" 32 "TM32" 31 "TM31" 30 "TM30" 29 "TM29" 28 "TM28" 27 "TM27" 26 "TM26" 25 "TM25" 24 "TM24" 23 "TM23" 22 "TM22" 21 "TM21" 20 "TM20" 19 "TM19" 18 "TM18" 17 "TM17" 16 "TM16" 15 "TM15" 14 "TM14" 13 "TM13" 12 "TM12" 11 "TM11" 10 "TM10" 9 "TM9" 8 "TM8" 7 "TM7" 6 "TM6" 5 "TM5" 4 "TM4" 3 "TM3" 2 "TM2" 1 "TM1" 0 "TM0" ;
VAL_ 608 PTS_FT_VOL_TeenKey 3 "SNA" 2 "HIGH" 1 "MED" 0 "LOW" ;
VAL_ 608 PTS_CFG_STAT_TeenKey 3 "SNA" 2 "SND_DISP" 1 "SND" 0 "OFF" ;
VAL_ 584 IBS_SOH_Q_Accuracy 3 "SNA" 2 "ACCURACY_2" 1 "ACCURACY_1" 0 "ACCURACY_0" ;
VAL_ 584 IBS_SOH_Q 255 "SNA" ;
VAL_ 584 IBS_SOF_t_Accuracy 3 "SNA" 2 "ACCURACY_2" 1 "ACCURACY_1" 0 "ACCURACY_0" ;
VAL_ 584 IBS_SOF_t 1023 "SNA" ;
VAL_ 584 IBS_SOF_Q_Accuracy 3 "SNA" 2 "ACCURACY_2" 1 "ACCURACY_1" 0 "ACCURACY_0" ;
VAL_ 584 IBS_SOF_Q 255 "SNA" ;
VAL_ 584 IBS_SOC_Accuracy 3 "SNA" 2 "ACCURACY_2" 1 "ACCURACY_1" 0 "ACCURACY_0" ;
VAL_ 584 IBS_SOC 255 "SNA" ;
VAL_ 564 IBS_SOF_V1 255 "SNA" ;
VAL_ 564 IBS_SOF_V_Accuracy 3 "SNA" 2 "ACCURACY_2" 1 "ACCURACY_1" 0 "ACCURACY_0" ;
VAL_ 564 IBS_SOF_V 255 "SNA" ;
VAL_ 564 AM_ECM_Trace 3 "SNA" 2 "AM_ECM_TRACE" 0 "DEFAULT" ;
VAL_ 560 EvapTempTar 255 "SNA" ;
VAL_ 560 EVAP_TEMP 255 "SNA" ;
VAL_ 560 AC_SEL 0 "SNA" ;
VAL_ 560 AC_RQ 0 "SNA" ;
VAL_ 559 ActlAccelPdlPosn 255 "SNA" ;
VAL_ 557 Command_15 3 "SNA" 1 "PSD" 0 "NOT_PSD" ;
VAL_ 557 Command_14 3 "SNA" 1 "PSD" 0 "NOT_PSD" ;
VAL_ 557 Command_13 3 "SNA" 1 "PSD" 0 "NOT_PSD" ;
VAL_ 557 Command_12 3 "SNA" 1 "PSD" 0 "NOT_PSD" ;
VAL_ 557 Command_11 3 "SNA" 1 "PSD" 0 "NOT_PSD" ;
VAL_ 544 TOI_Act_Sts 15 "SNA" 8 "INACT" 7 "DST_TOI_UCF" 6 "DST_TOI_OCF" 5 "DST_TOI_MCF" 4 "DENIED" 3 "READY" 2 "DST_TOI_PNA" 1 "DST_TOI_TNA" 0 "TOI_DEACT" ;
VAL_ 544 StrClmTrqVD 0 "SNA" ;
VAL_ 544 StrClmTrq 2047 "SNA" ;
VAL_ 544 AssistanceTorque 4095 "SNA" ;
VAL_ 532 IBS_Voltage_Status 3 "SATURATED" 2 "HW_DEFECT" 1 "OPEN_CKT" 0 "NO_ERROR" ;
VAL_ 532 IBS_V_BATT 16383 "SNA" ;
VAL_ 532 IBS_Temp_Status 3 "SATURATED" 2 "HW_DEFECT" 1 "OPEN_CKT" 0 "NO_ERROR" ;
VAL_ 532 IBS_T_BATT 255 "SNA" ;
VAL_ 532 IBS_PreWakeupVoltage 1023 "SNA" ;
VAL_ 532 IBS_I_RANGE 3 "SNA" 2 "Range_I1500" 1 "Range_I200" 0 "Range_I1" ;
VAL_ 532 IBS_I_BATT 65535 "SNA" ;
VAL_ 532 IBS_Current_Status 3 "SATURATED" 2 "HW_DEFECT" 1 "OPEN_CKT" 0 "NO_ERROR" ;
VAL_ 520 RefuelRequest 3 "SNA" 1 "REFUEL" 0 "NO" ;
VAL_ 520 PsngrDoorAjarXtionSts 3 "SNA" 2 "TRNS" 1 "NONE" ;
VAL_ 520 PsngrDoorAjarRawValSts 15 "SNA" 14 "FH_SSE" 13 "FH_SSD" 12 "FH_SSC" 11 "FH_SSB" 10 "FH_SSA" 9 "CLOSED_SSB" 8 "CLOSED_SSA" 7 "OPEN_SSB" 6 "OPEN_SSA" 5 "FL_SSE" 4 "FL_SSD" 3 "FL_SSC" 2 "FL_SSB" 1 "FL_SSA" 0 "DEFAULT" ;
VAL_ 520 LeakCheckTimerExpired 3 "SNA" 1 "ELAPSED" 0 "NOT" ;
VAL_ 520 FuelDrRelSwRawSt 255 "SNA" ;
VAL_ 520 DriverDoorAjarXtionSts 3 "SNA" 2 "TRNS" 1 "NONE" ;
VAL_ 520 DriverDoorAjarRawValSts 15 "SNA" 14 "FH_SSE" 13 "FH_SSD" 12 "FH_SSC" 11 "FH_SSB" 10 "FH_SSA" 9 "CLOSED_SSB" 8 "CLOSED_SSA" 7 "OPEN_SSB" 6 "OPEN_SSA" 5 "FL_SSE" 4 "FL_SSD" 3 "FL_SSC" 2 "FL_SSB" 1 "FL_SSA" 0 "DEFAULT" ;
VAL_ 520 DriverDoor2AjarXtionSts 3 "SNA" 2 "TRNS" 1 "NONE" ;
VAL_ 520 DriverDoor2AjarRawValSts 15 "SNA" 14 "FH_SSE" 13 "FH_SSD" 12 "FH_SSC" 11 "FH_SSB" 10 "FH_SSA" 9 "CLOSED_SSB" 8 "CLOSED_SSA" 7 "OPEN_SSB" 6 "OPEN_SSA" 5 "FL_SSE" 4 "FL_SSD" 3 "FL_SSC" 2 "FL_SSB" 1 "FL_SSA" 0 "DEFAULT" ;
VAL_ 520 BrkPdlStat_CBC 3 "SNA" 2 "NDEF2" 1 "PSD" 0 "UPSTOP" ;
VAL_ 520 BonnetAjarRawValSts 15 "SNA" 14 "FH_SSE" 13 "FH_SSD" 12 "FH_SSC" 11 "FH_SSB" 10 "FH_SSA" 9 "CLOSED_SSB" 8 "CLOSED_SSA" 7 "OPEN_SSB" 6 "OPEN_SSA" 5 "FL_SSE" 4 "FL_SSD" 3 "FL_SSC" 2 "FL_SSB" 1 "FL_SSA" 0 "DEFAULT" ;
VAL_ 514 WheelRPM_FR 65535 "SNA" ;
VAL_ 514 WheelRPM_FL 65535 "SNA" ;
VAL_ 512 FUEL_VOLT2 255 "SNA" ;
VAL_ 512 FUEL_VOLT 255 "SNA" ;
VAL_ 512 BATT_VOLT 255 "SNA" ;
VAL_ 512 AMB_TEMP_VOLT 255 "SNA" ;
VAL_ 512 AMB_TEMP_AVG 65535 "SNA" ;
VAL_ 512 AirTemp_Outsd 255 "SNA" ;
VAL_ 501 Sm_ICON_Dspl 63 "SNA" 40 "NCC_ENGAGED" 34 "NCC_READY" 33 "NCC_OFF" 15 "ACC_E_WT_TG4" 14 "ACC_E_WT_TG3" 13 "ACC_E_WT_TG2" 12 "ACC_E_WT_TG1" 11 "ACC_E_NT_TG4" 10 "ACC_E_NT_TG3" 9 "ACC_E_NT_TG2" 8 "ACC_E_NT_TG1" 5 "READY_TG4" 4 "READY_TG3" 3 "READY_TG2" 2 "READY_TG1" 1 "OFF" 0 "NONE" ;
VAL_ 501 SetSpeed_MPH 255 "SNA" ;
VAL_ 501 SetSpeed_KPH 255 "SNA" ;
VAL_ 501 ObjIntrstDist 255 "SNA" ;
VAL_ 501 HMI_Screens 255 "SNA" ;
VAL_ 501 FCW_Error 3 "SNA" 2 "Limited_FCW" 1 "FCW_Error" 0 "No_Error" ;
VAL_ 501 ACCOnOff 7 "SNA" 4 "ACC_SET" 3 "ACC_ON" 2 "NCC_SET" 1 "NCC" 0 "OFF" ;
VAL_ 500 DAS_Sts 3 "SNA" 2 "EXTERNAL" 1 "INTERNAL" 0 "OK" ;
VAL_ 500 DAS_Rq_ID 5 "CMS_XTD" 7 "SNA" 4 "LSCM" 3 "ABA" 2 "CMS" 1 "ACC" 0 "IDLE" ;
VAL_ 500 DAS_ACCEL_Rq 4095 "SNA" ;
VAL_ 500 As_DispRq 3 "SNA" 2 "FCW" 1 "ACC" 0 "No_RQ" ;
